VERSION ""

NS_ :

BS_:

BU_: ABS_BASE ATCM_DMSM GENERIC_GWMWakeup PBM IPMB TCU_TBS FDSM GSM TRCM GWM _delete ABS_ESC HUD IPMA CCM SASM PSCM SCCM HCM ATCM SUMA_RLM ATCM_FFSM PCU SECM VDM TBM OCS GENERIC TCCM TSTR RCM

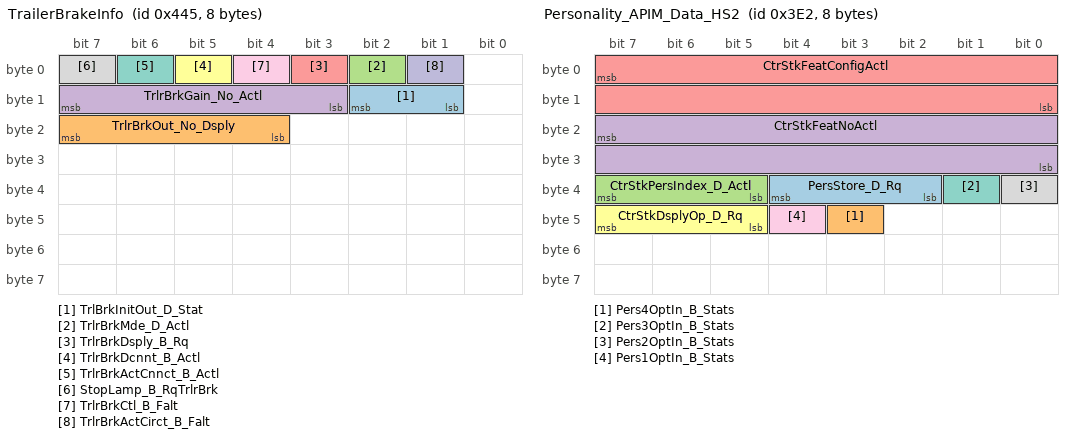
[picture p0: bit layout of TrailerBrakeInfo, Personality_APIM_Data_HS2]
BO_ 1093 TrailerBrakeInfo: 8 TBM
 SG_ TrlBrkInitOut_D_Stat : 10|2@0+ (1,0) [0|3] "SED"  GWM
 SG_ TrlrBrkOut_No_Dsply : 23|4@0+ (1,0) [0|15] "unitless"  GWM
 SG_ TrlrBrkMde_D_Actl : 2|1@0+ (1,0) [0|1] "SED"  GWM,TCCM
 SG_ TrlrBrkGain_No_Actl : 15|5@0+ (0.5,0) [0|15.5] "unitless"  GWM
 SG_ TrlrBrkDsply_B_Rq : 3|1@0+ (1,0) [0|1] "SED"  GWM
 SG_ TrlrBrkDcnnt_B_Actl : 5|1@0+ (1,0) [0|1] "SED"  GWM,VDM
 SG_ TrlrBrkActCnnct_B_Actl : 6|1@0+ (1,0) [0|1] "SED"  ABS_BASE,TCCM,PSCM,SCCM,ABS_ESC,GWM,VDM
 SG_ StopLamp_B_RqTrlrBrk : 7|1@0+ (1,0) [0|1] "SED"  GWM
 SG_ TrlrBrkCtl_B_Falt : 4|1@0+ (1,0) [0|1] "SED"  GWM
 SG_ TrlrBrkActCirct_B_Falt : 1|1@0+ (1,0) [0|1] "SED"  GWM

BO_ 994 Personality_APIM_Data_HS2: 8 GWM
 SG_ PersStore_D_Rq : 36|3@0+ (1,0) [0|7] "SED"  GENERIC
 SG_ Pers4OptIn_B_Stats : 43|1@0+ (1,0) [0|1] "SED"  GENERIC
 SG_ CtrStkPersIndex_D_Actl : 39|3@0+ (1,0) [0|7] "SED"  SASM,CCM,IPMA,IPMB,SCCM,VDM,HCM
 SG_ CtrStkFeatNoActl : 23|16@0+ (1,0) [0|65535] "Undefined"  SASM,CCM,IPMA,IPMB,SCCM,VDM,HCM
 SG_ CtrStkFeatConfigActl : 7|16@0+ (1,0) [0|65535] "Undefined"  SASM,CCM,IPMA,IPMB,SCCM,VDM,HCM
 SG_ CtrStkDsplyOp_D_Rq : 47|3@0+ (1,0) [0|7] "SED"  SASM,CCM,IPMA,IPMB,SCCM,VDM,HCM
 SG_ Pers3OptIn_B_Stats : 33|1@0+ (1,0) [0|1] "SED"  GENERIC
 SG_ Pers2OptIn_B_Stats : 32|1@0+ (1,0) [0|1] "SED"  GENERIC
 SG_ Pers1OptIn_B_Stats : 44|1@0+ (1,0) [0|1] "SED"  GENERIC

BO_ 1836 TesterPhysicalResSCCM: 8 SCCM
 SG_ TesterPhysicalResSCCM : 7|64@0+ (1,0) [0|1.84467E+019] "unitless"  TSTR

BO_ 1978 TesterPhysicalResHUD: 8 HUD
 SG_ TesterPhysicalResHUD : 7|64@0+ (1,0) [0|1.84467E+019] "unitless"  TSTR

BO_ 1825 TesterPhysicalReqVDM: 8 TSTR
 SG_ TesterPhysicalReqVDM : 7|64@0+ (1,0) [0|1.84467E+019] "unitless"  VDM

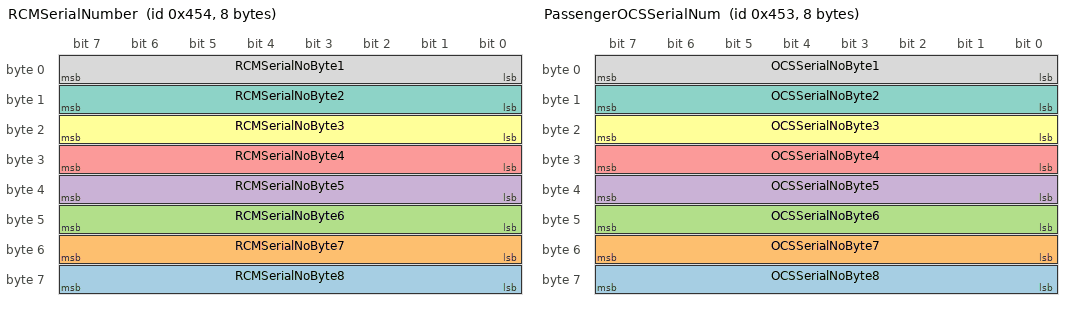
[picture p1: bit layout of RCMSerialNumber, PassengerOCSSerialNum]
BO_ 1108 RCMSerialNumber: 8 RCM
 SG_ RCMSerialNoByte8 : 63|8@0+ (1,0) [0|253] "Unitless"  ABS_BASE,ABS_ESC,OCS
 SG_ RCMSerialNoByte7 : 55|8@0+ (1,0) [0|253] "Unitless"  ABS_BASE,ABS_ESC,OCS
 SG_ RCMSerialNoByte6 : 47|8@0+ (1,0) [0|253] "Unitless"  ABS_BASE,ABS_ESC,OCS
 SG_ RCMSerialNoByte5 : 39|8@0+ (1,0) [0|253] "Unitless"  ABS_BASE,ABS_ESC,OCS
 SG_ RCMSerialNoByte4 : 31|8@0+ (1,0) [0|253] "Unitless"  ABS_BASE,ABS_ESC,OCS
 SG_ RCMSerialNoByte3 : 23|8@0+ (1,0) [0|253] "Unitless"  ABS_BASE,ABS_ESC,OCS
 SG_ RCMSerialNoByte2 : 15|8@0+ (1,0) [0|253] "Unitless"  ABS_BASE,ABS_ESC,OCS
 SG_ RCMSerialNoByte1 : 7|8@0+ (1,0) [0|253] "Unitless"  ABS_BASE,ABS_ESC,OCS

BO_ 1107 PassengerOCSSerialNum: 8 OCS
 SG_ OCSSerialNoByte8 : 63|8@0+ (1,0) [0|253] "Unitless"  RCM
 SG_ OCSSerialNoByte7 : 55|8@0+ (1,0) [0|253] "Unitless"  RCM
 SG_ OCSSerialNoByte6 : 47|8@0+ (1,0) [0|253] "Unitless"  RCM
 SG_ OCSSerialNoByte5 : 39|8@0+ (1,0) [0|253] "Unitless"  RCM
 SG_ OCSSerialNoByte4 : 31|8@0+ (1,0) [0|253] "Unitless"  RCM
 SG_ OCSSerialNoByte3 : 23|8@0+ (1,0) [0|253] "Unitless"  RCM
 SG_ OCSSerialNoByte2 : 15|8@0+ (1,0) [0|253] "Unitless"  RCM
 SG_ OCSSerialNoByte1 : 7|8@0+ (1,0) [0|253] "Unitless"  RCM

BO_ 1848 TesterPhysicalResPSCM: 8 PSCM
 SG_ TesterPhysicalResPSCM : 7|64@0+ (1,0) [0|1.84467E+019] "unitless"  TSTR

BO_ 1900 TesterPhysicalResCCM: 8 IPMA
 SG_ TesterPhysicalResCCM : 7|64@0+ (1,0) [0|1.84467E+019] "unitless"  TSTR

BO_ 1892 TesterPhysicalReqCCM: 8 TSTR
 SG_ TesterPhysicalReqCCM : 7|64@0+ (1,0) [0|1.84467E+019] "unitless"  IPMA,CCM

BO_ 1879 TesterPhysicalReqTBM: 8 TSTR
 SG_ TesterPhysicalReqTBM : 7|64@0+ (1,0) [0|1.84467E+019] "unitless"  TBM

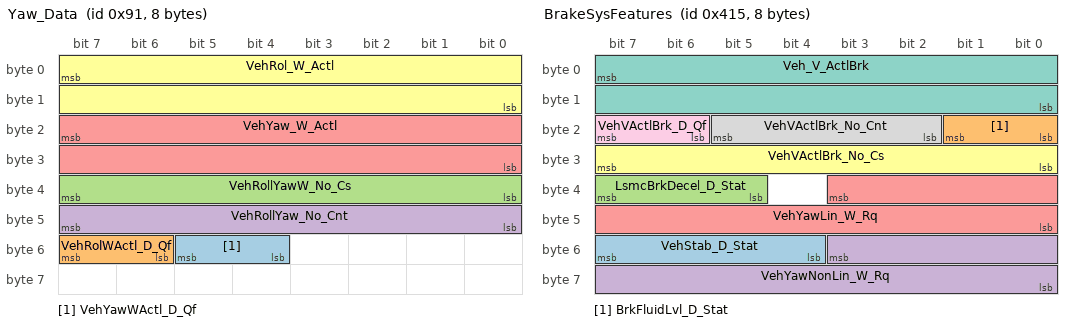
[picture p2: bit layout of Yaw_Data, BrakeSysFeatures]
BO_ 145 Yaw_Data: 8 RCM
 SG_ VehYawWActl_D_Qf : 53|2@0+ (1,0) [0|3] "SED"  HCM,ABS_BASE,GWM,IPMA,VDM,FDSM,ABS_ESC
 SG_ VehRolWActl_D_Qf : 55|2@0+ (1,0) [0|3] "SED"  ABS_BASE,GWM,VDM,ABS_ESC
 SG_ VehRollYawW_No_Cs : 39|8@0+ (1,0) [0|255] "Unitless"  ABS_BASE,GWM,ABS_ESC
 SG_ VehRollYaw_No_Cnt : 47|8@0+ (1,0) [0|255] "Unitless"  ABS_BASE,GWM,VDM,ABS_ESC
 SG_ VehYaw_W_Actl : 23|16@0+ (0.0002,-6.5) [-6.5|6.6066] "rad/s"  ABS_BASE,IPMB,HCM,VDM,PSCM,FDSM,CCM,ABS_ESC,IPMA,GWM
 SG_ VehRol_W_Actl : 7|16@0+ (0.0002,-6.5) [-6.5|6.6066] "rad/s"  ABS_BASE,PSCM,VDM,ABS_ESC,GWM

BO_ 1828 TesterPhysicalReqSCCM: 8 TSTR
 SG_ TesterPhysicalReqSCCM : 7|64@0+ (1,0) [0|1.84467E+019] "unitless"  SCCM

BO_ 1970 TesterPhysicalReqHUD: 8 TSTR
 SG_ TesterPhysicalReqHUD : 7|64@0+ (1,0) [0|1.84467E+019] "unitless"  HUD

BO_ 1045 BrakeSysFeatures: 8 ABS_ESC
 SG_ VehStab_D_Stat : 55|4@0+ (1,0) [0|15] "SED"  TCCM,GWM
 SG_ BrkFluidLvl_D_Stat : 17|2@0+ (1,0) [0|3] "SED"  GWM
 SG_ LsmcBrkDecel_D_Stat : 39|3@0+ (1,0) [0|7] "SED"  GWM,PSCM
 SG_ VehYawNonLin_W_Rq : 51|12@0+ (0.03663,-75) [-75|74.92659] "deg/s"  GWM
 SG_ VehYawLin_W_Rq : 35|12@0+ (0.03663,-75) [-75|74.92659] "deg/s"  GWM
 SG_ VehVActlBrk_No_Cs : 31|8@0+ (1,0) [0|255] "Unitless"  PSCM,SASM,GWM
 SG_ Veh_V_ActlBrk : 7|16@0+ (0.01,0) [0|655.35] "kph"  SCCM,PSCM,SASM,GSM,TRCM,GWM
 SG_ VehVActlBrk_No_Cnt : 21|4@0+ (1,0) [0|15] "Unitless"  PSCM,SASM,GWM
 SG_ VehVActlBrk_D_Qf : 23|2@0+ (1,0) [0|3] "SED"  PSCM,SASM,GSM,TRCM,GWM

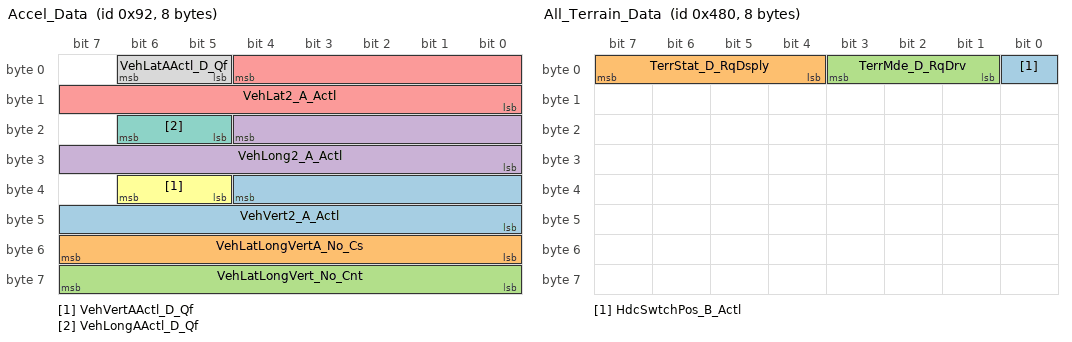
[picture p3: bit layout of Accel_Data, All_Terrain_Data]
BO_ 146 Accel_Data: 8 RCM
 SG_ VehVert2_A_Actl : 36|13@0+ (0.01,-40) [-40|41.89] "m/s^2"  ABS_BASE,ABS_ESC,VDM,GWM
 SG_ VehLatLongVertA_No_Cs : 55|8@0+ (1,0) [0|255] "Unitless"  ABS_BASE,GWM,ABS_ESC,PSCM
 SG_ VehLatLongVert_No_Cnt : 63|8@0+ (1,0) [0|255] "Unitless"  ABS_BASE,GWM,ABS_ESC,PSCM,VDM
 SG_ VehLong2_A_Actl : 20|13@0+ (0.01,-40) [-40|41.89] "m/s^2"  ABS_BASE,GWM,VDM,OCS,IPMA,CCM,ABS_ESC
 SG_ VehLat2_A_Actl : 4|13@0+ (0.01,-40) [-40|41.89] "m/s^2"  ABS_BASE,ABS_ESC,IPMB,CCM,IPMA,OCS,PSCM,VDM,GWM
 SG_ VehVertAActl_D_Qf : 38|2@0+ (1,0) [0|3] "SED"  ABS_ESC,ABS_BASE,GWM,VDM
 SG_ VehLongAActl_D_Qf : 22|2@0+ (1,0) [0|3] "SED"  ABS_BASE,CCM,OCS,VDM,GWM,IPMA,ABS_ESC
 SG_ VehLatAActl_D_Qf : 6|2@0+ (1,0) [0|3] "SED"  ABS_BASE,OCS,VDM,PSCM,IPMA,GWM,ABS_ESC,CCM

BO_ 1152 All_Terrain_Data: 8 ATCM
 SG_ HdcSwtchPos_B_Actl : 0|1@0+ (1,0) [0|1] "SED"  ABS_BASE,ABS_ESC
 SG_ TerrStat_D_RqDsply : 7|4@0+ (1,0) [0|15] "SED"  GWM
 SG_ TerrMde_D_RqDrv : 3|3@0+ (1,0) [0|7] "SED"  ABS_BASE,TCCM,ABS_ESC,GWM

BO_ 1938 TesterPhysicalReqATCM: 8 TSTR
 SG_ TesterPhysicalReqATCM : 7|64@0+ (1,0) [0|1.84467E+019] "unitless"  ATCM_FFSM,ATCM_DMSM,ATCM

BO_ 1888 TesterPhysicalReqABS: 8 TSTR
 SG_ TesterPhysicalReqABS : 7|64@0+ (1,0) [0|1.84467E+019] "unitless"  ABS_BASE,ABS_ESC

BO_ 984 IPMA_Data: 8 IPMA
 SG_ AhbHiBeam_D_Rq : 59|2@0+ (1,0) [0|3] "SED"  GWM,SCCM
 SG_ CadsCamraStat_D_Qf : 61|2@0+ (1,0) [0|3] "SED"  CCM,GWM
 SG_ AhbcStat_B_Dsply : 48|1@0+ (1,0) [0|1] "SED"  GWM
 SG_ LaSwtch_D_RqDrv : 45|1@0+ (1,0) [0|1] "SED"  GWM
 SG_ AhbcHiBeam_D_Rq : 63|2@0+ (1,0) [0|3] "SED"  SCCM,GWM
 SG_ LaSwtchStat_No_Actl : 33|1@0+ (1,0) [0|1] "unitless"  GWM
 SG_ DasWarn_D_Dsply : 44|2@0+ (1,0) [0|3] "SED"  CCM,GWM
 SG_ DasStats_D_Dsply : 47|2@0+ (1,0) [0|3] "SED"  GWM
 SG_ DasAlrtLvl_D_Dsply : 42|3@0+ (1,0) [0|7] "SED"  GWM
 SG_ CamraStats_D_Dsply : 35|2@0+ (1,0) [0|3] "SED"  CCM,GWM
 SG_ CamraDefog_B_Req : 36|1@0+ (1,0) [0|1] "SED"  GWM
 SG_ LaHandsOff_D_Dsply : 50|2@0+ (1,0) [0|3] "SED"  GWM
 SG_ LaDenyStats_B_Dsply : 32|1@0+ (1,0) [0|1] "SED"  GWM
 SG_ LaActvStats_D_Dsply : 55|5@0+ (1,0) [0|31] "SED"  GWM
 SG_ AhbcRampingV_D_Rq : 57|2@0+ (1,0) [0|3] "SED"  HCM,GWM
 SG_ PersIndexIpma_D_Actl : 39|3@0+ (1,0) [0|7] "SED"  GWM
 SG_ FeatNoIpmaActl : 23|16@0+ (1,0) [0|65535] "Number"  GWM
 SG_ FeatConfigIpmaActl : 7|16@0+ (1,0) [0|65535] "Undefined"  GWM

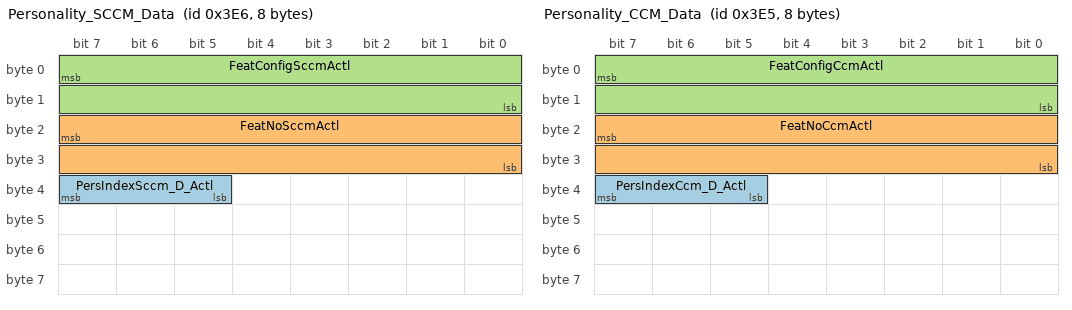
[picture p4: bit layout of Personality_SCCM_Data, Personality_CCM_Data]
BO_ 998 Personality_SCCM_Data: 8 SCCM
 SG_ PersIndexSccm_D_Actl : 39|3@0+ (1,0) [0|7] "SED"  GWM
 SG_ FeatNoSccmActl : 23|16@0+ (1,0) [0|65535] "Number"  GWM
 SG_ FeatConfigSccmActl : 7|16@0+ (1,0) [0|65535] "Undefined"  GWM

BO_ 997 Personality_CCM_Data: 8 IPMA
 SG_ PersIndexCcm_D_Actl : 39|3@0+ (1,0) [0|7] "SED"  HUD,GWM
 SG_ FeatNoCcmActl : 23|16@0+ (1,0) [0|65535] "Number"  HUD,GWM
 SG_ FeatConfigCcmActl : 7|16@0+ (1,0) [0|65535] "Undefined"  HUD,GWM

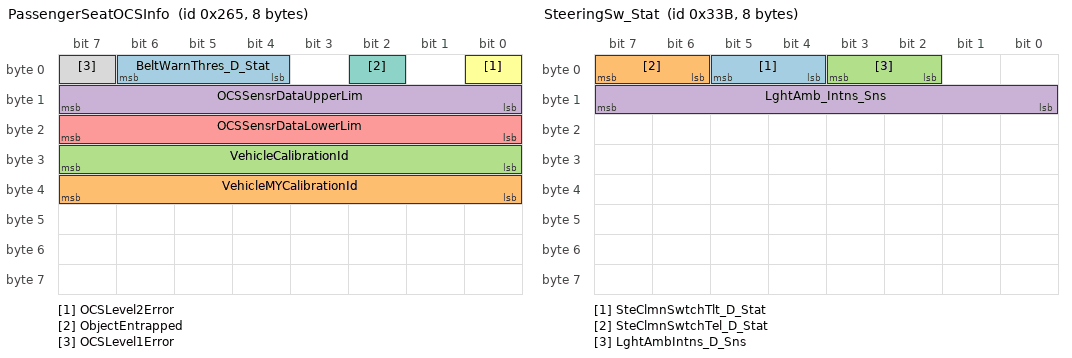
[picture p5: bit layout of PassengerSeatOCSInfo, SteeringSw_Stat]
BO_ 613 PassengerSeatOCSInfo: 8 OCS
 SG_ BeltWarnThres_D_Stat : 6|3@0+ (1,0) [0|7] "SED"  RCM
 SG_ VehicleMYCalibrationId : 39|8@0+ (1,0) [0|254] "SED"  RCM
 SG_ VehicleCalibrationId : 31|8@0+ (1,0) [0|254] "SED"  RCM
 SG_ OCSSensrDataUpperLim : 15|8@0+ (1,0) [0|254] "SED"  GWM,RCM
 SG_ OCSSensrDataLowerLim : 23|8@0+ (1,0) [0|254] "SED"  GWM,RCM
 SG_ OCSLevel2Error : 0|1@0+ (1,0) [0|1] "SED"  RCM
 SG_ ObjectEntrapped : 2|1@0+ (1,0) [0|1] "SED"  GWM
 SG_ OCSLevel1Error : 7|1@0+ (1,0) [0|1] "SED"  RCM

BO_ 1840 TesterPhysicalReqPSCM: 8 TSTR
 SG_ TesterPhysicalReqPSCM : 7|64@0+ (1,0) [0|1.84467E+019] "unitless"  PSCM

BO_ 1664 RCM_Rapid_Data_Response_1: 8 RCM
 SG_ UUDTRCMResponse1 : 7|64@0+ (1,0) [0|1.844674407371E+019] "unitless"  TSTR

BO_ 1814 TesterPhysicalReqGWM_H2: 8 TSTR
 SG_ TesterPhysicalReqGWM_H2 : 7|64@0+ (1,0) [0|1.84467E+019] "unitless"  GWM

BO_ 2033 TesterPhysicalReqPCU: 8 TSTR
 SG_ TesterPhysicalReqPCU : 7|64@0+ (1,0) [0|1.84467E+019] "unitless"  RCM

BO_ 130 EPAS_INFO: 8 PSCM
 SG_ TrlrHitchLamp_D_Rqst : 24|1@0+ (1,0) [0|1] "SED"  GWM,IPMB
 SG_ VehVTrlrAid_B_Rq : 25|1@0+ (1,0) [0|1] "SED"  GWM
 SG_ SteEffort_D_Stat : 52|3@0+ (1,0) [0|7] "SED"  GWM
 SG_ Veh_V_RqMxTrlrAid : 63|8@0+ (0.1,0) [0|25.5] "km/h"  GWM
 SG_ DrvSteActv_B_Stat : 10|1@0+ (1,0) [0|1] "SED"  ABS_BASE,GWM,ABS_ESC
 SG_ DrvSte_Tq_Actl : 47|8@0+ (0.0625,-8) [-8|7.8125] "Nm"  ABS_BASE,ABS_ESC,GWM
 SG_ SteMdule_D_Stat : 55|3@0+ (1,0) [0|7] "SED"  GWM,SASM,SCCM
 SG_ SteMdule_U_Meas : 39|8@0+ (0.05,6) [6|18.7] "Volts"  SASM,GWM
 SG_ SteMdule_I_Est : 21|12@0+ (0.05,-64) [-64|140.7] "Amps"  SASM,GWM
 SG_ EPAS_Failure : 9|2@0+ (1,0) [0|3] "SED"  SASM,GWM
 SG_ SteeringColumnTorque : 7|8@0+ (0.0625,-8) [-8|7.8125] "Nm"  ABS_BASE,ABS_ESC,SCCM,SASM,GWM
 SG_ SAPPAngleControlStat6 : 15|1@0+ (1,0) [0|1] "SED"  GWM
 SG_ SAPPAngleControlStat5 : 14|1@0+ (1,0) [0|1] "SED"  GWM
 SG_ SAPPAngleControlStat4 : 13|1@0+ (1,0) [0|1] "SED"  GWM
 SG_ SAPPAngleControlStat3 : 12|1@0+ (1,0) [0|1] "SED"  GWM
 SG_ SAPPAngleControlStat2 : 11|1@0+ (1,0) [0|1] "SED"  GWM
 SG_ SAPPAngleControlStat1 : 23|2@0+ (1,0) [0|3] "SED"  GWM

BO_ 1855 TesterPhysicalResRCM: 8 RCM
 SG_ TesterPhysicalResRCM : 7|64@0+ (1,0) [0|1.84467E+019] "unitless"  TSTR

BO_ 1847 TesterPhysicalReqRCM: 8 TSTR
 SG_ TesterPhysicalReqRCM : 7|64@0+ (1,0) [0|1.84467E+019] "unitless"  RCM

BO_ 827 SteeringSw_Stat: 8 SCCM
 SG_ SteClmnSwtchTlt_D_Stat : 5|2@0+ (1,0) [0|3] "SED"  GWM
 SG_ SteClmnSwtchTel_D_Stat : 7|2@0+ (1,0) [0|3] "SED"  GWM
 SG_ LghtAmbIntns_D_Sns : 3|2@0+ (1,0) [0|3] "SED"  GWM
 SG_ LghtAmb_Intns_Sns : 15|8@0+ (1,0) [0|255] "unitless"  GWM

BO_ 848 RestraintsData_HS2: 8 GWM
 SG_ RILStat : 7|2@0+ (1,0) [0|3] "SED"  RCM

BO_ 1822 TesterPhysicalResGWM_HS2: 8 GWM
 SG_ TesterPhysicalResGWM_H2 : 7|64@0+ (1,0) [0|1.84467E+019] "unitless"  TSTR

BO_ 1896 TesterPhysicalResABS: 8 ABS_ESC
 SG_ TesterPhysicalResABS : 7|64@0+ (1,0) [0|1.84467E+019] "unitless"  TSTR

BO_ 1901 TesterPhysicalResOCS: 8 OCS
 SG_ TesterPhysicalResOCS : 7|64@0+ (1,0) [0|1.84467E+019] "unitless"  TSTR

BO_ 1893 TesterPhysicalReqOCS: 8 TSTR
 SG_ TesterPhysicalReqOCS : 7|64@0+ (1,0) [0|1.84467E+019] "unitless"  OCS

BO_ 1946 TesterPhysicalResATCM: 8 ATCM
 SG_ TesterPhysicalResATCM : 7|64@0+ (1,0) [0|1.84467E+019] "unitless"  TSTR

BO_ 1887 TesterPhysicalResTBM: 8 TBM
 SG_ TesterPhysicalResTBM : 7|64@0+ (1,0) [0|1.84467E+019] "unitless"  TSTR

BO_ 392 HeadUpDisplayStat: 8 HUD
 SG_ HudShifPoint_N_Actl : 29|6@0+ (100,2000) [2000|8300] "rpm"  GWM
 SG_ HudMde_D_Stat : 18|3@0+ (1,0) [0|7] "SED"  GWM
 SG_ HudLedMde_D_Stat : 31|2@0+ (1,0) [0|3] "SED"  GWM
 SG_ HudLedIntns_Pc_Actl : 39|7@0+ (1,0) [0|127] "percent"  GWM
 SG_ HudLed9On_B_Stat : 12|1@0+ (1,0) [0|1] "SED"  GWM
 SG_ HudLed8On_B_Stat : 13|1@0+ (1,0) [0|1] "SED"  GWM
 SG_ HudLed7On_B_Stat : 14|1@0+ (1,0) [0|1] "SED"  GWM
 SG_ Hud_B_Falt : 5|1@0+ (1,0) [0|1] "SED"  IPMA,GWM,CCM
 SG_ HudActv_B_Actl : 7|1@0+ (1,0) [0|1] "SED"  IPMA,GWM,CCM
 SG_ Hud_B_Avail : 6|1@0+ (1,0) [0|1] "SED"  IPMA,GWM,CCM
 SG_ HudLed6On_B_Stat : 15|1@0+ (1,0) [0|1] "SED"  GWM
 SG_ HudLed5On_B_Stat : 0|1@0+ (1,0) [0|1] "SED"  GWM
 SG_ HudLed4On_B_Stat : 1|1@0+ (1,0) [0|1] "SED"  GWM
 SG_ HudLed3On_B_Stat : 2|1@0+ (1,0) [0|1] "SED"  GWM
 SG_ HudLed2On_B_Stat : 3|1@0+ (1,0) [0|1] "SED"  GWM
 SG_ HudLed1On_B_Stat : 4|1@0+ (1,0) [0|1] "SED"  GWM
 SG_ HudLed18On_B_Stat : 19|1@0+ (1,0) [0|1] "SED"  GWM
 SG_ HudLed17On_B_Stat : 20|1@0+ (1,0) [0|1] "SED"  GWM
 SG_ HudLed16On_B_Stat : 21|1@0+ (1,0) [0|1] "SED"  GWM
 SG_ HudLed15On_B_Stat : 22|1@0+ (1,0) [0|1] "SED"  GWM
 SG_ HudLed14On_B_Stat : 23|1@0+ (1,0) [0|1] "SED"  GWM
 SG_ HudLed13On_B_Stat : 8|1@0+ (1,0) [0|1] "SED"  GWM
 SG_ HudLed12On_B_Stat : 9|1@0+ (1,0) [0|1] "SED"  GWM
 SG_ HudLed11On_B_Stat : 10|1@0+ (1,0) [0|1] "SED"  GWM
 SG_ HudLed10On_B_Stat : 11|1@0+ (1,0) [0|1] "SED"  GWM

BO_TX_BU_ 1900 : CCM,IPMA;
BO_TX_BU_ 1045 : ABS_BASE,ABS_ESC;
BO_TX_BU_ 997 : CCM,IPMA;
BO_TX_BU_ 827 : GENERIC_GWMWakeup,SCCM;
BO_TX_BU_ 1896 : ABS_BASE,ABS_ESC;
BO_TX_BU_ 1946 : ATCM_DMSM,ATCM_FFSM,ATCM;
CM_ SG_ 1093 StopLamp_B_RqTrlrBrk "Signal not transmitted on all variants.";
CM_ SG_ 145 VehYaw_W_Actl "CCMGenSigTimeoutTime=1000";
CM_ BO_ 130 "drecker 10/23/09 Need SAPP in sync w/Strg Torque for proper PAM interpretation, else fault msg's displayed FP@20ms IPC needs EPAS_Failure for msg to driver.  Not map w/Lane Assist FP@30s FP), save bandwidth if feature not on vehicle ";
CM_ SG_ 130 VehVTrlrAid_B_Rq "VR session start- req. limit blower speed no more than X volts.  CC restriction on time msg. will be honored.Double Event msg1st event to request limit, 2nd event to release limit, No msg. CC Grammar v7.xls";
CM_ SG_ 130 SteMdule_U_Meas "DCR 1745  to update Tx from GWM to EP100ms. SteMdule_I_Est & SteMdule_U_Meas are used by BMS system & filtered. The filter uses standard periodic rate & changing to EP would adversely affect the filter.(jweinfur)";
CM_ SG_ 130 SteMdule_I_Est "DCR 1745  to update Tx from GWM to EP100ms. SteMdule_I_Est & SteMdule_U_Meas are used by BMS system & filtered. The filter uses standard periodic rate & changing to EP would adversely affect the filter.(jweinfur)";
CM_ BO_ 827 "MSGDCR 000176 HUD_ADV requested EP 60ms.   ";
BA_DEF_ SG_  "GenSigTimeoutTime_GWM" INT 0 100000;
BA_DEF_ BO_  "FrameGatewayNetwork" STRING ;
BA_DEF_ BO_  "FrameGatewayMS1" HEX 0 1407;
BA_DEF_ BO_  "FrameGatewayHS3" HEX 0 1407;
BA_DEF_ BO_  "FrameGatewayHS1" HEX 0 1407;
BA_DEF_ BO_  "NetworkInitialization" ENUM  "No","Yes";
BA_DEF_ BO_  "FrameGatewayId" HEX 0 1407;
BA_DEF_ BO_  "EventRateOfChange" INT 10 10000;
BA_DEF_ BO_  "GenMsgStartDelayTime" INT 0 10000;
BA_DEF_ BO_  "GenMsgNrOfRepetition" INT 0 100;
BA_DEF_ BO_  "GenMsgDelayTime" INT 0 1000;
BA_DEF_ BO_  "GenMsgCycleTime" INT 0 100000;
BA_DEF_ BO_  "GenMsgSendType" ENUM  "FixedPeriodic","Event","EnabledPeriodic","NotUsed","NotUsed","EventPeriodic","NotUsed","NotUsed","NoMsgSendType";
BA_DEF_ SG_  "U_U611_U625_MY20_Phev_Tx" ENUM  "No","Yes";
BA_DEF_ SG_  "U_CX482_CX483_MY20_Hev_Tx" ENUM  "No","Yes";
BA_DEF_ SG_  "U_CX482_CX483_MY20_Gas_Tx" ENUM  "No","Yes";
BA_DEF_ SG_  "U_CX482_CX483_MY20_Diesel_Tx" ENUM  "No","Yes";
BA_DEF_ SG_  "U_U611_U625_MY20_Hev_Tx" ENUM  "No","Yes";
BA_DEF_ SG_  "U_U611_U625_MY20_Gas_Tx" ENUM  "No","Yes";
BA_DEF_ SG_  "U_U611_U625_MY20_Diesel_Tx" ENUM  "No","Yes";
BA_DEF_ SG_  "U_LC1_B500_MY18_Gas_Tx" ENUM  "No","Yes";
BA_DEF_ SG_  "U_LC1_B500_MY18_Diesel_Tx" ENUM  "No","Yes";
BA_DEF_ SG_  "U_B500_MY18_Diesel_Tx" ENUM  "No","Yes";
BA_DEF_ SG_  "U_B500_MY18_Gas_Tx" ENUM  "No","Yes";
BA_DEF_ SG_  "U_C490_MY18_Tx" ENUM  "No","Yes";
BA_DEF_ SG_  "U_B562_MY18_Gas_Tx" ENUM  "No","Yes";
BA_DEF_ SG_  "U_C519_MY18_5_Gas_Tx" ENUM  "No","Yes";
BA_DEF_ SG_  "U_C519_MY18_5_Diesel_Tx" ENUM  "No","Yes";
BA_DEF_ SG_  "U_B515_MCA_MY17_Gas_Tx" ENUM  "No","Yes";
BA_DEF_ SG_  "U_B515_MCA_MY17_Diesel_Tx" ENUM  "No","Yes";
BA_DEF_ SG_  "U_B479_MY17_Diesel_Tx" ENUM  "No","Yes";
BA_DEF_ SG_  "U_B479_MY17_Gas_Tx" ENUM  "No","Yes";
BA_DEF_ SG_  "U_B562LC_MY15_Gas_Tx" ENUM  "No","Yes";
BA_DEF_ SG_  "U_B562LC_MY15_Diesel_Tx" ENUM  "No","Yes";
BA_DEF_ SG_  "U_U611_U625_MY20_Phev_Rx" ENUM  "No","Yes";
BA_DEF_ SG_  "U_CX482_CX483_MY20_Hev_Rx" ENUM  "No","Yes";
BA_DEF_ SG_  "U_CX482_CX483_MY20_Gas_Rx" ENUM  "No","Yes";
BA_DEF_ SG_  "U_CX482_CX483_MY20_Diesel_Rx" ENUM  "No","Yes";
BA_DEF_ SG_  "U_U611_U625_MY20_Hev_Rx" ENUM  "No","Yes";
BA_DEF_ SG_  "U_U611_U625_MY20_Gas_Rx" ENUM  "No","Yes";
BA_DEF_ SG_  "U_U611_U625_MY20_Diesel_Rx" ENUM  "No","Yes";
BA_DEF_ SG_  "U_B500_MY18_Diesel_Rx" ENUM  "No","Yes";
BA_DEF_ SG_  "U_B500_MY18_Gas_Rx" ENUM  "No","Yes";
BA_DEF_ SG_  "U_C490_MY18_Rx" ENUM  "No","Yes";
BA_DEF_ SG_  "U_B562_MY18_Gas_Rx" ENUM  "No","Yes";
BA_DEF_ SG_  "U_C519_MY18_5_Gas_Rx" ENUM  "No","Yes";
BA_DEF_ SG_  "U_C519_MY18_5_Diesel_Rx" ENUM  "No","Yes";
BA_DEF_ SG_  "U_B515_MCA_MY17_Gas_Rx" ENUM  "No","Yes";
BA_DEF_ SG_  "U_B515_MCA_MY17_Diesel_Rx" ENUM  "No","Yes";
BA_DEF_ SG_  "U_B479_MY17_Diesel_Rx" ENUM  "No","Yes";
BA_DEF_ SG_  "U_B479_MY17_Gas_Rx" ENUM  "No","Yes";
BA_DEF_ SG_  "U_B562LC_MY15_Gas_Rx" ENUM  "No","Yes";
BA_DEF_ SG_  "U_B562LC_MY15_Diesel_Rx" ENUM  "No","Yes";
BA_DEF_ SG_  "ContentDependant" ENUM  "No","Yes";
BA_DEF_ SG_  "GenSigStartValue" INT 0 1000000000;
BA_DEF_ SG_  "UsedOnPgmDBC" ENUM  "No","Yes";
BA_DEF_ SG_  "CrossOver_InfoCAN" ENUM  "No","Yes";
BA_DEF_ SG_  "WakeupSignal" ENUM  "No","Yes";
BA_DEF_ SG_  "GenSigMissingSourceValue" INT 0 1000000000;
BA_DEF_ SG_  "GenSigSendType" ENUM  "Cyclic","OnWrite","vector_leerstring","OnChange","vector_leerstring","IfActive","vector_leerstring","NoSigSendType";
BA_DEF_ BO_  "GenMsgRoutingTimeoutTime" INT 0 1000;
BA_DEF_ BO_  "MessageGateway" ENUM  "No","Yes";
BA_DEF_ BO_  "NmAsrMessage" ENUM  "No","Yes";
BA_DEF_ BO_  "TpApplType" STRING ;
BA_DEF_ BO_  "DiagState" ENUM  "No","Yes";
BA_DEF_ BO_  "DiagRequest" ENUM  "No","Yes";
BA_DEF_ BO_  "DiagResponse" ENUM  "No","Yes";
BA_DEF_ BO_  "GenMsgILSupport" ENUM  "No","Yes";
BA_DEF_DEF_  "GenSigTimeoutTime_GWM" 0;
BA_DEF_DEF_  "FrameGatewayNetwork" "NONE";
BA_DEF_DEF_  "FrameGatewayMS1" 0;
BA_DEF_DEF_  "FrameGatewayHS3" 0;
BA_DEF_DEF_  "FrameGatewayHS1" 0;
BA_DEF_DEF_  "NetworkInitialization" "Yes";
BA_DEF_DEF_  "FrameGatewayId" 0;
BA_DEF_DEF_  "EventRateOfChange" 10000;
BA_DEF_DEF_  "GenMsgStartDelayTime" 0;
BA_DEF_DEF_  "GenMsgNrOfRepetition" 1;
BA_DEF_DEF_  "GenMsgDelayTime" 20;
BA_DEF_DEF_  "GenMsgCycleTime" 0;
BA_DEF_DEF_  "GenMsgSendType" "NoMsgSendType";
BA_DEF_DEF_  "U_U611_U625_MY20_Phev_Tx" "No";
BA_DEF_DEF_  "U_CX482_CX483_MY20_Hev_Tx" "No";
BA_DEF_DEF_  "U_CX482_CX483_MY20_Gas_Tx" "No";
BA_DEF_DEF_  "U_CX482_CX483_MY20_Diesel_Tx" "No";
BA_DEF_DEF_  "U_U611_U625_MY20_Hev_Tx" "No";
BA_DEF_DEF_  "U_U611_U625_MY20_Gas_Tx" "No";
BA_DEF_DEF_  "U_U611_U625_MY20_Diesel_Tx" "No";
BA_DEF_DEF_  "U_LC1_B500_MY18_Gas_Tx" "No";
BA_DEF_DEF_  "U_LC1_B500_MY18_Diesel_Tx" "No";
BA_DEF_DEF_  "U_B500_MY18_Diesel_Tx" "No";
BA_DEF_DEF_  "U_B500_MY18_Gas_Tx" "No";
BA_DEF_DEF_  "U_C490_MY18_Tx" "No";
BA_DEF_DEF_  "U_B562_MY18_Gas_Tx" "No";
BA_DEF_DEF_  "U_C519_MY18_5_Gas_Tx" "No";
BA_DEF_DEF_  "U_C519_MY18_5_Diesel_Tx" "No";
BA_DEF_DEF_  "U_B515_MCA_MY17_Gas_Tx" "No";
BA_DEF_DEF_  "U_B515_MCA_MY17_Diesel_Tx" "No";
BA_DEF_DEF_  "U_B479_MY17_Diesel_Tx" "No";
BA_DEF_DEF_  "U_B479_MY17_Gas_Tx" "No";
BA_DEF_DEF_  "U_B562LC_MY15_Gas_Tx" "No";
BA_DEF_DEF_  "U_B562LC_MY15_Diesel_Tx" "No";
BA_DEF_DEF_  "U_U611_U625_MY20_Phev_Rx" "No";
BA_DEF_DEF_  "U_CX482_CX483_MY20_Hev_Rx" "No";
BA_DEF_DEF_  "U_CX482_CX483_MY20_Gas_Rx" "No";
BA_DEF_DEF_  "U_CX482_CX483_MY20_Diesel_Rx" "No";
BA_DEF_DEF_  "U_U611_U625_MY20_Hev_Rx" "No";
BA_DEF_DEF_  "U_U611_U625_MY20_Gas_Rx" "No";
BA_DEF_DEF_  "U_U611_U625_MY20_Diesel_Rx" "No";
BA_DEF_DEF_  "U_B500_MY18_Diesel_Rx" "No";
BA_DEF_DEF_  "U_B500_MY18_Gas_Rx" "No";
BA_DEF_DEF_  "U_C490_MY18_Rx" "No";
BA_DEF_DEF_  "U_B562_MY18_Gas_Rx" "No";
BA_DEF_DEF_  "U_C519_MY18_5_Gas_Rx" "No";
BA_DEF_DEF_  "U_C519_MY18_5_Diesel_Rx" "No";
BA_DEF_DEF_  "U_B515_MCA_MY17_Gas_Rx" "No";
BA_DEF_DEF_  "U_B515_MCA_MY17_Diesel_Rx" "No";
BA_DEF_DEF_  "U_B479_MY17_Diesel_Rx" "No";
BA_DEF_DEF_  "U_B479_MY17_Gas_Rx" "No";
BA_DEF_DEF_  "U_B562LC_MY15_Gas_Rx" "No";
BA_DEF_DEF_  "U_B562LC_MY15_Diesel_Rx" "No";
BA_DEF_DEF_  "ContentDependant" "No";
BA_DEF_DEF_  "GenSigStartValue" 0;
BA_DEF_DEF_  "UsedOnPgmDBC" "Yes";
BA_DEF_DEF_  "CrossOver_InfoCAN" "No";
BA_DEF_DEF_  "WakeupSignal" "No";
BA_DEF_DEF_  "GenSigMissingSourceValue" 0;
BA_DEF_DEF_  "GenSigSendType" "NoSigSendType";
BA_DEF_DEF_  "GenMsgRoutingTimeoutTime" 0;
BA_DEF_DEF_  "MessageGateway" "No";
BA_DEF_DEF_  "NmAsrMessage" "No";
BA_DEF_DEF_  "TpApplType" "";
BA_DEF_DEF_  "DiagState" "No";
BA_DEF_DEF_  "DiagRequest" "No";
BA_DEF_DEF_  "DiagResponse" "No";
BA_DEF_DEF_  "GenMsgILSupport" "Yes";
BA_ "GenMsgCycleTime" BO_ 1093 100;
BA_ "GenMsgSendType" BO_ 1093 0;
BA_ "FrameGatewayHS3" BO_ 994 987;
BA_ "FrameGatewayHS1" BO_ 994 994;
BA_ "NetworkInitialization" BO_ 1836 0;
BA_ "GenMsgDelayTime" BO_ 1836 0;
BA_ "GenMsgSendType" BO_ 1836 1;
BA_ "DiagResponse" BO_ 1836 1;
BA_ "GenMsgILSupport" BO_ 1836 0;
BA_ "NetworkInitialization" BO_ 1978 0;
BA_ "GenMsgDelayTime" BO_ 1978 0;
BA_ "GenMsgSendType" BO_ 1978 1;
BA_ "DiagResponse" BO_ 1978 1;
BA_ "GenMsgILSupport" BO_ 1978 0;
BA_ "NetworkInitialization" BO_ 1825 0;
BA_ "GenMsgDelayTime" BO_ 1825 0;
BA_ "GenMsgSendType" BO_ 1825 1;
BA_ "DiagRequest" BO_ 1825 1;
BA_ "GenMsgILSupport" BO_ 1825 0;
BA_ "GenMsgCycleTime" BO_ 1108 1000;
BA_ "GenMsgSendType" BO_ 1108 0;
BA_ "GenMsgCycleTime" BO_ 1107 1000;
BA_ "GenMsgSendType" BO_ 1107 0;
BA_ "NetworkInitialization" BO_ 1848 0;
BA_ "GenMsgDelayTime" BO_ 1848 0;
BA_ "GenMsgSendType" BO_ 1848 1;
BA_ "DiagResponse" BO_ 1848 1;
BA_ "GenMsgILSupport" BO_ 1848 0;
BA_ "NetworkInitialization" BO_ 1900 0;
BA_ "GenMsgDelayTime" BO_ 1900 0;
BA_ "GenMsgSendType" BO_ 1900 1;
BA_ "DiagResponse" BO_ 1900 1;
BA_ "GenMsgILSupport" BO_ 1900 0;
BA_ "NetworkInitialization" BO_ 1892 0;
BA_ "GenMsgDelayTime" BO_ 1892 0;
BA_ "GenMsgSendType" BO_ 1892 1;
BA_ "DiagRequest" BO_ 1892 1;
BA_ "GenMsgILSupport" BO_ 1892 0;
BA_ "NetworkInitialization" BO_ 1879 0;
BA_ "GenMsgDelayTime" BO_ 1879 0;
BA_ "GenMsgSendType" BO_ 1879 1;
BA_ "DiagRequest" BO_ 1879 1;
BA_ "GenMsgILSupport" BO_ 1879 0;
BA_ "GenMsgDelayTime" BO_ 145 0;
BA_ "GenMsgCycleTime" BO_ 145 10;
BA_ "GenMsgSendType" BO_ 145 0;
BA_ "NetworkInitialization" BO_ 1828 0;
BA_ "GenMsgDelayTime" BO_ 1828 0;
BA_ "GenMsgSendType" BO_ 1828 1;
BA_ "DiagRequest" BO_ 1828 1;
BA_ "GenMsgILSupport" BO_ 1828 0;
BA_ "NetworkInitialization" BO_ 1970 0;
BA_ "GenMsgDelayTime" BO_ 1970 0;
BA_ "GenMsgSendType" BO_ 1970 1;
BA_ "DiagRequest" BO_ 1970 1;
BA_ "GenMsgILSupport" BO_ 1970 0;
BA_ "GenMsgDelayTime" BO_ 1045 10;
BA_ "GenMsgCycleTime" BO_ 1045 20;
BA_ "GenMsgSendType" BO_ 1045 0;
BA_ "GenMsgDelayTime" BO_ 146 0;
BA_ "GenMsgCycleTime" BO_ 146 10;
BA_ "GenMsgSendType" BO_ 146 0;
BA_ "GenMsgCycleTime" BO_ 1152 100;
BA_ "GenMsgSendType" BO_ 1152 0;
BA_ "NetworkInitialization" BO_ 1938 0;
BA_ "GenMsgDelayTime" BO_ 1938 0;
BA_ "GenMsgSendType" BO_ 1938 1;
BA_ "DiagRequest" BO_ 1938 1;
BA_ "GenMsgILSupport" BO_ 1938 0;
BA_ "NetworkInitialization" BO_ 1888 0;
BA_ "GenMsgDelayTime" BO_ 1888 0;
BA_ "GenMsgSendType" BO_ 1888 1;
BA_ "DiagRequest" BO_ 1888 1;
BA_ "GenMsgILSupport" BO_ 1888 0;
BA_ "GenMsgCycleTime" BO_ 984 1000;
BA_ "GenMsgSendType" BO_ 984 5;
BA_ "GenMsgCycleTime" BO_ 998 1000;
BA_ "GenMsgSendType" BO_ 998 5;
BA_ "GenMsgCycleTime" BO_ 997 1000;
BA_ "GenMsgSendType" BO_ 997 5;
BA_ "GenMsgCycleTime" BO_ 613 1000;
BA_ "GenMsgSendType" BO_ 613 5;
BA_ "NetworkInitialization" BO_ 1840 0;
BA_ "GenMsgDelayTime" BO_ 1840 0;
BA_ "GenMsgSendType" BO_ 1840 1;
BA_ "DiagRequest" BO_ 1840 1;
BA_ "GenMsgILSupport" BO_ 1840 0;
BA_ "NetworkInitialization" BO_ 1664 0;
BA_ "GenMsgSendType" BO_ 1664 1;
BA_ "TpApplType" BO_ 1664 "DiagUUDTResponse";
BA_ "GenMsgILSupport" BO_ 1664 0;
BA_ "NetworkInitialization" BO_ 1814 0;
BA_ "GenMsgDelayTime" BO_ 1814 0;
BA_ "GenMsgSendType" BO_ 1814 1;
BA_ "DiagRequest" BO_ 1814 1;
BA_ "GenMsgILSupport" BO_ 1814 0;
BA_ "NetworkInitialization" BO_ 2033 0;
BA_ "GenMsgDelayTime" BO_ 2033 0;
BA_ "GenMsgSendType" BO_ 2033 1;
BA_ "GenMsgILSupport" BO_ 2033 0;
BA_ "GenMsgDelayTime" BO_ 130 10;
BA_ "GenMsgCycleTime" BO_ 130 20;
BA_ "GenMsgSendType" BO_ 130 0;
BA_ "NetworkInitialization" BO_ 1855 0;
BA_ "GenMsgDelayTime" BO_ 1855 0;
BA_ "GenMsgSendType" BO_ 1855 1;
BA_ "DiagResponse" BO_ 1855 1;
BA_ "GenMsgILSupport" BO_ 1855 0;
BA_ "NetworkInitialization" BO_ 1847 0;
BA_ "GenMsgDelayTime" BO_ 1847 0;
BA_ "GenMsgSendType" BO_ 1847 1;
BA_ "DiagRequest" BO_ 1847 1;
BA_ "GenMsgILSupport" BO_ 1847 0;
BA_ "GenMsgCycleTime" BO_ 827 60;
BA_ "GenMsgSendType" BO_ 827 5;
BA_ "MessageGateway" BO_ 827 1;
BA_ "FrameGatewayNetwork" BO_ 848 "HS3_CAN";
BA_ "FrameGatewayHS3" BO_ 848 848;
BA_ "FrameGatewayId" BO_ 848 848;
BA_ "NetworkInitialization" BO_ 1822 0;
BA_ "GenMsgDelayTime" BO_ 1822 0;
BA_ "GenMsgSendType" BO_ 1822 1;
BA_ "DiagResponse" BO_ 1822 1;
BA_ "GenMsgILSupport" BO_ 1822 0;
BA_ "NetworkInitialization" BO_ 1896 0;
BA_ "GenMsgDelayTime" BO_ 1896 0;
BA_ "GenMsgSendType" BO_ 1896 1;
BA_ "DiagResponse" BO_ 1896 1;
BA_ "GenMsgILSupport" BO_ 1896 0;
BA_ "NetworkInitialization" BO_ 1901 0;
BA_ "GenMsgDelayTime" BO_ 1901 0;
BA_ "GenMsgSendType" BO_ 1901 1;
BA_ "DiagResponse" BO_ 1901 1;
BA_ "GenMsgILSupport" BO_ 1901 0;
BA_ "NetworkInitialization" BO_ 1893 0;
BA_ "GenMsgDelayTime" BO_ 1893 0;
BA_ "GenMsgSendType" BO_ 1893 1;
BA_ "DiagRequest" BO_ 1893 1;
BA_ "GenMsgILSupport" BO_ 1893 0;
BA_ "NetworkInitialization" BO_ 1946 0;
BA_ "GenMsgDelayTime" BO_ 1946 0;
BA_ "GenMsgSendType" BO_ 1946 1;
BA_ "DiagResponse" BO_ 1946 1;
BA_ "GenMsgILSupport" BO_ 1946 0;
BA_ "NetworkInitialization" BO_ 1887 0;
BA_ "GenMsgDelayTime" BO_ 1887 0;
BA_ "GenMsgSendType" BO_ 1887 1;
BA_ "DiagResponse" BO_ 1887 1;
BA_ "GenMsgILSupport" BO_ 1887 0;
BA_ "GenMsgCycleTime" BO_ 392 1000;
BA_ "GenMsgSendType" BO_ 392 5;
BA_ "U_U611_U625_MY20_Phev_Rx" SG_ 1093 TrlrBrkDcnnt_B_Actl 1;
BA_ "U_U611_U625_MY20_Hev_Rx" SG_ 1093 TrlrBrkDcnnt_B_Actl 1;
BA_ "U_U611_U625_MY20_Gas_Rx" SG_ 1093 TrlrBrkDcnnt_B_Actl 1;
BA_ "U_U611_U625_MY20_Diesel_Rx" SG_ 1093 TrlrBrkDcnnt_B_Actl 1;
BA_ "U_U611_U625_MY20_Phev_Rx" SG_ 1093 TrlrBrkActCnnct_B_Actl 1;
BA_ "U_U611_U625_MY20_Hev_Rx" SG_ 1093 TrlrBrkActCnnct_B_Actl 1;
BA_ "U_U611_U625_MY20_Gas_Rx" SG_ 1093 TrlrBrkActCnnct_B_Actl 1;
BA_ "U_U611_U625_MY20_Diesel_Rx" SG_ 1093 TrlrBrkActCnnct_B_Actl 1;
BA_ "U_B515_MCA_MY17_Gas_Rx" SG_ 1093 TrlrBrkActCnnct_B_Actl 1;
BA_ "U_B515_MCA_MY17_Diesel_Rx" SG_ 1093 TrlrBrkActCnnct_B_Actl 1;
BA_ "U_B479_MY17_Diesel_Rx" SG_ 1093 TrlrBrkActCnnct_B_Actl 1;
BA_ "U_B479_MY17_Gas_Rx" SG_ 1093 TrlrBrkActCnnct_B_Actl 1;
BA_ "ContentDependant" SG_ 1093 StopLamp_B_RqTrlrBrk 1;
BA_ "CrossOver_InfoCAN" SG_ 994 PersStore_D_Rq 1;
BA_ "CrossOver_InfoCAN" SG_ 994 Pers4OptIn_B_Stats 1;
BA_ "U_U611_U625_MY20_Phev_Rx" SG_ 994 CtrStkPersIndex_D_Actl 1;
BA_ "U_CX482_CX483_MY20_Hev_Rx" SG_ 994 CtrStkPersIndex_D_Actl 1;
BA_ "U_CX482_CX483_MY20_Gas_Rx" SG_ 994 CtrStkPersIndex_D_Actl 1;
BA_ "U_CX482_CX483_MY20_Diesel_Rx" SG_ 994 CtrStkPersIndex_D_Actl 1;
BA_ "U_U611_U625_MY20_Hev_Rx" SG_ 994 CtrStkPersIndex_D_Actl 1;
BA_ "U_U611_U625_MY20_Gas_Rx" SG_ 994 CtrStkPersIndex_D_Actl 1;
BA_ "U_U611_U625_MY20_Diesel_Rx" SG_ 994 CtrStkPersIndex_D_Actl 1;
BA_ "U_B500_MY18_Diesel_Rx" SG_ 994 CtrStkPersIndex_D_Actl 1;
BA_ "U_B500_MY18_Gas_Rx" SG_ 994 CtrStkPersIndex_D_Actl 1;
BA_ "U_C519_MY18_5_Gas_Rx" SG_ 994 CtrStkPersIndex_D_Actl 1;
BA_ "U_C519_MY18_5_Diesel_Rx" SG_ 994 CtrStkPersIndex_D_Actl 1;
BA_ "GenSigStartValue" SG_ 994 CtrStkPersIndex_D_Actl 4;
BA_ "CrossOver_InfoCAN" SG_ 994 CtrStkPersIndex_D_Actl 1;
BA_ "U_U611_U625_MY20_Phev_Rx" SG_ 994 CtrStkFeatNoActl 1;
BA_ "U_CX482_CX483_MY20_Hev_Rx" SG_ 994 CtrStkFeatNoActl 1;
BA_ "U_CX482_CX483_MY20_Gas_Rx" SG_ 994 CtrStkFeatNoActl 1;
BA_ "U_CX482_CX483_MY20_Diesel_Rx" SG_ 994 CtrStkFeatNoActl 1;
BA_ "U_U611_U625_MY20_Hev_Rx" SG_ 994 CtrStkFeatNoActl 1;
BA_ "U_U611_U625_MY20_Gas_Rx" SG_ 994 CtrStkFeatNoActl 1;
BA_ "U_U611_U625_MY20_Diesel_Rx" SG_ 994 CtrStkFeatNoActl 1;
BA_ "U_B500_MY18_Diesel_Rx" SG_ 994 CtrStkFeatNoActl 1;
BA_ "U_B500_MY18_Gas_Rx" SG_ 994 CtrStkFeatNoActl 1;
BA_ "U_C519_MY18_5_Gas_Rx" SG_ 994 CtrStkFeatNoActl 1;
BA_ "U_C519_MY18_5_Diesel_Rx" SG_ 994 CtrStkFeatNoActl 1;
BA_ "CrossOver_InfoCAN" SG_ 994 CtrStkFeatNoActl 1;
BA_ "U_U611_U625_MY20_Phev_Rx" SG_ 994 CtrStkFeatConfigActl 1;
BA_ "U_CX482_CX483_MY20_Hev_Rx" SG_ 994 CtrStkFeatConfigActl 1;
BA_ "U_CX482_CX483_MY20_Gas_Rx" SG_ 994 CtrStkFeatConfigActl 1;
BA_ "U_CX482_CX483_MY20_Diesel_Rx" SG_ 994 CtrStkFeatConfigActl 1;
BA_ "U_U611_U625_MY20_Hev_Rx" SG_ 994 CtrStkFeatConfigActl 1;
BA_ "U_U611_U625_MY20_Gas_Rx" SG_ 994 CtrStkFeatConfigActl 1;
BA_ "U_U611_U625_MY20_Diesel_Rx" SG_ 994 CtrStkFeatConfigActl 1;
BA_ "U_B500_MY18_Diesel_Rx" SG_ 994 CtrStkFeatConfigActl 1;
BA_ "U_B500_MY18_Gas_Rx" SG_ 994 CtrStkFeatConfigActl 1;
BA_ "U_C519_MY18_5_Gas_Rx" SG_ 994 CtrStkFeatConfigActl 1;
BA_ "U_C519_MY18_5_Diesel_Rx" SG_ 994 CtrStkFeatConfigActl 1;
BA_ "CrossOver_InfoCAN" SG_ 994 CtrStkFeatConfigActl 1;
BA_ "U_U611_U625_MY20_Phev_Rx" SG_ 994 CtrStkDsplyOp_D_Rq 1;
BA_ "U_CX482_CX483_MY20_Hev_Rx" SG_ 994 CtrStkDsplyOp_D_Rq 1;
BA_ "U_CX482_CX483_MY20_Gas_Rx" SG_ 994 CtrStkDsplyOp_D_Rq 1;
BA_ "U_CX482_CX483_MY20_Diesel_Rx" SG_ 994 CtrStkDsplyOp_D_Rq 1;
BA_ "U_U611_U625_MY20_Hev_Rx" SG_ 994 CtrStkDsplyOp_D_Rq 1;
BA_ "U_U611_U625_MY20_Gas_Rx" SG_ 994 CtrStkDsplyOp_D_Rq 1;
BA_ "U_U611_U625_MY20_Diesel_Rx" SG_ 994 CtrStkDsplyOp_D_Rq 1;
BA_ "U_B500_MY18_Diesel_Rx" SG_ 994 CtrStkDsplyOp_D_Rq 1;
BA_ "U_B500_MY18_Gas_Rx" SG_ 994 CtrStkDsplyOp_D_Rq 1;
BA_ "U_C519_MY18_5_Gas_Rx" SG_ 994 CtrStkDsplyOp_D_Rq 1;
BA_ "U_C519_MY18_5_Diesel_Rx" SG_ 994 CtrStkDsplyOp_D_Rq 1;
BA_ "CrossOver_InfoCAN" SG_ 994 CtrStkDsplyOp_D_Rq 1;
BA_ "CrossOver_InfoCAN" SG_ 994 Pers3OptIn_B_Stats 1;
BA_ "CrossOver_InfoCAN" SG_ 994 Pers2OptIn_B_Stats 1;
BA_ "CrossOver_InfoCAN" SG_ 994 Pers1OptIn_B_Stats 1;
BA_ "U_U611_U625_MY20_Phev_Tx" SG_ 1836 TesterPhysicalResSCCM 1;
BA_ "U_CX482_CX483_MY20_Hev_Tx" SG_ 1836 TesterPhysicalResSCCM 1;
BA_ "U_CX482_CX483_MY20_Gas_Tx" SG_ 1836 TesterPhysicalResSCCM 1;
BA_ "U_CX482_CX483_MY20_Diesel_Tx" SG_ 1836 TesterPhysicalResSCCM 1;
BA_ "U_U611_U625_MY20_Hev_Tx" SG_ 1836 TesterPhysicalResSCCM 1;
BA_ "U_U611_U625_MY20_Gas_Tx" SG_ 1836 TesterPhysicalResSCCM 1;
BA_ "U_U611_U625_MY20_Diesel_Tx" SG_ 1836 TesterPhysicalResSCCM 1;
BA_ "U_B500_MY18_Diesel_Tx" SG_ 1836 TesterPhysicalResSCCM 1;
BA_ "U_B500_MY18_Gas_Tx" SG_ 1836 TesterPhysicalResSCCM 1;
BA_ "U_C519_MY18_5_Gas_Tx" SG_ 1836 TesterPhysicalResSCCM 1;
BA_ "U_C519_MY18_5_Diesel_Tx" SG_ 1836 TesterPhysicalResSCCM 1;
BA_ "U_B515_MCA_MY17_Gas_Tx" SG_ 1836 TesterPhysicalResSCCM 1;
BA_ "U_B515_MCA_MY17_Diesel_Tx" SG_ 1836 TesterPhysicalResSCCM 1;
BA_ "U_B479_MY17_Diesel_Tx" SG_ 1836 TesterPhysicalResSCCM 1;
BA_ "U_B479_MY17_Gas_Tx" SG_ 1836 TesterPhysicalResSCCM 1;
BA_ "GenSigSendType" SG_ 1836 TesterPhysicalResSCCM 3;
BA_ "U_U611_U625_MY20_Phev_Tx" SG_ 1978 TesterPhysicalResHUD 1;
BA_ "U_U611_U625_MY20_Hev_Tx" SG_ 1978 TesterPhysicalResHUD 1;
BA_ "U_U611_U625_MY20_Gas_Tx" SG_ 1978 TesterPhysicalResHUD 1;
BA_ "U_U611_U625_MY20_Diesel_Tx" SG_ 1978 TesterPhysicalResHUD 1;
BA_ "GenSigSendType" SG_ 1978 TesterPhysicalResHUD 3;
BA_ "U_U611_U625_MY20_Phev_Rx" SG_ 1825 TesterPhysicalReqVDM 1;
BA_ "U_U611_U625_MY20_Hev_Rx" SG_ 1825 TesterPhysicalReqVDM 1;
BA_ "U_U611_U625_MY20_Gas_Rx" SG_ 1825 TesterPhysicalReqVDM 1;
BA_ "U_U611_U625_MY20_Diesel_Rx" SG_ 1825 TesterPhysicalReqVDM 1;
BA_ "U_C519_MY18_5_Gas_Rx" SG_ 1825 TesterPhysicalReqVDM 1;
BA_ "U_C519_MY18_5_Diesel_Rx" SG_ 1825 TesterPhysicalReqVDM 1;
BA_ "GenSigSendType" SG_ 1825 TesterPhysicalReqVDM 3;
BA_ "U_CX482_CX483_MY20_Hev_Tx" SG_ 1108 RCMSerialNoByte8 1;
BA_ "U_CX482_CX483_MY20_Gas_Tx" SG_ 1108 RCMSerialNoByte8 1;
BA_ "U_CX482_CX483_MY20_Diesel_Tx" SG_ 1108 RCMSerialNoByte8 1;
BA_ "U_U611_U625_MY20_Hev_Tx" SG_ 1108 RCMSerialNoByte8 1;
BA_ "U_U611_U625_MY20_Gas_Tx" SG_ 1108 RCMSerialNoByte8 1;
BA_ "U_U611_U625_MY20_Diesel_Tx" SG_ 1108 RCMSerialNoByte8 1;
BA_ "U_B500_MY18_Diesel_Tx" SG_ 1108 RCMSerialNoByte8 1;
BA_ "U_B500_MY18_Gas_Tx" SG_ 1108 RCMSerialNoByte8 1;
BA_ "U_C490_MY18_Tx" SG_ 1108 RCMSerialNoByte8 1;
BA_ "U_B562_MY18_Gas_Tx" SG_ 1108 RCMSerialNoByte8 1;
BA_ "U_C519_MY18_5_Gas_Tx" SG_ 1108 RCMSerialNoByte8 1;
BA_ "U_C519_MY18_5_Diesel_Tx" SG_ 1108 RCMSerialNoByte8 1;
BA_ "U_B515_MCA_MY17_Gas_Tx" SG_ 1108 RCMSerialNoByte8 1;
BA_ "U_B515_MCA_MY17_Diesel_Tx" SG_ 1108 RCMSerialNoByte8 1;
BA_ "U_B479_MY17_Diesel_Tx" SG_ 1108 RCMSerialNoByte8 1;
BA_ "U_B479_MY17_Gas_Tx" SG_ 1108 RCMSerialNoByte8 1;
BA_ "U_B562LC_MY15_Gas_Tx" SG_ 1108 RCMSerialNoByte8 1;
BA_ "U_B500_MY18_Diesel_Rx" SG_ 1108 RCMSerialNoByte8 1;
BA_ "U_B500_MY18_Gas_Rx" SG_ 1108 RCMSerialNoByte8 1;
BA_ "U_C490_MY18_Rx" SG_ 1108 RCMSerialNoByte8 1;
BA_ "U_B562_MY18_Gas_Rx" SG_ 1108 RCMSerialNoByte8 1;
BA_ "U_U611_U625_MY20_Phev_Rx" SG_ 1108 RCMSerialNoByte8 1;
BA_ "U_CX482_CX483_MY20_Hev_Rx" SG_ 1108 RCMSerialNoByte8 1;
BA_ "U_CX482_CX483_MY20_Gas_Rx" SG_ 1108 RCMSerialNoByte8 1;
BA_ "U_CX482_CX483_MY20_Diesel_Rx" SG_ 1108 RCMSerialNoByte8 1;
BA_ "U_U611_U625_MY20_Hev_Rx" SG_ 1108 RCMSerialNoByte8 1;
BA_ "U_U611_U625_MY20_Gas_Rx" SG_ 1108 RCMSerialNoByte8 1;
BA_ "U_U611_U625_MY20_Diesel_Rx" SG_ 1108 RCMSerialNoByte8 1;
BA_ "U_C519_MY18_5_Gas_Rx" SG_ 1108 RCMSerialNoByte8 1;
BA_ "U_C519_MY18_5_Diesel_Rx" SG_ 1108 RCMSerialNoByte8 1;
BA_ "U_B515_MCA_MY17_Gas_Rx" SG_ 1108 RCMSerialNoByte8 1;
BA_ "U_B515_MCA_MY17_Diesel_Rx" SG_ 1108 RCMSerialNoByte8 1;
BA_ "U_B479_MY17_Diesel_Rx" SG_ 1108 RCMSerialNoByte8 1;
BA_ "U_B479_MY17_Gas_Rx" SG_ 1108 RCMSerialNoByte8 1;
BA_ "U_CX482_CX483_MY20_Hev_Tx" SG_ 1108 RCMSerialNoByte7 1;
BA_ "U_CX482_CX483_MY20_Gas_Tx" SG_ 1108 RCMSerialNoByte7 1;
BA_ "U_CX482_CX483_MY20_Diesel_Tx" SG_ 1108 RCMSerialNoByte7 1;
BA_ "U_U611_U625_MY20_Hev_Tx" SG_ 1108 RCMSerialNoByte7 1;
BA_ "U_U611_U625_MY20_Gas_Tx" SG_ 1108 RCMSerialNoByte7 1;
BA_ "U_U611_U625_MY20_Diesel_Tx" SG_ 1108 RCMSerialNoByte7 1;
BA_ "U_B500_MY18_Diesel_Tx" SG_ 1108 RCMSerialNoByte7 1;
BA_ "U_B500_MY18_Gas_Tx" SG_ 1108 RCMSerialNoByte7 1;
BA_ "U_C490_MY18_Tx" SG_ 1108 RCMSerialNoByte7 1;
BA_ "U_B562_MY18_Gas_Tx" SG_ 1108 RCMSerialNoByte7 1;
BA_ "U_C519_MY18_5_Gas_Tx" SG_ 1108 RCMSerialNoByte7 1;
BA_ "U_C519_MY18_5_Diesel_Tx" SG_ 1108 RCMSerialNoByte7 1;
BA_ "U_B515_MCA_MY17_Gas_Tx" SG_ 1108 RCMSerialNoByte7 1;
BA_ "U_B515_MCA_MY17_Diesel_Tx" SG_ 1108 RCMSerialNoByte7 1;
BA_ "U_B479_MY17_Diesel_Tx" SG_ 1108 RCMSerialNoByte7 1;
BA_ "U_B479_MY17_Gas_Tx" SG_ 1108 RCMSerialNoByte7 1;
BA_ "U_B562LC_MY15_Gas_Tx" SG_ 1108 RCMSerialNoByte7 1;
BA_ "U_B500_MY18_Diesel_Rx" SG_ 1108 RCMSerialNoByte7 1;
BA_ "U_B500_MY18_Gas_Rx" SG_ 1108 RCMSerialNoByte7 1;
BA_ "U_C490_MY18_Rx" SG_ 1108 RCMSerialNoByte7 1;
BA_ "U_B562_MY18_Gas_Rx" SG_ 1108 RCMSerialNoByte7 1;
BA_ "U_U611_U625_MY20_Phev_Rx" SG_ 1108 RCMSerialNoByte7 1;
BA_ "U_CX482_CX483_MY20_Hev_Rx" SG_ 1108 RCMSerialNoByte7 1;
BA_ "U_CX482_CX483_MY20_Gas_Rx" SG_ 1108 RCMSerialNoByte7 1;
BA_ "U_CX482_CX483_MY20_Diesel_Rx" SG_ 1108 RCMSerialNoByte7 1;
BA_ "U_U611_U625_MY20_Hev_Rx" SG_ 1108 RCMSerialNoByte7 1;
BA_ "U_U611_U625_MY20_Gas_Rx" SG_ 1108 RCMSerialNoByte7 1;
BA_ "U_U611_U625_MY20_Diesel_Rx" SG_ 1108 RCMSerialNoByte7 1;
BA_ "U_C519_MY18_5_Gas_Rx" SG_ 1108 RCMSerialNoByte7 1;
BA_ "U_C519_MY18_5_Diesel_Rx" SG_ 1108 RCMSerialNoByte7 1;
BA_ "U_B515_MCA_MY17_Gas_Rx" SG_ 1108 RCMSerialNoByte7 1;
BA_ "U_B515_MCA_MY17_Diesel_Rx" SG_ 1108 RCMSerialNoByte7 1;
BA_ "U_B479_MY17_Diesel_Rx" SG_ 1108 RCMSerialNoByte7 1;
BA_ "U_B479_MY17_Gas_Rx" SG_ 1108 RCMSerialNoByte7 1;
BA_ "U_CX482_CX483_MY20_Hev_Tx" SG_ 1108 RCMSerialNoByte6 1;
BA_ "U_CX482_CX483_MY20_Gas_Tx" SG_ 1108 RCMSerialNoByte6 1;
BA_ "U_CX482_CX483_MY20_Diesel_Tx" SG_ 1108 RCMSerialNoByte6 1;
BA_ "U_U611_U625_MY20_Hev_Tx" SG_ 1108 RCMSerialNoByte6 1;
BA_ "U_U611_U625_MY20_Gas_Tx" SG_ 1108 RCMSerialNoByte6 1;
BA_ "U_U611_U625_MY20_Diesel_Tx" SG_ 1108 RCMSerialNoByte6 1;
BA_ "U_B500_MY18_Diesel_Tx" SG_ 1108 RCMSerialNoByte6 1;
BA_ "U_B500_MY18_Gas_Tx" SG_ 1108 RCMSerialNoByte6 1;
BA_ "U_C490_MY18_Tx" SG_ 1108 RCMSerialNoByte6 1;
BA_ "U_B562_MY18_Gas_Tx" SG_ 1108 RCMSerialNoByte6 1;
BA_ "U_C519_MY18_5_Gas_Tx" SG_ 1108 RCMSerialNoByte6 1;
BA_ "U_C519_MY18_5_Diesel_Tx" SG_ 1108 RCMSerialNoByte6 1;
BA_ "U_B515_MCA_MY17_Gas_Tx" SG_ 1108 RCMSerialNoByte6 1;
BA_ "U_B515_MCA_MY17_Diesel_Tx" SG_ 1108 RCMSerialNoByte6 1;
BA_ "U_B479_MY17_Diesel_Tx" SG_ 1108 RCMSerialNoByte6 1;
BA_ "U_B479_MY17_Gas_Tx" SG_ 1108 RCMSerialNoByte6 1;
BA_ "U_B562LC_MY15_Gas_Tx" SG_ 1108 RCMSerialNoByte6 1;
BA_ "U_B500_MY18_Diesel_Rx" SG_ 1108 RCMSerialNoByte6 1;
BA_ "U_B500_MY18_Gas_Rx" SG_ 1108 RCMSerialNoByte6 1;
BA_ "U_C490_MY18_Rx" SG_ 1108 RCMSerialNoByte6 1;
BA_ "U_B562_MY18_Gas_Rx" SG_ 1108 RCMSerialNoByte6 1;
BA_ "U_U611_U625_MY20_Phev_Rx" SG_ 1108 RCMSerialNoByte6 1;
BA_ "U_CX482_CX483_MY20_Hev_Rx" SG_ 1108 RCMSerialNoByte6 1;
BA_ "U_CX482_CX483_MY20_Gas_Rx" SG_ 1108 RCMSerialNoByte6 1;
BA_ "U_CX482_CX483_MY20_Diesel_Rx" SG_ 1108 RCMSerialNoByte6 1;
BA_ "U_U611_U625_MY20_Hev_Rx" SG_ 1108 RCMSerialNoByte6 1;
BA_ "U_U611_U625_MY20_Gas_Rx" SG_ 1108 RCMSerialNoByte6 1;
BA_ "U_U611_U625_MY20_Diesel_Rx" SG_ 1108 RCMSerialNoByte6 1;
BA_ "U_C519_MY18_5_Gas_Rx" SG_ 1108 RCMSerialNoByte6 1;
BA_ "U_C519_MY18_5_Diesel_Rx" SG_ 1108 RCMSerialNoByte6 1;
BA_ "U_B515_MCA_MY17_Gas_Rx" SG_ 1108 RCMSerialNoByte6 1;
BA_ "U_B515_MCA_MY17_Diesel_Rx" SG_ 1108 RCMSerialNoByte6 1;
BA_ "U_B479_MY17_Diesel_Rx" SG_ 1108 RCMSerialNoByte6 1;
BA_ "U_B479_MY17_Gas_Rx" SG_ 1108 RCMSerialNoByte6 1;
BA_ "U_CX482_CX483_MY20_Hev_Tx" SG_ 1108 RCMSerialNoByte5 1;
BA_ "U_CX482_CX483_MY20_Gas_Tx" SG_ 1108 RCMSerialNoByte5 1;
BA_ "U_CX482_CX483_MY20_Diesel_Tx" SG_ 1108 RCMSerialNoByte5 1;
BA_ "U_U611_U625_MY20_Hev_Tx" SG_ 1108 RCMSerialNoByte5 1;
BA_ "U_U611_U625_MY20_Gas_Tx" SG_ 1108 RCMSerialNoByte5 1;
BA_ "U_U611_U625_MY20_Diesel_Tx" SG_ 1108 RCMSerialNoByte5 1;
BA_ "U_B500_MY18_Diesel_Tx" SG_ 1108 RCMSerialNoByte5 1;
BA_ "U_B500_MY18_Gas_Tx" SG_ 1108 RCMSerialNoByte5 1;
BA_ "U_C490_MY18_Tx" SG_ 1108 RCMSerialNoByte5 1;
BA_ "U_B562_MY18_Gas_Tx" SG_ 1108 RCMSerialNoByte5 1;
BA_ "U_C519_MY18_5_Gas_Tx" SG_ 1108 RCMSerialNoByte5 1;
BA_ "U_C519_MY18_5_Diesel_Tx" SG_ 1108 RCMSerialNoByte5 1;
BA_ "U_B515_MCA_MY17_Gas_Tx" SG_ 1108 RCMSerialNoByte5 1;
BA_ "U_B515_MCA_MY17_Diesel_Tx" SG_ 1108 RCMSerialNoByte5 1;
BA_ "U_B479_MY17_Diesel_Tx" SG_ 1108 RCMSerialNoByte5 1;
BA_ "U_B479_MY17_Gas_Tx" SG_ 1108 RCMSerialNoByte5 1;
BA_ "U_B562LC_MY15_Gas_Tx" SG_ 1108 RCMSerialNoByte5 1;
BA_ "U_B500_MY18_Diesel_Rx" SG_ 1108 RCMSerialNoByte5 1;
BA_ "U_B500_MY18_Gas_Rx" SG_ 1108 RCMSerialNoByte5 1;
BA_ "U_C490_MY18_Rx" SG_ 1108 RCMSerialNoByte5 1;
BA_ "U_B562_MY18_Gas_Rx" SG_ 1108 RCMSerialNoByte5 1;
BA_ "U_U611_U625_MY20_Phev_Rx" SG_ 1108 RCMSerialNoByte5 1;
BA_ "U_CX482_CX483_MY20_Hev_Rx" SG_ 1108 RCMSerialNoByte5 1;
BA_ "U_CX482_CX483_MY20_Gas_Rx" SG_ 1108 RCMSerialNoByte5 1;
BA_ "U_CX482_CX483_MY20_Diesel_Rx" SG_ 1108 RCMSerialNoByte5 1;
BA_ "U_U611_U625_MY20_Hev_Rx" SG_ 1108 RCMSerialNoByte5 1;
BA_ "U_U611_U625_MY20_Gas_Rx" SG_ 1108 RCMSerialNoByte5 1;
BA_ "U_U611_U625_MY20_Diesel_Rx" SG_ 1108 RCMSerialNoByte5 1;
BA_ "U_C519_MY18_5_Gas_Rx" SG_ 1108 RCMSerialNoByte5 1;
BA_ "U_C519_MY18_5_Diesel_Rx" SG_ 1108 RCMSerialNoByte5 1;
BA_ "U_B515_MCA_MY17_Gas_Rx" SG_ 1108 RCMSerialNoByte5 1;
BA_ "U_B515_MCA_MY17_Diesel_Rx" SG_ 1108 RCMSerialNoByte5 1;
BA_ "U_B479_MY17_Diesel_Rx" SG_ 1108 RCMSerialNoByte5 1;
BA_ "U_B479_MY17_Gas_Rx" SG_ 1108 RCMSerialNoByte5 1;
BA_ "U_CX482_CX483_MY20_Hev_Tx" SG_ 1108 RCMSerialNoByte4 1;
BA_ "U_CX482_CX483_MY20_Gas_Tx" SG_ 1108 RCMSerialNoByte4 1;
BA_ "U_CX482_CX483_MY20_Diesel_Tx" SG_ 1108 RCMSerialNoByte4 1;
BA_ "U_U611_U625_MY20_Hev_Tx" SG_ 1108 RCMSerialNoByte4 1;
BA_ "U_U611_U625_MY20_Gas_Tx" SG_ 1108 RCMSerialNoByte4 1;
BA_ "U_U611_U625_MY20_Diesel_Tx" SG_ 1108 RCMSerialNoByte4 1;
BA_ "U_B500_MY18_Diesel_Tx" SG_ 1108 RCMSerialNoByte4 1;
BA_ "U_B500_MY18_Gas_Tx" SG_ 1108 RCMSerialNoByte4 1;
BA_ "U_C490_MY18_Tx" SG_ 1108 RCMSerialNoByte4 1;
BA_ "U_B562_MY18_Gas_Tx" SG_ 1108 RCMSerialNoByte4 1;
BA_ "U_C519_MY18_5_Gas_Tx" SG_ 1108 RCMSerialNoByte4 1;
BA_ "U_C519_MY18_5_Diesel_Tx" SG_ 1108 RCMSerialNoByte4 1;
BA_ "U_B515_MCA_MY17_Gas_Tx" SG_ 1108 RCMSerialNoByte4 1;
BA_ "U_B515_MCA_MY17_Diesel_Tx" SG_ 1108 RCMSerialNoByte4 1;
BA_ "U_B479_MY17_Diesel_Tx" SG_ 1108 RCMSerialNoByte4 1;
BA_ "U_B479_MY17_Gas_Tx" SG_ 1108 RCMSerialNoByte4 1;
BA_ "U_B562LC_MY15_Gas_Tx" SG_ 1108 RCMSerialNoByte4 1;
BA_ "U_B500_MY18_Diesel_Rx" SG_ 1108 RCMSerialNoByte4 1;
BA_ "U_B500_MY18_Gas_Rx" SG_ 1108 RCMSerialNoByte4 1;
BA_ "U_C490_MY18_Rx" SG_ 1108 RCMSerialNoByte4 1;
BA_ "U_B562_MY18_Gas_Rx" SG_ 1108 RCMSerialNoByte4 1;
BA_ "U_U611_U625_MY20_Phev_Rx" SG_ 1108 RCMSerialNoByte4 1;
BA_ "U_CX482_CX483_MY20_Hev_Rx" SG_ 1108 RCMSerialNoByte4 1;
BA_ "U_CX482_CX483_MY20_Gas_Rx" SG_ 1108 RCMSerialNoByte4 1;
BA_ "U_CX482_CX483_MY20_Diesel_Rx" SG_ 1108 RCMSerialNoByte4 1;
BA_ "U_U611_U625_MY20_Hev_Rx" SG_ 1108 RCMSerialNoByte4 1;
BA_ "U_U611_U625_MY20_Gas_Rx" SG_ 1108 RCMSerialNoByte4 1;
BA_ "U_U611_U625_MY20_Diesel_Rx" SG_ 1108 RCMSerialNoByte4 1;
BA_ "U_C519_MY18_5_Gas_Rx" SG_ 1108 RCMSerialNoByte4 1;
BA_ "U_C519_MY18_5_Diesel_Rx" SG_ 1108 RCMSerialNoByte4 1;
BA_ "U_B515_MCA_MY17_Gas_Rx" SG_ 1108 RCMSerialNoByte4 1;
BA_ "U_B515_MCA_MY17_Diesel_Rx" SG_ 1108 RCMSerialNoByte4 1;
BA_ "U_B479_MY17_Diesel_Rx" SG_ 1108 RCMSerialNoByte4 1;
BA_ "U_B479_MY17_Gas_Rx" SG_ 1108 RCMSerialNoByte4 1;
BA_ "U_CX482_CX483_MY20_Hev_Tx" SG_ 1108 RCMSerialNoByte3 1;
BA_ "U_CX482_CX483_MY20_Gas_Tx" SG_ 1108 RCMSerialNoByte3 1;
BA_ "U_CX482_CX483_MY20_Diesel_Tx" SG_ 1108 RCMSerialNoByte3 1;
BA_ "U_U611_U625_MY20_Hev_Tx" SG_ 1108 RCMSerialNoByte3 1;
BA_ "U_U611_U625_MY20_Gas_Tx" SG_ 1108 RCMSerialNoByte3 1;
BA_ "U_U611_U625_MY20_Diesel_Tx" SG_ 1108 RCMSerialNoByte3 1;
BA_ "U_B500_MY18_Diesel_Tx" SG_ 1108 RCMSerialNoByte3 1;
BA_ "U_B500_MY18_Gas_Tx" SG_ 1108 RCMSerialNoByte3 1;
BA_ "U_C490_MY18_Tx" SG_ 1108 RCMSerialNoByte3 1;
BA_ "U_B562_MY18_Gas_Tx" SG_ 1108 RCMSerialNoByte3 1;
BA_ "U_C519_MY18_5_Gas_Tx" SG_ 1108 RCMSerialNoByte3 1;
BA_ "U_C519_MY18_5_Diesel_Tx" SG_ 1108 RCMSerialNoByte3 1;
BA_ "U_B515_MCA_MY17_Gas_Tx" SG_ 1108 RCMSerialNoByte3 1;
BA_ "U_B515_MCA_MY17_Diesel_Tx" SG_ 1108 RCMSerialNoByte3 1;
BA_ "U_B479_MY17_Diesel_Tx" SG_ 1108 RCMSerialNoByte3 1;
BA_ "U_B479_MY17_Gas_Tx" SG_ 1108 RCMSerialNoByte3 1;
BA_ "U_B562LC_MY15_Gas_Tx" SG_ 1108 RCMSerialNoByte3 1;
BA_ "U_B500_MY18_Diesel_Rx" SG_ 1108 RCMSerialNoByte3 1;
BA_ "U_B500_MY18_Gas_Rx" SG_ 1108 RCMSerialNoByte3 1;
BA_ "U_C490_MY18_Rx" SG_ 1108 RCMSerialNoByte3 1;
BA_ "U_B562_MY18_Gas_Rx" SG_ 1108 RCMSerialNoByte3 1;
BA_ "U_U611_U625_MY20_Phev_Rx" SG_ 1108 RCMSerialNoByte3 1;
BA_ "U_CX482_CX483_MY20_Hev_Rx" SG_ 1108 RCMSerialNoByte3 1;
BA_ "U_CX482_CX483_MY20_Gas_Rx" SG_ 1108 RCMSerialNoByte3 1;
BA_ "U_CX482_CX483_MY20_Diesel_Rx" SG_ 1108 RCMSerialNoByte3 1;
BA_ "U_U611_U625_MY20_Hev_Rx" SG_ 1108 RCMSerialNoByte3 1;
BA_ "U_U611_U625_MY20_Gas_Rx" SG_ 1108 RCMSerialNoByte3 1;
BA_ "U_U611_U625_MY20_Diesel_Rx" SG_ 1108 RCMSerialNoByte3 1;
BA_ "U_C519_MY18_5_Gas_Rx" SG_ 1108 RCMSerialNoByte3 1;
BA_ "U_C519_MY18_5_Diesel_Rx" SG_ 1108 RCMSerialNoByte3 1;
BA_ "U_B515_MCA_MY17_Gas_Rx" SG_ 1108 RCMSerialNoByte3 1;
BA_ "U_B515_MCA_MY17_Diesel_Rx" SG_ 1108 RCMSerialNoByte3 1;
BA_ "U_B479_MY17_Diesel_Rx" SG_ 1108 RCMSerialNoByte3 1;
BA_ "U_B479_MY17_Gas_Rx" SG_ 1108 RCMSerialNoByte3 1;
BA_ "U_CX482_CX483_MY20_Hev_Tx" SG_ 1108 RCMSerialNoByte2 1;
BA_ "U_CX482_CX483_MY20_Gas_Tx" SG_ 1108 RCMSerialNoByte2 1;
BA_ "U_CX482_CX483_MY20_Diesel_Tx" SG_ 1108 RCMSerialNoByte2 1;
BA_ "U_U611_U625_MY20_Hev_Tx" SG_ 1108 RCMSerialNoByte2 1;
BA_ "U_U611_U625_MY20_Gas_Tx" SG_ 1108 RCMSerialNoByte2 1;
BA_ "U_U611_U625_MY20_Diesel_Tx" SG_ 1108 RCMSerialNoByte2 1;
BA_ "U_B500_MY18_Diesel_Tx" SG_ 1108 RCMSerialNoByte2 1;
BA_ "U_B500_MY18_Gas_Tx" SG_ 1108 RCMSerialNoByte2 1;
BA_ "U_C490_MY18_Tx" SG_ 1108 RCMSerialNoByte2 1;
BA_ "U_B562_MY18_Gas_Tx" SG_ 1108 RCMSerialNoByte2 1;
BA_ "U_C519_MY18_5_Gas_Tx" SG_ 1108 RCMSerialNoByte2 1;
BA_ "U_C519_MY18_5_Diesel_Tx" SG_ 1108 RCMSerialNoByte2 1;
BA_ "U_B515_MCA_MY17_Gas_Tx" SG_ 1108 RCMSerialNoByte2 1;
BA_ "U_B515_MCA_MY17_Diesel_Tx" SG_ 1108 RCMSerialNoByte2 1;
BA_ "U_B479_MY17_Diesel_Tx" SG_ 1108 RCMSerialNoByte2 1;
BA_ "U_B479_MY17_Gas_Tx" SG_ 1108 RCMSerialNoByte2 1;
BA_ "U_B562LC_MY15_Gas_Tx" SG_ 1108 RCMSerialNoByte2 1;
BA_ "U_B500_MY18_Diesel_Rx" SG_ 1108 RCMSerialNoByte2 1;
BA_ "U_B500_MY18_Gas_Rx" SG_ 1108 RCMSerialNoByte2 1;
BA_ "U_C490_MY18_Rx" SG_ 1108 RCMSerialNoByte2 1;
BA_ "U_B562_MY18_Gas_Rx" SG_ 1108 RCMSerialNoByte2 1;
BA_ "U_U611_U625_MY20_Phev_Rx" SG_ 1108 RCMSerialNoByte2 1;
BA_ "U_CX482_CX483_MY20_Hev_Rx" SG_ 1108 RCMSerialNoByte2 1;
BA_ "U_CX482_CX483_MY20_Gas_Rx" SG_ 1108 RCMSerialNoByte2 1;
BA_ "U_CX482_CX483_MY20_Diesel_Rx" SG_ 1108 RCMSerialNoByte2 1;
BA_ "U_U611_U625_MY20_Hev_Rx" SG_ 1108 RCMSerialNoByte2 1;
BA_ "U_U611_U625_MY20_Gas_Rx" SG_ 1108 RCMSerialNoByte2 1;
BA_ "U_U611_U625_MY20_Diesel_Rx" SG_ 1108 RCMSerialNoByte2 1;
BA_ "U_C519_MY18_5_Gas_Rx" SG_ 1108 RCMSerialNoByte2 1;
BA_ "U_C519_MY18_5_Diesel_Rx" SG_ 1108 RCMSerialNoByte2 1;
BA_ "U_B515_MCA_MY17_Gas_Rx" SG_ 1108 RCMSerialNoByte2 1;
BA_ "U_B515_MCA_MY17_Diesel_Rx" SG_ 1108 RCMSerialNoByte2 1;
BA_ "U_B479_MY17_Diesel_Rx" SG_ 1108 RCMSerialNoByte2 1;
BA_ "U_B479_MY17_Gas_Rx" SG_ 1108 RCMSerialNoByte2 1;
BA_ "U_CX482_CX483_MY20_Hev_Tx" SG_ 1108 RCMSerialNoByte1 1;
BA_ "U_CX482_CX483_MY20_Gas_Tx" SG_ 1108 RCMSerialNoByte1 1;
BA_ "U_CX482_CX483_MY20_Diesel_Tx" SG_ 1108 RCMSerialNoByte1 1;
BA_ "U_U611_U625_MY20_Hev_Tx" SG_ 1108 RCMSerialNoByte1 1;
BA_ "U_U611_U625_MY20_Gas_Tx" SG_ 1108 RCMSerialNoByte1 1;
BA_ "U_U611_U625_MY20_Diesel_Tx" SG_ 1108 RCMSerialNoByte1 1;
BA_ "U_B500_MY18_Diesel_Tx" SG_ 1108 RCMSerialNoByte1 1;
BA_ "U_B500_MY18_Gas_Tx" SG_ 1108 RCMSerialNoByte1 1;
BA_ "U_C490_MY18_Tx" SG_ 1108 RCMSerialNoByte1 1;
BA_ "U_B562_MY18_Gas_Tx" SG_ 1108 RCMSerialNoByte1 1;
BA_ "U_C519_MY18_5_Gas_Tx" SG_ 1108 RCMSerialNoByte1 1;
BA_ "U_C519_MY18_5_Diesel_Tx" SG_ 1108 RCMSerialNoByte1 1;
BA_ "U_B515_MCA_MY17_Gas_Tx" SG_ 1108 RCMSerialNoByte1 1;
BA_ "U_B515_MCA_MY17_Diesel_Tx" SG_ 1108 RCMSerialNoByte1 1;
BA_ "U_B479_MY17_Diesel_Tx" SG_ 1108 RCMSerialNoByte1 1;
BA_ "U_B479_MY17_Gas_Tx" SG_ 1108 RCMSerialNoByte1 1;
BA_ "U_B562LC_MY15_Gas_Tx" SG_ 1108 RCMSerialNoByte1 1;
BA_ "U_B500_MY18_Diesel_Rx" SG_ 1108 RCMSerialNoByte1 1;
BA_ "U_B500_MY18_Gas_Rx" SG_ 1108 RCMSerialNoByte1 1;
BA_ "U_C490_MY18_Rx" SG_ 1108 RCMSerialNoByte1 1;
BA_ "U_B562_MY18_Gas_Rx" SG_ 1108 RCMSerialNoByte1 1;
BA_ "U_U611_U625_MY20_Phev_Rx" SG_ 1108 RCMSerialNoByte1 1;
BA_ "U_CX482_CX483_MY20_Hev_Rx" SG_ 1108 RCMSerialNoByte1 1;
BA_ "U_CX482_CX483_MY20_Gas_Rx" SG_ 1108 RCMSerialNoByte1 1;
BA_ "U_CX482_CX483_MY20_Diesel_Rx" SG_ 1108 RCMSerialNoByte1 1;
BA_ "U_U611_U625_MY20_Hev_Rx" SG_ 1108 RCMSerialNoByte1 1;
BA_ "U_U611_U625_MY20_Gas_Rx" SG_ 1108 RCMSerialNoByte1 1;
BA_ "U_U611_U625_MY20_Diesel_Rx" SG_ 1108 RCMSerialNoByte1 1;
BA_ "U_C519_MY18_5_Gas_Rx" SG_ 1108 RCMSerialNoByte1 1;
BA_ "U_C519_MY18_5_Diesel_Rx" SG_ 1108 RCMSerialNoByte1 1;
BA_ "U_B515_MCA_MY17_Gas_Rx" SG_ 1108 RCMSerialNoByte1 1;
BA_ "U_B515_MCA_MY17_Diesel_Rx" SG_ 1108 RCMSerialNoByte1 1;
BA_ "U_B479_MY17_Diesel_Rx" SG_ 1108 RCMSerialNoByte1 1;
BA_ "U_B479_MY17_Gas_Rx" SG_ 1108 RCMSerialNoByte1 1;
BA_ "U_U611_U625_MY20_Phev_Tx" SG_ 1107 OCSSerialNoByte8 1;
BA_ "U_CX482_CX483_MY20_Hev_Tx" SG_ 1107 OCSSerialNoByte8 1;
BA_ "U_CX482_CX483_MY20_Gas_Tx" SG_ 1107 OCSSerialNoByte8 1;
BA_ "U_CX482_CX483_MY20_Diesel_Tx" SG_ 1107 OCSSerialNoByte8 1;
BA_ "U_U611_U625_MY20_Hev_Tx" SG_ 1107 OCSSerialNoByte8 1;
BA_ "U_U611_U625_MY20_Gas_Tx" SG_ 1107 OCSSerialNoByte8 1;
BA_ "U_U611_U625_MY20_Diesel_Tx" SG_ 1107 OCSSerialNoByte8 1;
BA_ "U_C519_MY18_5_Gas_Tx" SG_ 1107 OCSSerialNoByte8 1;
BA_ "U_C519_MY18_5_Diesel_Tx" SG_ 1107 OCSSerialNoByte8 1;
BA_ "U_B515_MCA_MY17_Gas_Tx" SG_ 1107 OCSSerialNoByte8 1;
BA_ "U_B515_MCA_MY17_Diesel_Tx" SG_ 1107 OCSSerialNoByte8 1;
BA_ "U_B479_MY17_Diesel_Tx" SG_ 1107 OCSSerialNoByte8 1;
BA_ "U_B479_MY17_Gas_Tx" SG_ 1107 OCSSerialNoByte8 1;
BA_ "U_CX482_CX483_MY20_Hev_Rx" SG_ 1107 OCSSerialNoByte8 1;
BA_ "U_CX482_CX483_MY20_Gas_Rx" SG_ 1107 OCSSerialNoByte8 1;
BA_ "U_CX482_CX483_MY20_Diesel_Rx" SG_ 1107 OCSSerialNoByte8 1;
BA_ "U_U611_U625_MY20_Hev_Rx" SG_ 1107 OCSSerialNoByte8 1;
BA_ "U_U611_U625_MY20_Gas_Rx" SG_ 1107 OCSSerialNoByte8 1;
BA_ "U_U611_U625_MY20_Diesel_Rx" SG_ 1107 OCSSerialNoByte8 1;
BA_ "U_C519_MY18_5_Gas_Rx" SG_ 1107 OCSSerialNoByte8 1;
BA_ "U_C519_MY18_5_Diesel_Rx" SG_ 1107 OCSSerialNoByte8 1;
BA_ "U_B515_MCA_MY17_Gas_Rx" SG_ 1107 OCSSerialNoByte8 1;
BA_ "U_B515_MCA_MY17_Diesel_Rx" SG_ 1107 OCSSerialNoByte8 1;
BA_ "U_U611_U625_MY20_Phev_Tx" SG_ 1107 OCSSerialNoByte7 1;
BA_ "U_CX482_CX483_MY20_Hev_Tx" SG_ 1107 OCSSerialNoByte7 1;
BA_ "U_CX482_CX483_MY20_Gas_Tx" SG_ 1107 OCSSerialNoByte7 1;
BA_ "U_CX482_CX483_MY20_Diesel_Tx" SG_ 1107 OCSSerialNoByte7 1;
BA_ "U_U611_U625_MY20_Hev_Tx" SG_ 1107 OCSSerialNoByte7 1;
BA_ "U_U611_U625_MY20_Gas_Tx" SG_ 1107 OCSSerialNoByte7 1;
BA_ "U_U611_U625_MY20_Diesel_Tx" SG_ 1107 OCSSerialNoByte7 1;
BA_ "U_C519_MY18_5_Gas_Tx" SG_ 1107 OCSSerialNoByte7 1;
BA_ "U_C519_MY18_5_Diesel_Tx" SG_ 1107 OCSSerialNoByte7 1;
BA_ "U_B515_MCA_MY17_Gas_Tx" SG_ 1107 OCSSerialNoByte7 1;
BA_ "U_B515_MCA_MY17_Diesel_Tx" SG_ 1107 OCSSerialNoByte7 1;
BA_ "U_B479_MY17_Diesel_Tx" SG_ 1107 OCSSerialNoByte7 1;
BA_ "U_B479_MY17_Gas_Tx" SG_ 1107 OCSSerialNoByte7 1;
BA_ "U_CX482_CX483_MY20_Hev_Rx" SG_ 1107 OCSSerialNoByte7 1;
BA_ "U_CX482_CX483_MY20_Gas_Rx" SG_ 1107 OCSSerialNoByte7 1;
BA_ "U_CX482_CX483_MY20_Diesel_Rx" SG_ 1107 OCSSerialNoByte7 1;
BA_ "U_U611_U625_MY20_Hev_Rx" SG_ 1107 OCSSerialNoByte7 1;
BA_ "U_U611_U625_MY20_Gas_Rx" SG_ 1107 OCSSerialNoByte7 1;
BA_ "U_U611_U625_MY20_Diesel_Rx" SG_ 1107 OCSSerialNoByte7 1;
BA_ "U_C519_MY18_5_Gas_Rx" SG_ 1107 OCSSerialNoByte7 1;
BA_ "U_C519_MY18_5_Diesel_Rx" SG_ 1107 OCSSerialNoByte7 1;
BA_ "U_B515_MCA_MY17_Gas_Rx" SG_ 1107 OCSSerialNoByte7 1;
BA_ "U_B515_MCA_MY17_Diesel_Rx" SG_ 1107 OCSSerialNoByte7 1;
BA_ "U_U611_U625_MY20_Phev_Tx" SG_ 1107 OCSSerialNoByte6 1;
BA_ "U_CX482_CX483_MY20_Hev_Tx" SG_ 1107 OCSSerialNoByte6 1;
BA_ "U_CX482_CX483_MY20_Gas_Tx" SG_ 1107 OCSSerialNoByte6 1;
BA_ "U_CX482_CX483_MY20_Diesel_Tx" SG_ 1107 OCSSerialNoByte6 1;
BA_ "U_U611_U625_MY20_Hev_Tx" SG_ 1107 OCSSerialNoByte6 1;
BA_ "U_U611_U625_MY20_Gas_Tx" SG_ 1107 OCSSerialNoByte6 1;
BA_ "U_U611_U625_MY20_Diesel_Tx" SG_ 1107 OCSSerialNoByte6 1;
BA_ "U_C519_MY18_5_Gas_Tx" SG_ 1107 OCSSerialNoByte6 1;
BA_ "U_C519_MY18_5_Diesel_Tx" SG_ 1107 OCSSerialNoByte6 1;
BA_ "U_B515_MCA_MY17_Gas_Tx" SG_ 1107 OCSSerialNoByte6 1;
BA_ "U_B515_MCA_MY17_Diesel_Tx" SG_ 1107 OCSSerialNoByte6 1;
BA_ "U_B479_MY17_Diesel_Tx" SG_ 1107 OCSSerialNoByte6 1;
BA_ "U_B479_MY17_Gas_Tx" SG_ 1107 OCSSerialNoByte6 1;
BA_ "U_CX482_CX483_MY20_Hev_Rx" SG_ 1107 OCSSerialNoByte6 1;
BA_ "U_CX482_CX483_MY20_Gas_Rx" SG_ 1107 OCSSerialNoByte6 1;
BA_ "U_CX482_CX483_MY20_Diesel_Rx" SG_ 1107 OCSSerialNoByte6 1;
BA_ "U_U611_U625_MY20_Hev_Rx" SG_ 1107 OCSSerialNoByte6 1;
BA_ "U_U611_U625_MY20_Gas_Rx" SG_ 1107 OCSSerialNoByte6 1;
BA_ "U_U611_U625_MY20_Diesel_Rx" SG_ 1107 OCSSerialNoByte6 1;
BA_ "U_C519_MY18_5_Gas_Rx" SG_ 1107 OCSSerialNoByte6 1;
BA_ "U_C519_MY18_5_Diesel_Rx" SG_ 1107 OCSSerialNoByte6 1;
BA_ "U_B515_MCA_MY17_Gas_Rx" SG_ 1107 OCSSerialNoByte6 1;
BA_ "U_B515_MCA_MY17_Diesel_Rx" SG_ 1107 OCSSerialNoByte6 1;
BA_ "U_U611_U625_MY20_Phev_Tx" SG_ 1107 OCSSerialNoByte5 1;
BA_ "U_CX482_CX483_MY20_Hev_Tx" SG_ 1107 OCSSerialNoByte5 1;
BA_ "U_CX482_CX483_MY20_Gas_Tx" SG_ 1107 OCSSerialNoByte5 1;
BA_ "U_CX482_CX483_MY20_Diesel_Tx" SG_ 1107 OCSSerialNoByte5 1;
BA_ "U_U611_U625_MY20_Hev_Tx" SG_ 1107 OCSSerialNoByte5 1;
BA_ "U_U611_U625_MY20_Gas_Tx" SG_ 1107 OCSSerialNoByte5 1;
BA_ "U_U611_U625_MY20_Diesel_Tx" SG_ 1107 OCSSerialNoByte5 1;
BA_ "U_C519_MY18_5_Gas_Tx" SG_ 1107 OCSSerialNoByte5 1;
BA_ "U_C519_MY18_5_Diesel_Tx" SG_ 1107 OCSSerialNoByte5 1;
BA_ "U_B515_MCA_MY17_Gas_Tx" SG_ 1107 OCSSerialNoByte5 1;
BA_ "U_B515_MCA_MY17_Diesel_Tx" SG_ 1107 OCSSerialNoByte5 1;
BA_ "U_B479_MY17_Diesel_Tx" SG_ 1107 OCSSerialNoByte5 1;
BA_ "U_B479_MY17_Gas_Tx" SG_ 1107 OCSSerialNoByte5 1;
BA_ "U_CX482_CX483_MY20_Hev_Rx" SG_ 1107 OCSSerialNoByte5 1;
BA_ "U_CX482_CX483_MY20_Gas_Rx" SG_ 1107 OCSSerialNoByte5 1;
BA_ "U_CX482_CX483_MY20_Diesel_Rx" SG_ 1107 OCSSerialNoByte5 1;
BA_ "U_U611_U625_MY20_Hev_Rx" SG_ 1107 OCSSerialNoByte5 1;
BA_ "U_U611_U625_MY20_Gas_Rx" SG_ 1107 OCSSerialNoByte5 1;
BA_ "U_U611_U625_MY20_Diesel_Rx" SG_ 1107 OCSSerialNoByte5 1;
BA_ "U_C519_MY18_5_Gas_Rx" SG_ 1107 OCSSerialNoByte5 1;
BA_ "U_C519_MY18_5_Diesel_Rx" SG_ 1107 OCSSerialNoByte5 1;
BA_ "U_B515_MCA_MY17_Gas_Rx" SG_ 1107 OCSSerialNoByte5 1;
BA_ "U_B515_MCA_MY17_Diesel_Rx" SG_ 1107 OCSSerialNoByte5 1;
BA_ "U_U611_U625_MY20_Phev_Tx" SG_ 1107 OCSSerialNoByte4 1;
BA_ "U_CX482_CX483_MY20_Hev_Tx" SG_ 1107 OCSSerialNoByte4 1;
BA_ "U_CX482_CX483_MY20_Gas_Tx" SG_ 1107 OCSSerialNoByte4 1;
BA_ "U_CX482_CX483_MY20_Diesel_Tx" SG_ 1107 OCSSerialNoByte4 1;
BA_ "U_U611_U625_MY20_Hev_Tx" SG_ 1107 OCSSerialNoByte4 1;
BA_ "U_U611_U625_MY20_Gas_Tx" SG_ 1107 OCSSerialNoByte4 1;
BA_ "U_U611_U625_MY20_Diesel_Tx" SG_ 1107 OCSSerialNoByte4 1;
BA_ "U_C519_MY18_5_Gas_Tx" SG_ 1107 OCSSerialNoByte4 1;
BA_ "U_C519_MY18_5_Diesel_Tx" SG_ 1107 OCSSerialNoByte4 1;
BA_ "U_B515_MCA_MY17_Gas_Tx" SG_ 1107 OCSSerialNoByte4 1;
BA_ "U_B515_MCA_MY17_Diesel_Tx" SG_ 1107 OCSSerialNoByte4 1;
BA_ "U_B479_MY17_Diesel_Tx" SG_ 1107 OCSSerialNoByte4 1;
BA_ "U_B479_MY17_Gas_Tx" SG_ 1107 OCSSerialNoByte4 1;
BA_ "U_CX482_CX483_MY20_Hev_Rx" SG_ 1107 OCSSerialNoByte4 1;
BA_ "U_CX482_CX483_MY20_Gas_Rx" SG_ 1107 OCSSerialNoByte4 1;
BA_ "U_CX482_CX483_MY20_Diesel_Rx" SG_ 1107 OCSSerialNoByte4 1;
BA_ "U_U611_U625_MY20_Hev_Rx" SG_ 1107 OCSSerialNoByte4 1;
BA_ "U_U611_U625_MY20_Gas_Rx" SG_ 1107 OCSSerialNoByte4 1;
BA_ "U_U611_U625_MY20_Diesel_Rx" SG_ 1107 OCSSerialNoByte4 1;
BA_ "U_C519_MY18_5_Gas_Rx" SG_ 1107 OCSSerialNoByte4 1;
BA_ "U_C519_MY18_5_Diesel_Rx" SG_ 1107 OCSSerialNoByte4 1;
BA_ "U_B515_MCA_MY17_Gas_Rx" SG_ 1107 OCSSerialNoByte4 1;
BA_ "U_B515_MCA_MY17_Diesel_Rx" SG_ 1107 OCSSerialNoByte4 1;
BA_ "U_U611_U625_MY20_Phev_Tx" SG_ 1107 OCSSerialNoByte3 1;
BA_ "U_CX482_CX483_MY20_Hev_Tx" SG_ 1107 OCSSerialNoByte3 1;
BA_ "U_CX482_CX483_MY20_Gas_Tx" SG_ 1107 OCSSerialNoByte3 1;
BA_ "U_CX482_CX483_MY20_Diesel_Tx" SG_ 1107 OCSSerialNoByte3 1;
BA_ "U_U611_U625_MY20_Hev_Tx" SG_ 1107 OCSSerialNoByte3 1;
BA_ "U_U611_U625_MY20_Gas_Tx" SG_ 1107 OCSSerialNoByte3 1;
BA_ "U_U611_U625_MY20_Diesel_Tx" SG_ 1107 OCSSerialNoByte3 1;
BA_ "U_C519_MY18_5_Gas_Tx" SG_ 1107 OCSSerialNoByte3 1;
BA_ "U_C519_MY18_5_Diesel_Tx" SG_ 1107 OCSSerialNoByte3 1;
BA_ "U_B515_MCA_MY17_Gas_Tx" SG_ 1107 OCSSerialNoByte3 1;
BA_ "U_B515_MCA_MY17_Diesel_Tx" SG_ 1107 OCSSerialNoByte3 1;
BA_ "U_B479_MY17_Diesel_Tx" SG_ 1107 OCSSerialNoByte3 1;
BA_ "U_B479_MY17_Gas_Tx" SG_ 1107 OCSSerialNoByte3 1;
BA_ "U_CX482_CX483_MY20_Hev_Rx" SG_ 1107 OCSSerialNoByte3 1;
BA_ "U_CX482_CX483_MY20_Gas_Rx" SG_ 1107 OCSSerialNoByte3 1;
BA_ "U_CX482_CX483_MY20_Diesel_Rx" SG_ 1107 OCSSerialNoByte3 1;
BA_ "U_U611_U625_MY20_Hev_Rx" SG_ 1107 OCSSerialNoByte3 1;
BA_ "U_U611_U625_MY20_Gas_Rx" SG_ 1107 OCSSerialNoByte3 1;
BA_ "U_U611_U625_MY20_Diesel_Rx" SG_ 1107 OCSSerialNoByte3 1;
BA_ "U_C519_MY18_5_Gas_Rx" SG_ 1107 OCSSerialNoByte3 1;
BA_ "U_C519_MY18_5_Diesel_Rx" SG_ 1107 OCSSerialNoByte3 1;
BA_ "U_B515_MCA_MY17_Gas_Rx" SG_ 1107 OCSSerialNoByte3 1;
BA_ "U_B515_MCA_MY17_Diesel_Rx" SG_ 1107 OCSSerialNoByte3 1;
BA_ "U_U611_U625_MY20_Phev_Tx" SG_ 1107 OCSSerialNoByte2 1;
BA_ "U_CX482_CX483_MY20_Hev_Tx" SG_ 1107 OCSSerialNoByte2 1;
BA_ "U_CX482_CX483_MY20_Gas_Tx" SG_ 1107 OCSSerialNoByte2 1;
BA_ "U_CX482_CX483_MY20_Diesel_Tx" SG_ 1107 OCSSerialNoByte2 1;
BA_ "U_U611_U625_MY20_Hev_Tx" SG_ 1107 OCSSerialNoByte2 1;
BA_ "U_U611_U625_MY20_Gas_Tx" SG_ 1107 OCSSerialNoByte2 1;
BA_ "U_U611_U625_MY20_Diesel_Tx" SG_ 1107 OCSSerialNoByte2 1;
BA_ "U_C519_MY18_5_Gas_Tx" SG_ 1107 OCSSerialNoByte2 1;
BA_ "U_C519_MY18_5_Diesel_Tx" SG_ 1107 OCSSerialNoByte2 1;
BA_ "U_B515_MCA_MY17_Gas_Tx" SG_ 1107 OCSSerialNoByte2 1;
BA_ "U_B515_MCA_MY17_Diesel_Tx" SG_ 1107 OCSSerialNoByte2 1;
BA_ "U_B479_MY17_Diesel_Tx" SG_ 1107 OCSSerialNoByte2 1;
BA_ "U_B479_MY17_Gas_Tx" SG_ 1107 OCSSerialNoByte2 1;
BA_ "U_CX482_CX483_MY20_Hev_Rx" SG_ 1107 OCSSerialNoByte2 1;
BA_ "U_CX482_CX483_MY20_Gas_Rx" SG_ 1107 OCSSerialNoByte2 1;
BA_ "U_CX482_CX483_MY20_Diesel_Rx" SG_ 1107 OCSSerialNoByte2 1;
BA_ "U_U611_U625_MY20_Hev_Rx" SG_ 1107 OCSSerialNoByte2 1;
BA_ "U_U611_U625_MY20_Gas_Rx" SG_ 1107 OCSSerialNoByte2 1;
BA_ "U_U611_U625_MY20_Diesel_Rx" SG_ 1107 OCSSerialNoByte2 1;
BA_ "U_C519_MY18_5_Gas_Rx" SG_ 1107 OCSSerialNoByte2 1;
BA_ "U_C519_MY18_5_Diesel_Rx" SG_ 1107 OCSSerialNoByte2 1;
BA_ "U_B515_MCA_MY17_Gas_Rx" SG_ 1107 OCSSerialNoByte2 1;
BA_ "U_B515_MCA_MY17_Diesel_Rx" SG_ 1107 OCSSerialNoByte2 1;
BA_ "U_U611_U625_MY20_Phev_Tx" SG_ 1107 OCSSerialNoByte1 1;
BA_ "U_CX482_CX483_MY20_Hev_Tx" SG_ 1107 OCSSerialNoByte1 1;
BA_ "U_CX482_CX483_MY20_Gas_Tx" SG_ 1107 OCSSerialNoByte1 1;
BA_ "U_CX482_CX483_MY20_Diesel_Tx" SG_ 1107 OCSSerialNoByte1 1;
BA_ "U_U611_U625_MY20_Hev_Tx" SG_ 1107 OCSSerialNoByte1 1;
BA_ "U_U611_U625_MY20_Gas_Tx" SG_ 1107 OCSSerialNoByte1 1;
BA_ "U_U611_U625_MY20_Diesel_Tx" SG_ 1107 OCSSerialNoByte1 1;
BA_ "U_C519_MY18_5_Gas_Tx" SG_ 1107 OCSSerialNoByte1 1;
BA_ "U_C519_MY18_5_Diesel_Tx" SG_ 1107 OCSSerialNoByte1 1;
BA_ "U_B515_MCA_MY17_Gas_Tx" SG_ 1107 OCSSerialNoByte1 1;
BA_ "U_B515_MCA_MY17_Diesel_Tx" SG_ 1107 OCSSerialNoByte1 1;
BA_ "U_B479_MY17_Diesel_Tx" SG_ 1107 OCSSerialNoByte1 1;
BA_ "U_B479_MY17_Gas_Tx" SG_ 1107 OCSSerialNoByte1 1;
BA_ "U_CX482_CX483_MY20_Hev_Rx" SG_ 1107 OCSSerialNoByte1 1;
BA_ "U_CX482_CX483_MY20_Gas_Rx" SG_ 1107 OCSSerialNoByte1 1;
BA_ "U_CX482_CX483_MY20_Diesel_Rx" SG_ 1107 OCSSerialNoByte1 1;
BA_ "U_U611_U625_MY20_Hev_Rx" SG_ 1107 OCSSerialNoByte1 1;
BA_ "U_U611_U625_MY20_Gas_Rx" SG_ 1107 OCSSerialNoByte1 1;
BA_ "U_U611_U625_MY20_Diesel_Rx" SG_ 1107 OCSSerialNoByte1 1;
BA_ "U_C519_MY18_5_Gas_Rx" SG_ 1107 OCSSerialNoByte1 1;
BA_ "U_C519_MY18_5_Diesel_Rx" SG_ 1107 OCSSerialNoByte1 1;
BA_ "U_B515_MCA_MY17_Gas_Rx" SG_ 1107 OCSSerialNoByte1 1;
BA_ "U_B515_MCA_MY17_Diesel_Rx" SG_ 1107 OCSSerialNoByte1 1;
BA_ "U_U611_U625_MY20_Phev_Tx" SG_ 1848 TesterPhysicalResPSCM 1;
BA_ "U_CX482_CX483_MY20_Hev_Tx" SG_ 1848 TesterPhysicalResPSCM 1;
BA_ "U_CX482_CX483_MY20_Gas_Tx" SG_ 1848 TesterPhysicalResPSCM 1;
BA_ "U_CX482_CX483_MY20_Diesel_Tx" SG_ 1848 TesterPhysicalResPSCM 1;
BA_ "U_U611_U625_MY20_Hev_Tx" SG_ 1848 TesterPhysicalResPSCM 1;
BA_ "U_U611_U625_MY20_Gas_Tx" SG_ 1848 TesterPhysicalResPSCM 1;
BA_ "U_U611_U625_MY20_Diesel_Tx" SG_ 1848 TesterPhysicalResPSCM 1;
BA_ "U_B500_MY18_Diesel_Tx" SG_ 1848 TesterPhysicalResPSCM 1;
BA_ "U_B500_MY18_Gas_Tx" SG_ 1848 TesterPhysicalResPSCM 1;
BA_ "U_C490_MY18_Tx" SG_ 1848 TesterPhysicalResPSCM 1;
BA_ "U_B562_MY18_Gas_Tx" SG_ 1848 TesterPhysicalResPSCM 1;
BA_ "U_C519_MY18_5_Gas_Tx" SG_ 1848 TesterPhysicalResPSCM 1;
BA_ "U_C519_MY18_5_Diesel_Tx" SG_ 1848 TesterPhysicalResPSCM 1;
BA_ "U_B515_MCA_MY17_Gas_Tx" SG_ 1848 TesterPhysicalResPSCM 1;
BA_ "U_B515_MCA_MY17_Diesel_Tx" SG_ 1848 TesterPhysicalResPSCM 1;
BA_ "U_B479_MY17_Diesel_Tx" SG_ 1848 TesterPhysicalResPSCM 1;
BA_ "U_B479_MY17_Gas_Tx" SG_ 1848 TesterPhysicalResPSCM 1;
BA_ "GenSigSendType" SG_ 1848 TesterPhysicalResPSCM 3;
BA_ "U_CX482_CX483_MY20_Hev_Tx" SG_ 1900 TesterPhysicalResCCM 1;
BA_ "U_CX482_CX483_MY20_Gas_Tx" SG_ 1900 TesterPhysicalResCCM 1;
BA_ "U_CX482_CX483_MY20_Diesel_Tx" SG_ 1900 TesterPhysicalResCCM 1;
BA_ "U_U611_U625_MY20_Hev_Tx" SG_ 1900 TesterPhysicalResCCM 1;
BA_ "U_U611_U625_MY20_Gas_Tx" SG_ 1900 TesterPhysicalResCCM 1;
BA_ "U_U611_U625_MY20_Diesel_Tx" SG_ 1900 TesterPhysicalResCCM 1;
BA_ "U_C519_MY18_5_Gas_Tx" SG_ 1900 TesterPhysicalResCCM 1;
BA_ "U_C519_MY18_5_Diesel_Tx" SG_ 1900 TesterPhysicalResCCM 1;
BA_ "U_B479_MY17_Diesel_Tx" SG_ 1900 TesterPhysicalResCCM 1;
BA_ "U_B479_MY17_Gas_Tx" SG_ 1900 TesterPhysicalResCCM 1;
BA_ "GenSigSendType" SG_ 1900 TesterPhysicalResCCM 3;
BA_ "U_CX482_CX483_MY20_Hev_Rx" SG_ 1892 TesterPhysicalReqCCM 1;
BA_ "U_CX482_CX483_MY20_Gas_Rx" SG_ 1892 TesterPhysicalReqCCM 1;
BA_ "U_CX482_CX483_MY20_Diesel_Rx" SG_ 1892 TesterPhysicalReqCCM 1;
BA_ "U_U611_U625_MY20_Hev_Rx" SG_ 1892 TesterPhysicalReqCCM 1;
BA_ "U_U611_U625_MY20_Gas_Rx" SG_ 1892 TesterPhysicalReqCCM 1;
BA_ "U_U611_U625_MY20_Diesel_Rx" SG_ 1892 TesterPhysicalReqCCM 1;
BA_ "U_B479_MY17_Diesel_Rx" SG_ 1892 TesterPhysicalReqCCM 1;
BA_ "U_B479_MY17_Gas_Rx" SG_ 1892 TesterPhysicalReqCCM 1;
BA_ "U_C519_MY18_5_Gas_Rx" SG_ 1892 TesterPhysicalReqCCM 1;
BA_ "U_C519_MY18_5_Diesel_Rx" SG_ 1892 TesterPhysicalReqCCM 1;
BA_ "GenSigSendType" SG_ 1892 TesterPhysicalReqCCM 3;
BA_ "GenSigSendType" SG_ 1879 TesterPhysicalReqTBM 3;
BA_ "GenSigTimeoutTime_GWM" SG_ 145 VehYawWActl_D_Qf 30;
BA_ "U_CX482_CX483_MY20_Hev_Tx" SG_ 145 VehYawWActl_D_Qf 1;
BA_ "U_CX482_CX483_MY20_Gas_Tx" SG_ 145 VehYawWActl_D_Qf 1;
BA_ "U_CX482_CX483_MY20_Diesel_Tx" SG_ 145 VehYawWActl_D_Qf 1;
BA_ "U_U611_U625_MY20_Hev_Tx" SG_ 145 VehYawWActl_D_Qf 1;
BA_ "U_U611_U625_MY20_Gas_Tx" SG_ 145 VehYawWActl_D_Qf 1;
BA_ "U_U611_U625_MY20_Diesel_Tx" SG_ 145 VehYawWActl_D_Qf 1;
BA_ "U_B500_MY18_Diesel_Tx" SG_ 145 VehYawWActl_D_Qf 1;
BA_ "U_B500_MY18_Gas_Tx" SG_ 145 VehYawWActl_D_Qf 1;
BA_ "U_C490_MY18_Tx" SG_ 145 VehYawWActl_D_Qf 1;
BA_ "U_B562_MY18_Gas_Tx" SG_ 145 VehYawWActl_D_Qf 1;
BA_ "U_C519_MY18_5_Gas_Tx" SG_ 145 VehYawWActl_D_Qf 1;
BA_ "U_C519_MY18_5_Diesel_Tx" SG_ 145 VehYawWActl_D_Qf 1;
BA_ "U_B515_MCA_MY17_Gas_Tx" SG_ 145 VehYawWActl_D_Qf 1;
BA_ "U_B515_MCA_MY17_Diesel_Tx" SG_ 145 VehYawWActl_D_Qf 1;
BA_ "U_B479_MY17_Diesel_Tx" SG_ 145 VehYawWActl_D_Qf 1;
BA_ "U_B479_MY17_Gas_Tx" SG_ 145 VehYawWActl_D_Qf 1;
BA_ "U_CX482_CX483_MY20_Hev_Rx" SG_ 145 VehYawWActl_D_Qf 1;
BA_ "U_CX482_CX483_MY20_Gas_Rx" SG_ 145 VehYawWActl_D_Qf 1;
BA_ "U_CX482_CX483_MY20_Diesel_Rx" SG_ 145 VehYawWActl_D_Qf 1;
BA_ "U_U611_U625_MY20_Hev_Rx" SG_ 145 VehYawWActl_D_Qf 1;
BA_ "U_U611_U625_MY20_Gas_Rx" SG_ 145 VehYawWActl_D_Qf 1;
BA_ "U_U611_U625_MY20_Diesel_Rx" SG_ 145 VehYawWActl_D_Qf 1;
BA_ "U_B500_MY18_Diesel_Rx" SG_ 145 VehYawWActl_D_Qf 1;
BA_ "U_B500_MY18_Gas_Rx" SG_ 145 VehYawWActl_D_Qf 1;
BA_ "U_C490_MY18_Rx" SG_ 145 VehYawWActl_D_Qf 1;
BA_ "U_B562_MY18_Gas_Rx" SG_ 145 VehYawWActl_D_Qf 1;
BA_ "U_C519_MY18_5_Gas_Rx" SG_ 145 VehYawWActl_D_Qf 1;
BA_ "U_C519_MY18_5_Diesel_Rx" SG_ 145 VehYawWActl_D_Qf 1;
BA_ "U_B515_MCA_MY17_Gas_Rx" SG_ 145 VehYawWActl_D_Qf 1;
BA_ "U_B515_MCA_MY17_Diesel_Rx" SG_ 145 VehYawWActl_D_Qf 1;
BA_ "U_B479_MY17_Diesel_Rx" SG_ 145 VehYawWActl_D_Qf 1;
BA_ "U_B479_MY17_Gas_Rx" SG_ 145 VehYawWActl_D_Qf 1;
BA_ "GenSigStartValue" SG_ 145 VehYawWActl_D_Qf 1;
BA_ "GenSigTimeoutTime_GWM" SG_ 145 VehRolWActl_D_Qf 30;
BA_ "U_CX482_CX483_MY20_Hev_Tx" SG_ 145 VehRolWActl_D_Qf 1;
BA_ "U_CX482_CX483_MY20_Gas_Tx" SG_ 145 VehRolWActl_D_Qf 1;
BA_ "U_CX482_CX483_MY20_Diesel_Tx" SG_ 145 VehRolWActl_D_Qf 1;
BA_ "U_U611_U625_MY20_Hev_Tx" SG_ 145 VehRolWActl_D_Qf 1;
BA_ "U_U611_U625_MY20_Gas_Tx" SG_ 145 VehRolWActl_D_Qf 1;
BA_ "U_U611_U625_MY20_Diesel_Tx" SG_ 145 VehRolWActl_D_Qf 1;
BA_ "U_B500_MY18_Diesel_Tx" SG_ 145 VehRolWActl_D_Qf 1;
BA_ "U_B500_MY18_Gas_Tx" SG_ 145 VehRolWActl_D_Qf 1;
BA_ "U_C490_MY18_Tx" SG_ 145 VehRolWActl_D_Qf 1;
BA_ "U_B562_MY18_Gas_Tx" SG_ 145 VehRolWActl_D_Qf 1;
BA_ "U_C519_MY18_5_Gas_Tx" SG_ 145 VehRolWActl_D_Qf 1;
BA_ "U_C519_MY18_5_Diesel_Tx" SG_ 145 VehRolWActl_D_Qf 1;
BA_ "U_B515_MCA_MY17_Gas_Tx" SG_ 145 VehRolWActl_D_Qf 1;
BA_ "U_B515_MCA_MY17_Diesel_Tx" SG_ 145 VehRolWActl_D_Qf 1;
BA_ "U_B479_MY17_Diesel_Tx" SG_ 145 VehRolWActl_D_Qf 1;
BA_ "U_B479_MY17_Gas_Tx" SG_ 145 VehRolWActl_D_Qf 1;
BA_ "U_U611_U625_MY20_Phev_Rx" SG_ 145 VehRolWActl_D_Qf 1;
BA_ "U_CX482_CX483_MY20_Hev_Rx" SG_ 145 VehRolWActl_D_Qf 1;
BA_ "U_CX482_CX483_MY20_Gas_Rx" SG_ 145 VehRolWActl_D_Qf 1;
BA_ "U_CX482_CX483_MY20_Diesel_Rx" SG_ 145 VehRolWActl_D_Qf 1;
BA_ "U_U611_U625_MY20_Hev_Rx" SG_ 145 VehRolWActl_D_Qf 1;
BA_ "U_U611_U625_MY20_Gas_Rx" SG_ 145 VehRolWActl_D_Qf 1;
BA_ "U_U611_U625_MY20_Diesel_Rx" SG_ 145 VehRolWActl_D_Qf 1;
BA_ "U_B500_MY18_Diesel_Rx" SG_ 145 VehRolWActl_D_Qf 1;
BA_ "U_B500_MY18_Gas_Rx" SG_ 145 VehRolWActl_D_Qf 1;
BA_ "U_C490_MY18_Rx" SG_ 145 VehRolWActl_D_Qf 1;
BA_ "U_B562_MY18_Gas_Rx" SG_ 145 VehRolWActl_D_Qf 1;
BA_ "U_C519_MY18_5_Gas_Rx" SG_ 145 VehRolWActl_D_Qf 1;
BA_ "U_C519_MY18_5_Diesel_Rx" SG_ 145 VehRolWActl_D_Qf 1;
BA_ "U_B515_MCA_MY17_Gas_Rx" SG_ 145 VehRolWActl_D_Qf 1;
BA_ "U_B515_MCA_MY17_Diesel_Rx" SG_ 145 VehRolWActl_D_Qf 1;
BA_ "U_B479_MY17_Diesel_Rx" SG_ 145 VehRolWActl_D_Qf 1;
BA_ "U_B479_MY17_Gas_Rx" SG_ 145 VehRolWActl_D_Qf 1;
BA_ "GenSigStartValue" SG_ 145 VehRolWActl_D_Qf 1;
BA_ "GenSigTimeoutTime_GWM" SG_ 145 VehRollYawW_No_Cs 30;
BA_ "U_CX482_CX483_MY20_Hev_Tx" SG_ 145 VehRollYawW_No_Cs 1;
BA_ "U_CX482_CX483_MY20_Gas_Tx" SG_ 145 VehRollYawW_No_Cs 1;
BA_ "U_CX482_CX483_MY20_Diesel_Tx" SG_ 145 VehRollYawW_No_Cs 1;
BA_ "U_U611_U625_MY20_Hev_Tx" SG_ 145 VehRollYawW_No_Cs 1;
BA_ "U_U611_U625_MY20_Gas_Tx" SG_ 145 VehRollYawW_No_Cs 1;
BA_ "U_U611_U625_MY20_Diesel_Tx" SG_ 145 VehRollYawW_No_Cs 1;
BA_ "U_B500_MY18_Diesel_Tx" SG_ 145 VehRollYawW_No_Cs 1;
BA_ "U_B500_MY18_Gas_Tx" SG_ 145 VehRollYawW_No_Cs 1;
BA_ "U_C490_MY18_Tx" SG_ 145 VehRollYawW_No_Cs 1;
BA_ "U_B562_MY18_Gas_Tx" SG_ 145 VehRollYawW_No_Cs 1;
BA_ "U_C519_MY18_5_Gas_Tx" SG_ 145 VehRollYawW_No_Cs 1;
BA_ "U_C519_MY18_5_Diesel_Tx" SG_ 145 VehRollYawW_No_Cs 1;
BA_ "U_B515_MCA_MY17_Gas_Tx" SG_ 145 VehRollYawW_No_Cs 1;
BA_ "U_B515_MCA_MY17_Diesel_Tx" SG_ 145 VehRollYawW_No_Cs 1;
BA_ "U_B479_MY17_Diesel_Tx" SG_ 145 VehRollYawW_No_Cs 1;
BA_ "U_B479_MY17_Gas_Tx" SG_ 145 VehRollYawW_No_Cs 1;
BA_ "U_CX482_CX483_MY20_Hev_Rx" SG_ 145 VehRollYawW_No_Cs 1;
BA_ "U_CX482_CX483_MY20_Gas_Rx" SG_ 145 VehRollYawW_No_Cs 1;
BA_ "U_CX482_CX483_MY20_Diesel_Rx" SG_ 145 VehRollYawW_No_Cs 1;
BA_ "U_U611_U625_MY20_Hev_Rx" SG_ 145 VehRollYawW_No_Cs 1;
BA_ "U_U611_U625_MY20_Gas_Rx" SG_ 145 VehRollYawW_No_Cs 1;
BA_ "U_U611_U625_MY20_Diesel_Rx" SG_ 145 VehRollYawW_No_Cs 1;
BA_ "U_B500_MY18_Diesel_Rx" SG_ 145 VehRollYawW_No_Cs 1;
BA_ "U_B500_MY18_Gas_Rx" SG_ 145 VehRollYawW_No_Cs 1;
BA_ "U_C490_MY18_Rx" SG_ 145 VehRollYawW_No_Cs 1;
BA_ "U_B562_MY18_Gas_Rx" SG_ 145 VehRollYawW_No_Cs 1;
BA_ "U_C519_MY18_5_Gas_Rx" SG_ 145 VehRollYawW_No_Cs 1;
BA_ "U_C519_MY18_5_Diesel_Rx" SG_ 145 VehRollYawW_No_Cs 1;
BA_ "U_B515_MCA_MY17_Gas_Rx" SG_ 145 VehRollYawW_No_Cs 1;
BA_ "U_B515_MCA_MY17_Diesel_Rx" SG_ 145 VehRollYawW_No_Cs 1;
BA_ "U_B479_MY17_Diesel_Rx" SG_ 145 VehRollYawW_No_Cs 1;
BA_ "U_B479_MY17_Gas_Rx" SG_ 145 VehRollYawW_No_Cs 1;
BA_ "GenSigTimeoutTime_GWM" SG_ 145 VehRollYaw_No_Cnt 30;
BA_ "U_CX482_CX483_MY20_Hev_Tx" SG_ 145 VehRollYaw_No_Cnt 1;
BA_ "U_CX482_CX483_MY20_Gas_Tx" SG_ 145 VehRollYaw_No_Cnt 1;
BA_ "U_CX482_CX483_MY20_Diesel_Tx" SG_ 145 VehRollYaw_No_Cnt 1;
BA_ "U_U611_U625_MY20_Hev_Tx" SG_ 145 VehRollYaw_No_Cnt 1;
BA_ "U_U611_U625_MY20_Gas_Tx" SG_ 145 VehRollYaw_No_Cnt 1;
BA_ "U_U611_U625_MY20_Diesel_Tx" SG_ 145 VehRollYaw_No_Cnt 1;
BA_ "U_B500_MY18_Diesel_Tx" SG_ 145 VehRollYaw_No_Cnt 1;
BA_ "U_B500_MY18_Gas_Tx" SG_ 145 VehRollYaw_No_Cnt 1;
BA_ "U_C490_MY18_Tx" SG_ 145 VehRollYaw_No_Cnt 1;
BA_ "U_B562_MY18_Gas_Tx" SG_ 145 VehRollYaw_No_Cnt 1;
BA_ "U_C519_MY18_5_Gas_Tx" SG_ 145 VehRollYaw_No_Cnt 1;
BA_ "U_C519_MY18_5_Diesel_Tx" SG_ 145 VehRollYaw_No_Cnt 1;
BA_ "U_B515_MCA_MY17_Gas_Tx" SG_ 145 VehRollYaw_No_Cnt 1;
BA_ "U_B515_MCA_MY17_Diesel_Tx" SG_ 145 VehRollYaw_No_Cnt 1;
BA_ "U_B479_MY17_Diesel_Tx" SG_ 145 VehRollYaw_No_Cnt 1;
BA_ "U_B479_MY17_Gas_Tx" SG_ 145 VehRollYaw_No_Cnt 1;
BA_ "U_U611_U625_MY20_Phev_Rx" SG_ 145 VehRollYaw_No_Cnt 1;
BA_ "U_CX482_CX483_MY20_Hev_Rx" SG_ 145 VehRollYaw_No_Cnt 1;
BA_ "U_CX482_CX483_MY20_Gas_Rx" SG_ 145 VehRollYaw_No_Cnt 1;
BA_ "U_CX482_CX483_MY20_Diesel_Rx" SG_ 145 VehRollYaw_No_Cnt 1;
BA_ "U_U611_U625_MY20_Hev_Rx" SG_ 145 VehRollYaw_No_Cnt 1;
BA_ "U_U611_U625_MY20_Gas_Rx" SG_ 145 VehRollYaw_No_Cnt 1;
BA_ "U_U611_U625_MY20_Diesel_Rx" SG_ 145 VehRollYaw_No_Cnt 1;
BA_ "U_B500_MY18_Diesel_Rx" SG_ 145 VehRollYaw_No_Cnt 1;
BA_ "U_B500_MY18_Gas_Rx" SG_ 145 VehRollYaw_No_Cnt 1;
BA_ "U_C490_MY18_Rx" SG_ 145 VehRollYaw_No_Cnt 1;
BA_ "U_B562_MY18_Gas_Rx" SG_ 145 VehRollYaw_No_Cnt 1;
BA_ "U_C519_MY18_5_Gas_Rx" SG_ 145 VehRollYaw_No_Cnt 1;
BA_ "U_C519_MY18_5_Diesel_Rx" SG_ 145 VehRollYaw_No_Cnt 1;
BA_ "U_B515_MCA_MY17_Gas_Rx" SG_ 145 VehRollYaw_No_Cnt 1;
BA_ "U_B515_MCA_MY17_Diesel_Rx" SG_ 145 VehRollYaw_No_Cnt 1;
BA_ "U_B479_MY17_Diesel_Rx" SG_ 145 VehRollYaw_No_Cnt 1;
BA_ "U_B479_MY17_Gas_Rx" SG_ 145 VehRollYaw_No_Cnt 1;
BA_ "GenSigTimeoutTime_GWM" SG_ 145 VehYaw_W_Actl 30;
BA_ "U_CX482_CX483_MY20_Hev_Tx" SG_ 145 VehYaw_W_Actl 1;
BA_ "U_CX482_CX483_MY20_Gas_Tx" SG_ 145 VehYaw_W_Actl 1;
BA_ "U_CX482_CX483_MY20_Diesel_Tx" SG_ 145 VehYaw_W_Actl 1;
BA_ "U_U611_U625_MY20_Hev_Tx" SG_ 145 VehYaw_W_Actl 1;
BA_ "U_U611_U625_MY20_Gas_Tx" SG_ 145 VehYaw_W_Actl 1;
BA_ "U_U611_U625_MY20_Diesel_Tx" SG_ 145 VehYaw_W_Actl 1;
BA_ "U_B500_MY18_Diesel_Tx" SG_ 145 VehYaw_W_Actl 1;
BA_ "U_B500_MY18_Gas_Tx" SG_ 145 VehYaw_W_Actl 1;
BA_ "U_C490_MY18_Tx" SG_ 145 VehYaw_W_Actl 1;
BA_ "U_B562_MY18_Gas_Tx" SG_ 145 VehYaw_W_Actl 1;
BA_ "U_C519_MY18_5_Gas_Tx" SG_ 145 VehYaw_W_Actl 1;
BA_ "U_C519_MY18_5_Diesel_Tx" SG_ 145 VehYaw_W_Actl 1;
BA_ "U_B515_MCA_MY17_Gas_Tx" SG_ 145 VehYaw_W_Actl 1;
BA_ "U_B515_MCA_MY17_Diesel_Tx" SG_ 145 VehYaw_W_Actl 1;
BA_ "U_B479_MY17_Diesel_Tx" SG_ 145 VehYaw_W_Actl 1;
BA_ "U_B479_MY17_Gas_Tx" SG_ 145 VehYaw_W_Actl 1;
BA_ "U_U611_U625_MY20_Phev_Rx" SG_ 145 VehYaw_W_Actl 1;
BA_ "U_CX482_CX483_MY20_Hev_Rx" SG_ 145 VehYaw_W_Actl 1;
BA_ "U_CX482_CX483_MY20_Gas_Rx" SG_ 145 VehYaw_W_Actl 1;
BA_ "U_CX482_CX483_MY20_Diesel_Rx" SG_ 145 VehYaw_W_Actl 1;
BA_ "U_U611_U625_MY20_Hev_Rx" SG_ 145 VehYaw_W_Actl 1;
BA_ "U_U611_U625_MY20_Gas_Rx" SG_ 145 VehYaw_W_Actl 1;
BA_ "U_U611_U625_MY20_Diesel_Rx" SG_ 145 VehYaw_W_Actl 1;
BA_ "U_B500_MY18_Diesel_Rx" SG_ 145 VehYaw_W_Actl 1;
BA_ "U_B500_MY18_Gas_Rx" SG_ 145 VehYaw_W_Actl 1;
BA_ "U_C490_MY18_Rx" SG_ 145 VehYaw_W_Actl 1;
BA_ "U_B562_MY18_Gas_Rx" SG_ 145 VehYaw_W_Actl 1;
BA_ "U_B515_MCA_MY17_Gas_Rx" SG_ 145 VehYaw_W_Actl 1;
BA_ "U_B515_MCA_MY17_Diesel_Rx" SG_ 145 VehYaw_W_Actl 1;
BA_ "U_B479_MY17_Diesel_Rx" SG_ 145 VehYaw_W_Actl 1;
BA_ "U_B479_MY17_Gas_Rx" SG_ 145 VehYaw_W_Actl 1;
BA_ "U_C519_MY18_5_Gas_Rx" SG_ 145 VehYaw_W_Actl 1;
BA_ "U_C519_MY18_5_Diesel_Rx" SG_ 145 VehYaw_W_Actl 1;
BA_ "GenSigStartValue" SG_ 145 VehYaw_W_Actl 65534;
BA_ "GenSigTimeoutTime_GWM" SG_ 145 VehRol_W_Actl 30;
BA_ "U_CX482_CX483_MY20_Hev_Tx" SG_ 145 VehRol_W_Actl 1;
BA_ "U_CX482_CX483_MY20_Gas_Tx" SG_ 145 VehRol_W_Actl 1;
BA_ "U_CX482_CX483_MY20_Diesel_Tx" SG_ 145 VehRol_W_Actl 1;
BA_ "U_U611_U625_MY20_Hev_Tx" SG_ 145 VehRol_W_Actl 1;
BA_ "U_U611_U625_MY20_Gas_Tx" SG_ 145 VehRol_W_Actl 1;
BA_ "U_U611_U625_MY20_Diesel_Tx" SG_ 145 VehRol_W_Actl 1;
BA_ "U_C519_MY18_5_Gas_Tx" SG_ 145 VehRol_W_Actl 1;
BA_ "U_C519_MY18_5_Diesel_Tx" SG_ 145 VehRol_W_Actl 1;
BA_ "U_B515_MCA_MY17_Gas_Tx" SG_ 145 VehRol_W_Actl 1;
BA_ "U_B515_MCA_MY17_Diesel_Tx" SG_ 145 VehRol_W_Actl 1;
BA_ "U_B479_MY17_Diesel_Tx" SG_ 145 VehRol_W_Actl 1;
BA_ "U_B479_MY17_Gas_Tx" SG_ 145 VehRol_W_Actl 1;
BA_ "U_U611_U625_MY20_Phev_Rx" SG_ 145 VehRol_W_Actl 1;
BA_ "U_CX482_CX483_MY20_Hev_Rx" SG_ 145 VehRol_W_Actl 1;
BA_ "U_CX482_CX483_MY20_Gas_Rx" SG_ 145 VehRol_W_Actl 1;
BA_ "U_CX482_CX483_MY20_Diesel_Rx" SG_ 145 VehRol_W_Actl 1;
BA_ "U_U611_U625_MY20_Hev_Rx" SG_ 145 VehRol_W_Actl 1;
BA_ "U_U611_U625_MY20_Gas_Rx" SG_ 145 VehRol_W_Actl 1;
BA_ "U_U611_U625_MY20_Diesel_Rx" SG_ 145 VehRol_W_Actl 1;
BA_ "U_B500_MY18_Diesel_Rx" SG_ 145 VehRol_W_Actl 1;
BA_ "U_B500_MY18_Gas_Rx" SG_ 145 VehRol_W_Actl 1;
BA_ "U_B562_MY18_Gas_Rx" SG_ 145 VehRol_W_Actl 1;
BA_ "U_C519_MY18_5_Gas_Rx" SG_ 145 VehRol_W_Actl 1;
BA_ "U_C519_MY18_5_Diesel_Rx" SG_ 145 VehRol_W_Actl 1;
BA_ "U_B515_MCA_MY17_Gas_Rx" SG_ 145 VehRol_W_Actl 1;
BA_ "U_B515_MCA_MY17_Diesel_Rx" SG_ 145 VehRol_W_Actl 1;
BA_ "U_B479_MY17_Diesel_Rx" SG_ 145 VehRol_W_Actl 1;
BA_ "U_B479_MY17_Gas_Rx" SG_ 145 VehRol_W_Actl 1;
BA_ "GenSigStartValue" SG_ 145 VehRol_W_Actl 65534;
BA_ "U_U611_U625_MY20_Phev_Rx" SG_ 1828 TesterPhysicalReqSCCM 1;
BA_ "U_CX482_CX483_MY20_Hev_Rx" SG_ 1828 TesterPhysicalReqSCCM 1;
BA_ "U_CX482_CX483_MY20_Gas_Rx" SG_ 1828 TesterPhysicalReqSCCM 1;
BA_ "U_CX482_CX483_MY20_Diesel_Rx" SG_ 1828 TesterPhysicalReqSCCM 1;
BA_ "U_U611_U625_MY20_Hev_Rx" SG_ 1828 TesterPhysicalReqSCCM 1;
BA_ "U_U611_U625_MY20_Gas_Rx" SG_ 1828 TesterPhysicalReqSCCM 1;
BA_ "U_U611_U625_MY20_Diesel_Rx" SG_ 1828 TesterPhysicalReqSCCM 1;
BA_ "U_B500_MY18_Diesel_Rx" SG_ 1828 TesterPhysicalReqSCCM 1;
BA_ "U_B500_MY18_Gas_Rx" SG_ 1828 TesterPhysicalReqSCCM 1;
BA_ "U_C519_MY18_5_Gas_Rx" SG_ 1828 TesterPhysicalReqSCCM 1;
BA_ "U_C519_MY18_5_Diesel_Rx" SG_ 1828 TesterPhysicalReqSCCM 1;
BA_ "U_B515_MCA_MY17_Gas_Rx" SG_ 1828 TesterPhysicalReqSCCM 1;
BA_ "U_B515_MCA_MY17_Diesel_Rx" SG_ 1828 TesterPhysicalReqSCCM 1;
BA_ "U_B479_MY17_Diesel_Rx" SG_ 1828 TesterPhysicalReqSCCM 1;
BA_ "U_B479_MY17_Gas_Rx" SG_ 1828 TesterPhysicalReqSCCM 1;
BA_ "GenSigSendType" SG_ 1828 TesterPhysicalReqSCCM 3;
BA_ "U_U611_U625_MY20_Phev_Rx" SG_ 1970 TesterPhysicalReqHUD 1;
BA_ "U_U611_U625_MY20_Hev_Rx" SG_ 1970 TesterPhysicalReqHUD 1;
BA_ "U_U611_U625_MY20_Gas_Rx" SG_ 1970 TesterPhysicalReqHUD 1;
BA_ "U_U611_U625_MY20_Diesel_Rx" SG_ 1970 TesterPhysicalReqHUD 1;
BA_ "GenSigSendType" SG_ 1970 TesterPhysicalReqHUD 3;
BA_ "U_B515_MCA_MY17_Gas_Tx" SG_ 1045 VehStab_D_Stat 1;
BA_ "U_B515_MCA_MY17_Diesel_Tx" SG_ 1045 VehStab_D_Stat 1;
BA_ "U_B479_MY17_Diesel_Tx" SG_ 1045 VehStab_D_Stat 1;
BA_ "U_B479_MY17_Gas_Tx" SG_ 1045 VehStab_D_Stat 1;
BA_ "GenSigStartValue" SG_ 1045 VehStab_D_Stat 14;
BA_ "U_U611_U625_MY20_Hev_Tx" SG_ 1045 BrkFluidLvl_D_Stat 1;
BA_ "U_U611_U625_MY20_Gas_Tx" SG_ 1045 BrkFluidLvl_D_Stat 1;
BA_ "U_U611_U625_MY20_Diesel_Tx" SG_ 1045 BrkFluidLvl_D_Stat 1;
BA_ "U_C519_MY18_5_Gas_Tx" SG_ 1045 BrkFluidLvl_D_Stat 1;
BA_ "U_C519_MY18_5_Diesel_Tx" SG_ 1045 BrkFluidLvl_D_Stat 1;
BA_ "GenSigTimeoutTime_GWM" SG_ 1045 LsmcBrkDecel_D_Stat 300;
BA_ "U_U611_U625_MY20_Hev_Tx" SG_ 1045 LsmcBrkDecel_D_Stat 1;
BA_ "U_U611_U625_MY20_Gas_Tx" SG_ 1045 LsmcBrkDecel_D_Stat 1;
BA_ "U_U611_U625_MY20_Diesel_Tx" SG_ 1045 LsmcBrkDecel_D_Stat 1;
BA_ "U_C490_MY18_Tx" SG_ 1045 LsmcBrkDecel_D_Stat 1;
BA_ "GenSigTimeoutTime_GWM" SG_ 1045 VehYawNonLin_W_Rq 300;
BA_ "U_CX482_CX483_MY20_Hev_Tx" SG_ 1045 VehYawNonLin_W_Rq 1;
BA_ "U_CX482_CX483_MY20_Gas_Tx" SG_ 1045 VehYawNonLin_W_Rq 1;
BA_ "U_CX482_CX483_MY20_Diesel_Tx" SG_ 1045 VehYawNonLin_W_Rq 1;
BA_ "U_U611_U625_MY20_Hev_Tx" SG_ 1045 VehYawNonLin_W_Rq 1;
BA_ "U_U611_U625_MY20_Gas_Tx" SG_ 1045 VehYawNonLin_W_Rq 1;
BA_ "U_U611_U625_MY20_Diesel_Tx" SG_ 1045 VehYawNonLin_W_Rq 1;
BA_ "U_B500_MY18_Diesel_Tx" SG_ 1045 VehYawNonLin_W_Rq 1;
BA_ "U_B500_MY18_Gas_Tx" SG_ 1045 VehYawNonLin_W_Rq 1;
BA_ "U_C490_MY18_Tx" SG_ 1045 VehYawNonLin_W_Rq 1;
BA_ "U_B562_MY18_Gas_Tx" SG_ 1045 VehYawNonLin_W_Rq 1;
BA_ "U_C519_MY18_5_Gas_Tx" SG_ 1045 VehYawNonLin_W_Rq 1;
BA_ "U_C519_MY18_5_Diesel_Tx" SG_ 1045 VehYawNonLin_W_Rq 1;
BA_ "U_B515_MCA_MY17_Gas_Tx" SG_ 1045 VehYawNonLin_W_Rq 1;
BA_ "U_B515_MCA_MY17_Diesel_Tx" SG_ 1045 VehYawNonLin_W_Rq 1;
BA_ "U_B479_MY17_Diesel_Tx" SG_ 1045 VehYawNonLin_W_Rq 1;
BA_ "U_B479_MY17_Gas_Tx" SG_ 1045 VehYawNonLin_W_Rq 1;
BA_ "U_B562LC_MY15_Gas_Tx" SG_ 1045 VehYawNonLin_W_Rq 1;
BA_ "U_B562LC_MY15_Diesel_Tx" SG_ 1045 VehYawNonLin_W_Rq 1;
BA_ "GenSigStartValue" SG_ 1045 VehYawNonLin_W_Rq 4094;
BA_ "CrossOver_InfoCAN" SG_ 1045 VehYawNonLin_W_Rq 1;
BA_ "GenSigTimeoutTime_GWM" SG_ 1045 VehYawLin_W_Rq 300;
BA_ "U_CX482_CX483_MY20_Hev_Tx" SG_ 1045 VehYawLin_W_Rq 1;
BA_ "U_CX482_CX483_MY20_Gas_Tx" SG_ 1045 VehYawLin_W_Rq 1;
BA_ "U_CX482_CX483_MY20_Diesel_Tx" SG_ 1045 VehYawLin_W_Rq 1;
BA_ "U_U611_U625_MY20_Hev_Tx" SG_ 1045 VehYawLin_W_Rq 1;
BA_ "U_U611_U625_MY20_Gas_Tx" SG_ 1045 VehYawLin_W_Rq 1;
BA_ "U_U611_U625_MY20_Diesel_Tx" SG_ 1045 VehYawLin_W_Rq 1;
BA_ "U_B500_MY18_Diesel_Tx" SG_ 1045 VehYawLin_W_Rq 1;
BA_ "U_B500_MY18_Gas_Tx" SG_ 1045 VehYawLin_W_Rq 1;
BA_ "U_C490_MY18_Tx" SG_ 1045 VehYawLin_W_Rq 1;
BA_ "U_B562_MY18_Gas_Tx" SG_ 1045 VehYawLin_W_Rq 1;
BA_ "U_C519_MY18_5_Gas_Tx" SG_ 1045 VehYawLin_W_Rq 1;
BA_ "U_C519_MY18_5_Diesel_Tx" SG_ 1045 VehYawLin_W_Rq 1;
BA_ "U_B515_MCA_MY17_Gas_Tx" SG_ 1045 VehYawLin_W_Rq 1;
BA_ "U_B515_MCA_MY17_Diesel_Tx" SG_ 1045 VehYawLin_W_Rq 1;
BA_ "U_B479_MY17_Diesel_Tx" SG_ 1045 VehYawLin_W_Rq 1;
BA_ "U_B479_MY17_Gas_Tx" SG_ 1045 VehYawLin_W_Rq 1;
BA_ "U_B562LC_MY15_Gas_Tx" SG_ 1045 VehYawLin_W_Rq 1;
BA_ "U_B562LC_MY15_Diesel_Tx" SG_ 1045 VehYawLin_W_Rq 1;
BA_ "GenSigStartValue" SG_ 1045 VehYawLin_W_Rq 4094;
BA_ "CrossOver_InfoCAN" SG_ 1045 VehYawLin_W_Rq 1;
BA_ "GenSigTimeoutTime_GWM" SG_ 1045 VehVActlBrk_No_Cs 300;
BA_ "U_CX482_CX483_MY20_Hev_Tx" SG_ 1045 VehVActlBrk_No_Cs 1;
BA_ "U_CX482_CX483_MY20_Gas_Tx" SG_ 1045 VehVActlBrk_No_Cs 1;
BA_ "U_CX482_CX483_MY20_Diesel_Tx" SG_ 1045 VehVActlBrk_No_Cs 1;
BA_ "U_U611_U625_MY20_Hev_Tx" SG_ 1045 VehVActlBrk_No_Cs 1;
BA_ "U_U611_U625_MY20_Gas_Tx" SG_ 1045 VehVActlBrk_No_Cs 1;
BA_ "U_U611_U625_MY20_Diesel_Tx" SG_ 1045 VehVActlBrk_No_Cs 1;
BA_ "U_B500_MY18_Diesel_Tx" SG_ 1045 VehVActlBrk_No_Cs 1;
BA_ "U_B500_MY18_Gas_Tx" SG_ 1045 VehVActlBrk_No_Cs 1;
BA_ "U_C490_MY18_Tx" SG_ 1045 VehVActlBrk_No_Cs 1;
BA_ "U_B562_MY18_Gas_Tx" SG_ 1045 VehVActlBrk_No_Cs 1;
BA_ "U_C519_MY18_5_Gas_Tx" SG_ 1045 VehVActlBrk_No_Cs 1;
BA_ "U_C519_MY18_5_Diesel_Tx" SG_ 1045 VehVActlBrk_No_Cs 1;
BA_ "U_B515_MCA_MY17_Gas_Tx" SG_ 1045 VehVActlBrk_No_Cs 1;
BA_ "U_B515_MCA_MY17_Diesel_Tx" SG_ 1045 VehVActlBrk_No_Cs 1;
BA_ "U_B479_MY17_Diesel_Tx" SG_ 1045 VehVActlBrk_No_Cs 1;
BA_ "U_B479_MY17_Gas_Tx" SG_ 1045 VehVActlBrk_No_Cs 1;
BA_ "U_B562LC_MY15_Gas_Tx" SG_ 1045 VehVActlBrk_No_Cs 1;
BA_ "U_B562LC_MY15_Diesel_Tx" SG_ 1045 VehVActlBrk_No_Cs 1;
BA_ "U_U611_U625_MY20_Phev_Rx" SG_ 1045 VehVActlBrk_No_Cs 1;
BA_ "U_CX482_CX483_MY20_Hev_Rx" SG_ 1045 VehVActlBrk_No_Cs 1;
BA_ "U_CX482_CX483_MY20_Gas_Rx" SG_ 1045 VehVActlBrk_No_Cs 1;
BA_ "U_CX482_CX483_MY20_Diesel_Rx" SG_ 1045 VehVActlBrk_No_Cs 1;
BA_ "U_B500_MY18_Diesel_Rx" SG_ 1045 VehVActlBrk_No_Cs 1;
BA_ "U_B500_MY18_Gas_Rx" SG_ 1045 VehVActlBrk_No_Cs 1;
BA_ "U_C519_MY18_5_Gas_Rx" SG_ 1045 VehVActlBrk_No_Cs 1;
BA_ "U_C519_MY18_5_Diesel_Rx" SG_ 1045 VehVActlBrk_No_Cs 1;
BA_ "U_B479_MY17_Diesel_Rx" SG_ 1045 VehVActlBrk_No_Cs 1;
BA_ "U_B479_MY17_Gas_Rx" SG_ 1045 VehVActlBrk_No_Cs 1;
BA_ "U_U611_U625_MY20_Hev_Rx" SG_ 1045 VehVActlBrk_No_Cs 1;
BA_ "U_U611_U625_MY20_Gas_Rx" SG_ 1045 VehVActlBrk_No_Cs 1;
BA_ "U_U611_U625_MY20_Diesel_Rx" SG_ 1045 VehVActlBrk_No_Cs 1;
BA_ "CrossOver_InfoCAN" SG_ 1045 VehVActlBrk_No_Cs 1;
BA_ "GenSigTimeoutTime_GWM" SG_ 1045 Veh_V_ActlBrk 300;
BA_ "U_CX482_CX483_MY20_Hev_Tx" SG_ 1045 Veh_V_ActlBrk 1;
BA_ "U_CX482_CX483_MY20_Gas_Tx" SG_ 1045 Veh_V_ActlBrk 1;
BA_ "U_CX482_CX483_MY20_Diesel_Tx" SG_ 1045 Veh_V_ActlBrk 1;
BA_ "U_U611_U625_MY20_Hev_Tx" SG_ 1045 Veh_V_ActlBrk 1;
BA_ "U_U611_U625_MY20_Gas_Tx" SG_ 1045 Veh_V_ActlBrk 1;
BA_ "U_U611_U625_MY20_Diesel_Tx" SG_ 1045 Veh_V_ActlBrk 1;
BA_ "U_B500_MY18_Diesel_Tx" SG_ 1045 Veh_V_ActlBrk 1;
BA_ "U_B500_MY18_Gas_Tx" SG_ 1045 Veh_V_ActlBrk 1;
BA_ "U_C490_MY18_Tx" SG_ 1045 Veh_V_ActlBrk 1;
BA_ "U_B562_MY18_Gas_Tx" SG_ 1045 Veh_V_ActlBrk 1;
BA_ "U_C519_MY18_5_Gas_Tx" SG_ 1045 Veh_V_ActlBrk 1;
BA_ "U_C519_MY18_5_Diesel_Tx" SG_ 1045 Veh_V_ActlBrk 1;
BA_ "U_B515_MCA_MY17_Gas_Tx" SG_ 1045 Veh_V_ActlBrk 1;
BA_ "U_B515_MCA_MY17_Diesel_Tx" SG_ 1045 Veh_V_ActlBrk 1;
BA_ "U_B479_MY17_Diesel_Tx" SG_ 1045 Veh_V_ActlBrk 1;
BA_ "U_B479_MY17_Gas_Tx" SG_ 1045 Veh_V_ActlBrk 1;
BA_ "U_B562LC_MY15_Gas_Tx" SG_ 1045 Veh_V_ActlBrk 1;
BA_ "U_B562LC_MY15_Diesel_Tx" SG_ 1045 Veh_V_ActlBrk 1;
BA_ "U_B500_MY18_Diesel_Rx" SG_ 1045 Veh_V_ActlBrk 1;
BA_ "U_B500_MY18_Gas_Rx" SG_ 1045 Veh_V_ActlBrk 1;
BA_ "U_B479_MY17_Diesel_Rx" SG_ 1045 Veh_V_ActlBrk 1;
BA_ "U_B479_MY17_Gas_Rx" SG_ 1045 Veh_V_ActlBrk 1;
BA_ "U_U611_U625_MY20_Phev_Rx" SG_ 1045 Veh_V_ActlBrk 1;
BA_ "U_CX482_CX483_MY20_Hev_Rx" SG_ 1045 Veh_V_ActlBrk 1;
BA_ "U_CX482_CX483_MY20_Gas_Rx" SG_ 1045 Veh_V_ActlBrk 1;
BA_ "U_CX482_CX483_MY20_Diesel_Rx" SG_ 1045 Veh_V_ActlBrk 1;
BA_ "U_U611_U625_MY20_Hev_Rx" SG_ 1045 Veh_V_ActlBrk 1;
BA_ "U_U611_U625_MY20_Gas_Rx" SG_ 1045 Veh_V_ActlBrk 1;
BA_ "U_U611_U625_MY20_Diesel_Rx" SG_ 1045 Veh_V_ActlBrk 1;
BA_ "U_C519_MY18_5_Gas_Rx" SG_ 1045 Veh_V_ActlBrk 1;
BA_ "U_C519_MY18_5_Diesel_Rx" SG_ 1045 Veh_V_ActlBrk 1;
BA_ "CrossOver_InfoCAN" SG_ 1045 Veh_V_ActlBrk 1;
BA_ "GenSigTimeoutTime_GWM" SG_ 1045 VehVActlBrk_No_Cnt 300;
BA_ "U_CX482_CX483_MY20_Hev_Tx" SG_ 1045 VehVActlBrk_No_Cnt 1;
BA_ "U_CX482_CX483_MY20_Gas_Tx" SG_ 1045 VehVActlBrk_No_Cnt 1;
BA_ "U_CX482_CX483_MY20_Diesel_Tx" SG_ 1045 VehVActlBrk_No_Cnt 1;
BA_ "U_U611_U625_MY20_Hev_Tx" SG_ 1045 VehVActlBrk_No_Cnt 1;
BA_ "U_U611_U625_MY20_Gas_Tx" SG_ 1045 VehVActlBrk_No_Cnt 1;
BA_ "U_U611_U625_MY20_Diesel_Tx" SG_ 1045 VehVActlBrk_No_Cnt 1;
BA_ "U_B500_MY18_Diesel_Tx" SG_ 1045 VehVActlBrk_No_Cnt 1;
BA_ "U_B500_MY18_Gas_Tx" SG_ 1045 VehVActlBrk_No_Cnt 1;
BA_ "U_C490_MY18_Tx" SG_ 1045 VehVActlBrk_No_Cnt 1;
BA_ "U_B562_MY18_Gas_Tx" SG_ 1045 VehVActlBrk_No_Cnt 1;
BA_ "U_C519_MY18_5_Gas_Tx" SG_ 1045 VehVActlBrk_No_Cnt 1;
BA_ "U_C519_MY18_5_Diesel_Tx" SG_ 1045 VehVActlBrk_No_Cnt 1;
BA_ "U_B515_MCA_MY17_Gas_Tx" SG_ 1045 VehVActlBrk_No_Cnt 1;
BA_ "U_B515_MCA_MY17_Diesel_Tx" SG_ 1045 VehVActlBrk_No_Cnt 1;
BA_ "U_B479_MY17_Diesel_Tx" SG_ 1045 VehVActlBrk_No_Cnt 1;
BA_ "U_B479_MY17_Gas_Tx" SG_ 1045 VehVActlBrk_No_Cnt 1;
BA_ "U_B562LC_MY15_Gas_Tx" SG_ 1045 VehVActlBrk_No_Cnt 1;
BA_ "U_B562LC_MY15_Diesel_Tx" SG_ 1045 VehVActlBrk_No_Cnt 1;
BA_ "U_U611_U625_MY20_Phev_Rx" SG_ 1045 VehVActlBrk_No_Cnt 1;
BA_ "U_CX482_CX483_MY20_Hev_Rx" SG_ 1045 VehVActlBrk_No_Cnt 1;
BA_ "U_CX482_CX483_MY20_Gas_Rx" SG_ 1045 VehVActlBrk_No_Cnt 1;
BA_ "U_CX482_CX483_MY20_Diesel_Rx" SG_ 1045 VehVActlBrk_No_Cnt 1;
BA_ "U_B500_MY18_Diesel_Rx" SG_ 1045 VehVActlBrk_No_Cnt 1;
BA_ "U_B500_MY18_Gas_Rx" SG_ 1045 VehVActlBrk_No_Cnt 1;
BA_ "U_C519_MY18_5_Gas_Rx" SG_ 1045 VehVActlBrk_No_Cnt 1;
BA_ "U_C519_MY18_5_Diesel_Rx" SG_ 1045 VehVActlBrk_No_Cnt 1;
BA_ "U_B479_MY17_Diesel_Rx" SG_ 1045 VehVActlBrk_No_Cnt 1;
BA_ "U_B479_MY17_Gas_Rx" SG_ 1045 VehVActlBrk_No_Cnt 1;
BA_ "U_U611_U625_MY20_Hev_Rx" SG_ 1045 VehVActlBrk_No_Cnt 1;
BA_ "U_U611_U625_MY20_Gas_Rx" SG_ 1045 VehVActlBrk_No_Cnt 1;
BA_ "U_U611_U625_MY20_Diesel_Rx" SG_ 1045 VehVActlBrk_No_Cnt 1;
BA_ "CrossOver_InfoCAN" SG_ 1045 VehVActlBrk_No_Cnt 1;
BA_ "GenSigTimeoutTime_GWM" SG_ 1045 VehVActlBrk_D_Qf 300;
BA_ "U_CX482_CX483_MY20_Hev_Tx" SG_ 1045 VehVActlBrk_D_Qf 1;
BA_ "U_CX482_CX483_MY20_Gas_Tx" SG_ 1045 VehVActlBrk_D_Qf 1;
BA_ "U_CX482_CX483_MY20_Diesel_Tx" SG_ 1045 VehVActlBrk_D_Qf 1;
BA_ "U_U611_U625_MY20_Hev_Tx" SG_ 1045 VehVActlBrk_D_Qf 1;
BA_ "U_U611_U625_MY20_Gas_Tx" SG_ 1045 VehVActlBrk_D_Qf 1;
BA_ "U_U611_U625_MY20_Diesel_Tx" SG_ 1045 VehVActlBrk_D_Qf 1;
BA_ "U_B500_MY18_Diesel_Tx" SG_ 1045 VehVActlBrk_D_Qf 1;
BA_ "U_B500_MY18_Gas_Tx" SG_ 1045 VehVActlBrk_D_Qf 1;
BA_ "U_C490_MY18_Tx" SG_ 1045 VehVActlBrk_D_Qf 1;
BA_ "U_B562_MY18_Gas_Tx" SG_ 1045 VehVActlBrk_D_Qf 1;
BA_ "U_C519_MY18_5_Gas_Tx" SG_ 1045 VehVActlBrk_D_Qf 1;
BA_ "U_C519_MY18_5_Diesel_Tx" SG_ 1045 VehVActlBrk_D_Qf 1;
BA_ "U_B515_MCA_MY17_Gas_Tx" SG_ 1045 VehVActlBrk_D_Qf 1;
BA_ "U_B515_MCA_MY17_Diesel_Tx" SG_ 1045 VehVActlBrk_D_Qf 1;
BA_ "U_B479_MY17_Diesel_Tx" SG_ 1045 VehVActlBrk_D_Qf 1;
BA_ "U_B479_MY17_Gas_Tx" SG_ 1045 VehVActlBrk_D_Qf 1;
BA_ "U_B562LC_MY15_Gas_Tx" SG_ 1045 VehVActlBrk_D_Qf 1;
BA_ "U_B562LC_MY15_Diesel_Tx" SG_ 1045 VehVActlBrk_D_Qf 1;
BA_ "U_B500_MY18_Diesel_Rx" SG_ 1045 VehVActlBrk_D_Qf 1;
BA_ "U_B500_MY18_Gas_Rx" SG_ 1045 VehVActlBrk_D_Qf 1;
BA_ "U_B479_MY17_Diesel_Rx" SG_ 1045 VehVActlBrk_D_Qf 1;
BA_ "U_B479_MY17_Gas_Rx" SG_ 1045 VehVActlBrk_D_Qf 1;
BA_ "U_U611_U625_MY20_Phev_Rx" SG_ 1045 VehVActlBrk_D_Qf 1;
BA_ "U_CX482_CX483_MY20_Hev_Rx" SG_ 1045 VehVActlBrk_D_Qf 1;
BA_ "U_CX482_CX483_MY20_Gas_Rx" SG_ 1045 VehVActlBrk_D_Qf 1;
BA_ "U_CX482_CX483_MY20_Diesel_Rx" SG_ 1045 VehVActlBrk_D_Qf 1;
BA_ "U_U611_U625_MY20_Hev_Rx" SG_ 1045 VehVActlBrk_D_Qf 1;
BA_ "U_U611_U625_MY20_Gas_Rx" SG_ 1045 VehVActlBrk_D_Qf 1;
BA_ "U_U611_U625_MY20_Diesel_Rx" SG_ 1045 VehVActlBrk_D_Qf 1;
BA_ "U_C519_MY18_5_Gas_Rx" SG_ 1045 VehVActlBrk_D_Qf 1;
BA_ "U_C519_MY18_5_Diesel_Rx" SG_ 1045 VehVActlBrk_D_Qf 1;
BA_ "CrossOver_InfoCAN" SG_ 1045 VehVActlBrk_D_Qf 1;
BA_ "GenSigTimeoutTime_GWM" SG_ 146 VehVert2_A_Actl 30;
BA_ "U_CX482_CX483_MY20_Hev_Tx" SG_ 146 VehVert2_A_Actl 1;
BA_ "U_CX482_CX483_MY20_Gas_Tx" SG_ 146 VehVert2_A_Actl 1;
BA_ "U_CX482_CX483_MY20_Diesel_Tx" SG_ 146 VehVert2_A_Actl 1;
BA_ "U_C519_MY18_5_Gas_Tx" SG_ 146 VehVert2_A_Actl 1;
BA_ "U_C519_MY18_5_Diesel_Tx" SG_ 146 VehVert2_A_Actl 1;
BA_ "U_B515_MCA_MY17_Gas_Tx" SG_ 146 VehVert2_A_Actl 1;
BA_ "U_B515_MCA_MY17_Diesel_Tx" SG_ 146 VehVert2_A_Actl 1;
BA_ "U_B479_MY17_Diesel_Tx" SG_ 146 VehVert2_A_Actl 1;
BA_ "U_B479_MY17_Gas_Tx" SG_ 146 VehVert2_A_Actl 1;
BA_ "U_CX482_CX483_MY20_Hev_Rx" SG_ 146 VehVert2_A_Actl 1;
BA_ "U_CX482_CX483_MY20_Gas_Rx" SG_ 146 VehVert2_A_Actl 1;
BA_ "U_CX482_CX483_MY20_Diesel_Rx" SG_ 146 VehVert2_A_Actl 1;
BA_ "U_B500_MY18_Diesel_Rx" SG_ 146 VehVert2_A_Actl 1;
BA_ "U_B500_MY18_Gas_Rx" SG_ 146 VehVert2_A_Actl 1;
BA_ "U_B562_MY18_Gas_Rx" SG_ 146 VehVert2_A_Actl 1;
BA_ "U_B515_MCA_MY17_Gas_Rx" SG_ 146 VehVert2_A_Actl 1;
BA_ "U_B515_MCA_MY17_Diesel_Rx" SG_ 146 VehVert2_A_Actl 1;
BA_ "U_B479_MY17_Diesel_Rx" SG_ 146 VehVert2_A_Actl 1;
BA_ "U_B479_MY17_Gas_Rx" SG_ 146 VehVert2_A_Actl 1;
BA_ "U_U611_U625_MY20_Phev_Rx" SG_ 146 VehVert2_A_Actl 1;
BA_ "U_U611_U625_MY20_Hev_Rx" SG_ 146 VehVert2_A_Actl 1;
BA_ "U_U611_U625_MY20_Gas_Rx" SG_ 146 VehVert2_A_Actl 1;
BA_ "U_U611_U625_MY20_Diesel_Rx" SG_ 146 VehVert2_A_Actl 1;
BA_ "U_C519_MY18_5_Gas_Rx" SG_ 146 VehVert2_A_Actl 1;
BA_ "U_C519_MY18_5_Diesel_Rx" SG_ 146 VehVert2_A_Actl 1;
BA_ "GenSigStartValue" SG_ 146 VehVert2_A_Actl 8190;
BA_ "GenSigTimeoutTime_GWM" SG_ 146 VehLatLongVertA_No_Cs 30;
BA_ "U_CX482_CX483_MY20_Hev_Tx" SG_ 146 VehLatLongVertA_No_Cs 1;
BA_ "U_CX482_CX483_MY20_Gas_Tx" SG_ 146 VehLatLongVertA_No_Cs 1;
BA_ "U_CX482_CX483_MY20_Diesel_Tx" SG_ 146 VehLatLongVertA_No_Cs 1;
BA_ "U_B500_MY18_Diesel_Tx" SG_ 146 VehLatLongVertA_No_Cs 1;
BA_ "U_B500_MY18_Gas_Tx" SG_ 146 VehLatLongVertA_No_Cs 1;
BA_ "U_C490_MY18_Tx" SG_ 146 VehLatLongVertA_No_Cs 1;
BA_ "U_B562_MY18_Gas_Tx" SG_ 146 VehLatLongVertA_No_Cs 1;
BA_ "U_C519_MY18_5_Gas_Tx" SG_ 146 VehLatLongVertA_No_Cs 1;
BA_ "U_C519_MY18_5_Diesel_Tx" SG_ 146 VehLatLongVertA_No_Cs 1;
BA_ "U_B515_MCA_MY17_Gas_Tx" SG_ 146 VehLatLongVertA_No_Cs 1;
BA_ "U_B515_MCA_MY17_Diesel_Tx" SG_ 146 VehLatLongVertA_No_Cs 1;
BA_ "U_B479_MY17_Diesel_Tx" SG_ 146 VehLatLongVertA_No_Cs 1;
BA_ "U_B479_MY17_Gas_Tx" SG_ 146 VehLatLongVertA_No_Cs 1;
BA_ "U_U611_U625_MY20_Hev_Rx" SG_ 146 VehLatLongVertA_No_Cs 1;
BA_ "U_U611_U625_MY20_Gas_Rx" SG_ 146 VehLatLongVertA_No_Cs 1;
BA_ "U_U611_U625_MY20_Diesel_Rx" SG_ 146 VehLatLongVertA_No_Cs 1;
BA_ "U_CX482_CX483_MY20_Hev_Rx" SG_ 146 VehLatLongVertA_No_Cs 1;
BA_ "U_CX482_CX483_MY20_Gas_Rx" SG_ 146 VehLatLongVertA_No_Cs 1;
BA_ "U_CX482_CX483_MY20_Diesel_Rx" SG_ 146 VehLatLongVertA_No_Cs 1;
BA_ "U_B500_MY18_Diesel_Rx" SG_ 146 VehLatLongVertA_No_Cs 1;
BA_ "U_B500_MY18_Gas_Rx" SG_ 146 VehLatLongVertA_No_Cs 1;
BA_ "U_C490_MY18_Rx" SG_ 146 VehLatLongVertA_No_Cs 1;
BA_ "U_B562_MY18_Gas_Rx" SG_ 146 VehLatLongVertA_No_Cs 1;
BA_ "U_C519_MY18_5_Gas_Rx" SG_ 146 VehLatLongVertA_No_Cs 1;
BA_ "U_C519_MY18_5_Diesel_Rx" SG_ 146 VehLatLongVertA_No_Cs 1;
BA_ "U_B515_MCA_MY17_Gas_Rx" SG_ 146 VehLatLongVertA_No_Cs 1;
BA_ "U_B515_MCA_MY17_Diesel_Rx" SG_ 146 VehLatLongVertA_No_Cs 1;
BA_ "U_B479_MY17_Diesel_Rx" SG_ 146 VehLatLongVertA_No_Cs 1;
BA_ "U_B479_MY17_Gas_Rx" SG_ 146 VehLatLongVertA_No_Cs 1;
BA_ "GenSigTimeoutTime_GWM" SG_ 146 VehLatLongVert_No_Cnt 30;
BA_ "U_CX482_CX483_MY20_Hev_Tx" SG_ 146 VehLatLongVert_No_Cnt 1;
BA_ "U_CX482_CX483_MY20_Gas_Tx" SG_ 146 VehLatLongVert_No_Cnt 1;
BA_ "U_CX482_CX483_MY20_Diesel_Tx" SG_ 146 VehLatLongVert_No_Cnt 1;
BA_ "U_B500_MY18_Diesel_Tx" SG_ 146 VehLatLongVert_No_Cnt 1;
BA_ "U_B500_MY18_Gas_Tx" SG_ 146 VehLatLongVert_No_Cnt 1;
BA_ "U_C490_MY18_Tx" SG_ 146 VehLatLongVert_No_Cnt 1;
BA_ "U_B562_MY18_Gas_Tx" SG_ 146 VehLatLongVert_No_Cnt 1;
BA_ "U_C519_MY18_5_Gas_Tx" SG_ 146 VehLatLongVert_No_Cnt 1;
BA_ "U_C519_MY18_5_Diesel_Tx" SG_ 146 VehLatLongVert_No_Cnt 1;
BA_ "U_B515_MCA_MY17_Gas_Tx" SG_ 146 VehLatLongVert_No_Cnt 1;
BA_ "U_B515_MCA_MY17_Diesel_Tx" SG_ 146 VehLatLongVert_No_Cnt 1;
BA_ "U_B479_MY17_Diesel_Tx" SG_ 146 VehLatLongVert_No_Cnt 1;
BA_ "U_B479_MY17_Gas_Tx" SG_ 146 VehLatLongVert_No_Cnt 1;
BA_ "U_CX482_CX483_MY20_Hev_Rx" SG_ 146 VehLatLongVert_No_Cnt 1;
BA_ "U_CX482_CX483_MY20_Gas_Rx" SG_ 146 VehLatLongVert_No_Cnt 1;
BA_ "U_CX482_CX483_MY20_Diesel_Rx" SG_ 146 VehLatLongVert_No_Cnt 1;
BA_ "U_B500_MY18_Diesel_Rx" SG_ 146 VehLatLongVert_No_Cnt 1;
BA_ "U_B500_MY18_Gas_Rx" SG_ 146 VehLatLongVert_No_Cnt 1;
BA_ "U_C490_MY18_Rx" SG_ 146 VehLatLongVert_No_Cnt 1;
BA_ "U_B562_MY18_Gas_Rx" SG_ 146 VehLatLongVert_No_Cnt 1;
BA_ "U_B515_MCA_MY17_Gas_Rx" SG_ 146 VehLatLongVert_No_Cnt 1;
BA_ "U_B515_MCA_MY17_Diesel_Rx" SG_ 146 VehLatLongVert_No_Cnt 1;
BA_ "U_B479_MY17_Diesel_Rx" SG_ 146 VehLatLongVert_No_Cnt 1;
BA_ "U_B479_MY17_Gas_Rx" SG_ 146 VehLatLongVert_No_Cnt 1;
BA_ "U_U611_U625_MY20_Phev_Rx" SG_ 146 VehLatLongVert_No_Cnt 1;
BA_ "U_U611_U625_MY20_Hev_Rx" SG_ 146 VehLatLongVert_No_Cnt 1;
BA_ "U_U611_U625_MY20_Gas_Rx" SG_ 146 VehLatLongVert_No_Cnt 1;
BA_ "U_U611_U625_MY20_Diesel_Rx" SG_ 146 VehLatLongVert_No_Cnt 1;
BA_ "U_C519_MY18_5_Gas_Rx" SG_ 146 VehLatLongVert_No_Cnt 1;
BA_ "U_C519_MY18_5_Diesel_Rx" SG_ 146 VehLatLongVert_No_Cnt 1;
BA_ "GenSigTimeoutTime_GWM" SG_ 146 VehLong2_A_Actl 30;
BA_ "U_CX482_CX483_MY20_Hev_Tx" SG_ 146 VehLong2_A_Actl 1;
BA_ "U_CX482_CX483_MY20_Gas_Tx" SG_ 146 VehLong2_A_Actl 1;
BA_ "U_CX482_CX483_MY20_Diesel_Tx" SG_ 146 VehLong2_A_Actl 1;
BA_ "U_B500_MY18_Diesel_Tx" SG_ 146 VehLong2_A_Actl 1;
BA_ "U_B500_MY18_Gas_Tx" SG_ 146 VehLong2_A_Actl 1;
BA_ "U_C490_MY18_Tx" SG_ 146 VehLong2_A_Actl 1;
BA_ "U_B562_MY18_Gas_Tx" SG_ 146 VehLong2_A_Actl 1;
BA_ "U_C519_MY18_5_Gas_Tx" SG_ 146 VehLong2_A_Actl 1;
BA_ "U_C519_MY18_5_Diesel_Tx" SG_ 146 VehLong2_A_Actl 1;
BA_ "U_B515_MCA_MY17_Gas_Tx" SG_ 146 VehLong2_A_Actl 1;
BA_ "U_B515_MCA_MY17_Diesel_Tx" SG_ 146 VehLong2_A_Actl 1;
BA_ "U_B479_MY17_Diesel_Tx" SG_ 146 VehLong2_A_Actl 1;
BA_ "U_B479_MY17_Gas_Tx" SG_ 146 VehLong2_A_Actl 1;
BA_ "U_U611_U625_MY20_Phev_Rx" SG_ 146 VehLong2_A_Actl 1;
BA_ "U_CX482_CX483_MY20_Hev_Rx" SG_ 146 VehLong2_A_Actl 1;
BA_ "U_CX482_CX483_MY20_Gas_Rx" SG_ 146 VehLong2_A_Actl 1;
BA_ "U_CX482_CX483_MY20_Diesel_Rx" SG_ 146 VehLong2_A_Actl 1;
BA_ "U_U611_U625_MY20_Hev_Rx" SG_ 146 VehLong2_A_Actl 1;
BA_ "U_U611_U625_MY20_Gas_Rx" SG_ 146 VehLong2_A_Actl 1;
BA_ "U_U611_U625_MY20_Diesel_Rx" SG_ 146 VehLong2_A_Actl 1;
BA_ "U_B500_MY18_Diesel_Rx" SG_ 146 VehLong2_A_Actl 1;
BA_ "U_B500_MY18_Gas_Rx" SG_ 146 VehLong2_A_Actl 1;
BA_ "U_C490_MY18_Rx" SG_ 146 VehLong2_A_Actl 1;
BA_ "U_B562_MY18_Gas_Rx" SG_ 146 VehLong2_A_Actl 1;
BA_ "U_C519_MY18_5_Gas_Rx" SG_ 146 VehLong2_A_Actl 1;
BA_ "U_C519_MY18_5_Diesel_Rx" SG_ 146 VehLong2_A_Actl 1;
BA_ "U_B515_MCA_MY17_Gas_Rx" SG_ 146 VehLong2_A_Actl 1;
BA_ "U_B515_MCA_MY17_Diesel_Rx" SG_ 146 VehLong2_A_Actl 1;
BA_ "U_B479_MY17_Diesel_Rx" SG_ 146 VehLong2_A_Actl 1;
BA_ "U_B479_MY17_Gas_Rx" SG_ 146 VehLong2_A_Actl 1;
BA_ "GenSigStartValue" SG_ 146 VehLong2_A_Actl 8190;
BA_ "GenSigTimeoutTime_GWM" SG_ 146 VehLat2_A_Actl 30;
BA_ "U_CX482_CX483_MY20_Hev_Tx" SG_ 146 VehLat2_A_Actl 1;
BA_ "U_CX482_CX483_MY20_Gas_Tx" SG_ 146 VehLat2_A_Actl 1;
BA_ "U_CX482_CX483_MY20_Diesel_Tx" SG_ 146 VehLat2_A_Actl 1;
BA_ "U_B500_MY18_Diesel_Tx" SG_ 146 VehLat2_A_Actl 1;
BA_ "U_B500_MY18_Gas_Tx" SG_ 146 VehLat2_A_Actl 1;
BA_ "U_C490_MY18_Tx" SG_ 146 VehLat2_A_Actl 1;
BA_ "U_B562_MY18_Gas_Tx" SG_ 146 VehLat2_A_Actl 1;
BA_ "U_C519_MY18_5_Gas_Tx" SG_ 146 VehLat2_A_Actl 1;
BA_ "U_C519_MY18_5_Diesel_Tx" SG_ 146 VehLat2_A_Actl 1;
BA_ "U_B515_MCA_MY17_Gas_Tx" SG_ 146 VehLat2_A_Actl 1;
BA_ "U_B515_MCA_MY17_Diesel_Tx" SG_ 146 VehLat2_A_Actl 1;
BA_ "U_B479_MY17_Diesel_Tx" SG_ 146 VehLat2_A_Actl 1;
BA_ "U_B479_MY17_Gas_Tx" SG_ 146 VehLat2_A_Actl 1;
BA_ "U_CX482_CX483_MY20_Hev_Rx" SG_ 146 VehLat2_A_Actl 1;
BA_ "U_CX482_CX483_MY20_Gas_Rx" SG_ 146 VehLat2_A_Actl 1;
BA_ "U_CX482_CX483_MY20_Diesel_Rx" SG_ 146 VehLat2_A_Actl 1;
BA_ "U_B500_MY18_Diesel_Rx" SG_ 146 VehLat2_A_Actl 1;
BA_ "U_B500_MY18_Gas_Rx" SG_ 146 VehLat2_A_Actl 1;
BA_ "U_C490_MY18_Rx" SG_ 146 VehLat2_A_Actl 1;
BA_ "U_B562_MY18_Gas_Rx" SG_ 146 VehLat2_A_Actl 1;
BA_ "U_B515_MCA_MY17_Gas_Rx" SG_ 146 VehLat2_A_Actl 1;
BA_ "U_B515_MCA_MY17_Diesel_Rx" SG_ 146 VehLat2_A_Actl 1;
BA_ "U_B479_MY17_Diesel_Rx" SG_ 146 VehLat2_A_Actl 1;
BA_ "U_B479_MY17_Gas_Rx" SG_ 146 VehLat2_A_Actl 1;
BA_ "U_U611_U625_MY20_Phev_Rx" SG_ 146 VehLat2_A_Actl 1;
BA_ "U_U611_U625_MY20_Hev_Rx" SG_ 146 VehLat2_A_Actl 1;
BA_ "U_U611_U625_MY20_Gas_Rx" SG_ 146 VehLat2_A_Actl 1;
BA_ "U_U611_U625_MY20_Diesel_Rx" SG_ 146 VehLat2_A_Actl 1;
BA_ "U_C519_MY18_5_Gas_Rx" SG_ 146 VehLat2_A_Actl 1;
BA_ "U_C519_MY18_5_Diesel_Rx" SG_ 146 VehLat2_A_Actl 1;
BA_ "GenSigStartValue" SG_ 146 VehLat2_A_Actl 8190;
BA_ "GenSigTimeoutTime_GWM" SG_ 146 VehVertAActl_D_Qf 30;
BA_ "U_CX482_CX483_MY20_Hev_Tx" SG_ 146 VehVertAActl_D_Qf 1;
BA_ "U_CX482_CX483_MY20_Gas_Tx" SG_ 146 VehVertAActl_D_Qf 1;
BA_ "U_CX482_CX483_MY20_Diesel_Tx" SG_ 146 VehVertAActl_D_Qf 1;
BA_ "U_B500_MY18_Diesel_Tx" SG_ 146 VehVertAActl_D_Qf 1;
BA_ "U_B500_MY18_Gas_Tx" SG_ 146 VehVertAActl_D_Qf 1;
BA_ "U_C490_MY18_Tx" SG_ 146 VehVertAActl_D_Qf 1;
BA_ "U_B562_MY18_Gas_Tx" SG_ 146 VehVertAActl_D_Qf 1;
BA_ "U_C519_MY18_5_Gas_Tx" SG_ 146 VehVertAActl_D_Qf 1;
BA_ "U_C519_MY18_5_Diesel_Tx" SG_ 146 VehVertAActl_D_Qf 1;
BA_ "U_B515_MCA_MY17_Gas_Tx" SG_ 146 VehVertAActl_D_Qf 1;
BA_ "U_B515_MCA_MY17_Diesel_Tx" SG_ 146 VehVertAActl_D_Qf 1;
BA_ "U_B479_MY17_Diesel_Tx" SG_ 146 VehVertAActl_D_Qf 1;
BA_ "U_B479_MY17_Gas_Tx" SG_ 146 VehVertAActl_D_Qf 1;
BA_ "U_U611_U625_MY20_Phev_Rx" SG_ 146 VehVertAActl_D_Qf 1;
BA_ "U_U611_U625_MY20_Hev_Rx" SG_ 146 VehVertAActl_D_Qf 1;
BA_ "U_U611_U625_MY20_Gas_Rx" SG_ 146 VehVertAActl_D_Qf 1;
BA_ "U_U611_U625_MY20_Diesel_Rx" SG_ 146 VehVertAActl_D_Qf 1;
BA_ "U_C519_MY18_5_Gas_Rx" SG_ 146 VehVertAActl_D_Qf 1;
BA_ "U_C519_MY18_5_Diesel_Rx" SG_ 146 VehVertAActl_D_Qf 1;
BA_ "GenSigStartValue" SG_ 146 VehVertAActl_D_Qf 1;
BA_ "GenSigTimeoutTime_GWM" SG_ 146 VehLongAActl_D_Qf 30;
BA_ "U_CX482_CX483_MY20_Hev_Tx" SG_ 146 VehLongAActl_D_Qf 1;
BA_ "U_CX482_CX483_MY20_Gas_Tx" SG_ 146 VehLongAActl_D_Qf 1;
BA_ "U_CX482_CX483_MY20_Diesel_Tx" SG_ 146 VehLongAActl_D_Qf 1;
BA_ "U_B500_MY18_Diesel_Tx" SG_ 146 VehLongAActl_D_Qf 1;
BA_ "U_B500_MY18_Gas_Tx" SG_ 146 VehLongAActl_D_Qf 1;
BA_ "U_C490_MY18_Tx" SG_ 146 VehLongAActl_D_Qf 1;
BA_ "U_B562_MY18_Gas_Tx" SG_ 146 VehLongAActl_D_Qf 1;
BA_ "U_C519_MY18_5_Gas_Tx" SG_ 146 VehLongAActl_D_Qf 1;
BA_ "U_C519_MY18_5_Diesel_Tx" SG_ 146 VehLongAActl_D_Qf 1;
BA_ "U_B515_MCA_MY17_Gas_Tx" SG_ 146 VehLongAActl_D_Qf 1;
BA_ "U_B515_MCA_MY17_Diesel_Tx" SG_ 146 VehLongAActl_D_Qf 1;
BA_ "U_B479_MY17_Diesel_Tx" SG_ 146 VehLongAActl_D_Qf 1;
BA_ "U_B479_MY17_Gas_Tx" SG_ 146 VehLongAActl_D_Qf 1;
BA_ "U_U611_U625_MY20_Phev_Rx" SG_ 146 VehLongAActl_D_Qf 1;
BA_ "U_CX482_CX483_MY20_Hev_Rx" SG_ 146 VehLongAActl_D_Qf 1;
BA_ "U_CX482_CX483_MY20_Gas_Rx" SG_ 146 VehLongAActl_D_Qf 1;
BA_ "U_CX482_CX483_MY20_Diesel_Rx" SG_ 146 VehLongAActl_D_Qf 1;
BA_ "U_U611_U625_MY20_Hev_Rx" SG_ 146 VehLongAActl_D_Qf 1;
BA_ "U_U611_U625_MY20_Gas_Rx" SG_ 146 VehLongAActl_D_Qf 1;
BA_ "U_U611_U625_MY20_Diesel_Rx" SG_ 146 VehLongAActl_D_Qf 1;
BA_ "U_B500_MY18_Diesel_Rx" SG_ 146 VehLongAActl_D_Qf 1;
BA_ "U_B500_MY18_Gas_Rx" SG_ 146 VehLongAActl_D_Qf 1;
BA_ "U_C490_MY18_Rx" SG_ 146 VehLongAActl_D_Qf 1;
BA_ "U_B562_MY18_Gas_Rx" SG_ 146 VehLongAActl_D_Qf 1;
BA_ "U_C519_MY18_5_Gas_Rx" SG_ 146 VehLongAActl_D_Qf 1;
BA_ "U_C519_MY18_5_Diesel_Rx" SG_ 146 VehLongAActl_D_Qf 1;
BA_ "U_B515_MCA_MY17_Gas_Rx" SG_ 146 VehLongAActl_D_Qf 1;
BA_ "U_B515_MCA_MY17_Diesel_Rx" SG_ 146 VehLongAActl_D_Qf 1;
BA_ "GenSigStartValue" SG_ 146 VehLongAActl_D_Qf 1;
BA_ "GenSigTimeoutTime_GWM" SG_ 146 VehLatAActl_D_Qf 30;
BA_ "U_CX482_CX483_MY20_Hev_Tx" SG_ 146 VehLatAActl_D_Qf 1;
BA_ "U_CX482_CX483_MY20_Gas_Tx" SG_ 146 VehLatAActl_D_Qf 1;
BA_ "U_CX482_CX483_MY20_Diesel_Tx" SG_ 146 VehLatAActl_D_Qf 1;
BA_ "U_B500_MY18_Diesel_Tx" SG_ 146 VehLatAActl_D_Qf 1;
BA_ "U_B500_MY18_Gas_Tx" SG_ 146 VehLatAActl_D_Qf 1;
BA_ "U_C490_MY18_Tx" SG_ 146 VehLatAActl_D_Qf 1;
BA_ "U_B562_MY18_Gas_Tx" SG_ 146 VehLatAActl_D_Qf 1;
BA_ "U_C519_MY18_5_Gas_Tx" SG_ 146 VehLatAActl_D_Qf 1;
BA_ "U_C519_MY18_5_Diesel_Tx" SG_ 146 VehLatAActl_D_Qf 1;
BA_ "U_B515_MCA_MY17_Gas_Tx" SG_ 146 VehLatAActl_D_Qf 1;
BA_ "U_B515_MCA_MY17_Diesel_Tx" SG_ 146 VehLatAActl_D_Qf 1;
BA_ "U_B479_MY17_Diesel_Tx" SG_ 146 VehLatAActl_D_Qf 1;
BA_ "U_B479_MY17_Gas_Tx" SG_ 146 VehLatAActl_D_Qf 1;
BA_ "U_U611_U625_MY20_Phev_Rx" SG_ 146 VehLatAActl_D_Qf 1;
BA_ "U_U611_U625_MY20_Hev_Rx" SG_ 146 VehLatAActl_D_Qf 1;
BA_ "U_U611_U625_MY20_Gas_Rx" SG_ 146 VehLatAActl_D_Qf 1;
BA_ "U_U611_U625_MY20_Diesel_Rx" SG_ 146 VehLatAActl_D_Qf 1;
BA_ "U_CX482_CX483_MY20_Hev_Rx" SG_ 146 VehLatAActl_D_Qf 1;
BA_ "U_CX482_CX483_MY20_Gas_Rx" SG_ 146 VehLatAActl_D_Qf 1;
BA_ "U_CX482_CX483_MY20_Diesel_Rx" SG_ 146 VehLatAActl_D_Qf 1;
BA_ "U_B500_MY18_Diesel_Rx" SG_ 146 VehLatAActl_D_Qf 1;
BA_ "U_B500_MY18_Gas_Rx" SG_ 146 VehLatAActl_D_Qf 1;
BA_ "U_C490_MY18_Rx" SG_ 146 VehLatAActl_D_Qf 1;
BA_ "U_B562_MY18_Gas_Rx" SG_ 146 VehLatAActl_D_Qf 1;
BA_ "U_B515_MCA_MY17_Gas_Rx" SG_ 146 VehLatAActl_D_Qf 1;
BA_ "U_B515_MCA_MY17_Diesel_Rx" SG_ 146 VehLatAActl_D_Qf 1;
BA_ "U_C519_MY18_5_Gas_Rx" SG_ 146 VehLatAActl_D_Qf 1;
BA_ "U_C519_MY18_5_Diesel_Rx" SG_ 146 VehLatAActl_D_Qf 1;
BA_ "U_B479_MY17_Diesel_Rx" SG_ 146 VehLatAActl_D_Qf 1;
BA_ "U_B479_MY17_Gas_Rx" SG_ 146 VehLatAActl_D_Qf 1;
BA_ "GenSigStartValue" SG_ 146 VehLatAActl_D_Qf 1;
BA_ "CrossOver_InfoCAN" SG_ 1152 TerrStat_D_RqDsply 1;
BA_ "CrossOver_InfoCAN" SG_ 1152 TerrMde_D_RqDrv 1;
BA_ "U_U611_U625_MY20_Hev_Rx" SG_ 1938 TesterPhysicalReqATCM 1;
BA_ "U_U611_U625_MY20_Gas_Rx" SG_ 1938 TesterPhysicalReqATCM 1;
BA_ "U_U611_U625_MY20_Diesel_Rx" SG_ 1938 TesterPhysicalReqATCM 1;
BA_ "GenSigSendType" SG_ 1938 TesterPhysicalReqATCM 3;
BA_ "U_CX482_CX483_MY20_Hev_Rx" SG_ 1888 TesterPhysicalReqABS 1;
BA_ "U_CX482_CX483_MY20_Gas_Rx" SG_ 1888 TesterPhysicalReqABS 1;
BA_ "U_CX482_CX483_MY20_Diesel_Rx" SG_ 1888 TesterPhysicalReqABS 1;
BA_ "U_U611_U625_MY20_Hev_Rx" SG_ 1888 TesterPhysicalReqABS 1;
BA_ "U_U611_U625_MY20_Gas_Rx" SG_ 1888 TesterPhysicalReqABS 1;
BA_ "U_U611_U625_MY20_Diesel_Rx" SG_ 1888 TesterPhysicalReqABS 1;
BA_ "U_B500_MY18_Diesel_Rx" SG_ 1888 TesterPhysicalReqABS 1;
BA_ "U_B500_MY18_Gas_Rx" SG_ 1888 TesterPhysicalReqABS 1;
BA_ "U_C490_MY18_Rx" SG_ 1888 TesterPhysicalReqABS 1;
BA_ "U_B562_MY18_Gas_Rx" SG_ 1888 TesterPhysicalReqABS 1;
BA_ "U_C519_MY18_5_Gas_Rx" SG_ 1888 TesterPhysicalReqABS 1;
BA_ "U_C519_MY18_5_Diesel_Rx" SG_ 1888 TesterPhysicalReqABS 1;
BA_ "U_B515_MCA_MY17_Gas_Rx" SG_ 1888 TesterPhysicalReqABS 1;
BA_ "U_B515_MCA_MY17_Diesel_Rx" SG_ 1888 TesterPhysicalReqABS 1;
BA_ "U_B479_MY17_Diesel_Rx" SG_ 1888 TesterPhysicalReqABS 1;
BA_ "U_B479_MY17_Gas_Rx" SG_ 1888 TesterPhysicalReqABS 1;
BA_ "GenSigSendType" SG_ 1888 TesterPhysicalReqABS 3;
BA_ "U_CX482_CX483_MY20_Hev_Tx" SG_ 984 AhbHiBeam_D_Rq 1;
BA_ "U_CX482_CX483_MY20_Gas_Tx" SG_ 984 AhbHiBeam_D_Rq 1;
BA_ "U_CX482_CX483_MY20_Diesel_Tx" SG_ 984 AhbHiBeam_D_Rq 1;
BA_ "U_U611_U625_MY20_Hev_Tx" SG_ 984 AhbHiBeam_D_Rq 1;
BA_ "U_U611_U625_MY20_Gas_Tx" SG_ 984 AhbHiBeam_D_Rq 1;
BA_ "U_U611_U625_MY20_Diesel_Tx" SG_ 984 AhbHiBeam_D_Rq 1;
BA_ "U_C519_MY18_5_Gas_Tx" SG_ 984 AhbHiBeam_D_Rq 1;
BA_ "U_C519_MY18_5_Diesel_Tx" SG_ 984 AhbHiBeam_D_Rq 1;
BA_ "U_B479_MY17_Diesel_Tx" SG_ 984 AhbHiBeam_D_Rq 1;
BA_ "U_B479_MY17_Gas_Tx" SG_ 984 AhbHiBeam_D_Rq 1;
BA_ "U_CX482_CX483_MY20_Hev_Rx" SG_ 984 AhbHiBeam_D_Rq 1;
BA_ "U_CX482_CX483_MY20_Gas_Rx" SG_ 984 AhbHiBeam_D_Rq 1;
BA_ "U_CX482_CX483_MY20_Diesel_Rx" SG_ 984 AhbHiBeam_D_Rq 1;
BA_ "U_U611_U625_MY20_Diesel_Rx" SG_ 984 AhbHiBeam_D_Rq 1;
BA_ "U_B500_MY18_Diesel_Rx" SG_ 984 AhbHiBeam_D_Rq 1;
BA_ "U_B500_MY18_Gas_Rx" SG_ 984 AhbHiBeam_D_Rq 1;
BA_ "U_C519_MY18_5_Gas_Rx" SG_ 984 AhbHiBeam_D_Rq 1;
BA_ "U_C519_MY18_5_Diesel_Rx" SG_ 984 AhbHiBeam_D_Rq 1;
BA_ "U_B479_MY17_Diesel_Rx" SG_ 984 AhbHiBeam_D_Rq 1;
BA_ "U_B479_MY17_Gas_Rx" SG_ 984 AhbHiBeam_D_Rq 1;
BA_ "GenSigSendType" SG_ 984 AhbHiBeam_D_Rq 3;
BA_ "U_C519_MY18_5_Gas_Rx" SG_ 984 CadsCamraStat_D_Qf 1;
BA_ "U_C519_MY18_5_Diesel_Rx" SG_ 984 CadsCamraStat_D_Qf 1;
BA_ "GenSigSendType" SG_ 984 CadsCamraStat_D_Qf 3;
BA_ "GenSigStartValue" SG_ 984 CadsCamraStat_D_Qf 1;
BA_ "U_CX482_CX483_MY20_Hev_Tx" SG_ 984 AhbcStat_B_Dsply 1;
BA_ "U_CX482_CX483_MY20_Gas_Tx" SG_ 984 AhbcStat_B_Dsply 1;
BA_ "U_CX482_CX483_MY20_Diesel_Tx" SG_ 984 AhbcStat_B_Dsply 1;
BA_ "U_U611_U625_MY20_Hev_Tx" SG_ 984 AhbcStat_B_Dsply 1;
BA_ "U_U611_U625_MY20_Gas_Tx" SG_ 984 AhbcStat_B_Dsply 1;
BA_ "U_U611_U625_MY20_Diesel_Tx" SG_ 984 AhbcStat_B_Dsply 1;
BA_ "U_C519_MY18_5_Gas_Tx" SG_ 984 AhbcStat_B_Dsply 1;
BA_ "U_C519_MY18_5_Diesel_Tx" SG_ 984 AhbcStat_B_Dsply 1;
BA_ "U_B479_MY17_Diesel_Tx" SG_ 984 AhbcStat_B_Dsply 1;
BA_ "U_B479_MY17_Gas_Tx" SG_ 984 AhbcStat_B_Dsply 1;
BA_ "GenSigSendType" SG_ 984 AhbcStat_B_Dsply 3;
BA_ "GenSigSendType" SG_ 984 LaSwtch_D_RqDrv 3;
BA_ "CrossOver_InfoCAN" SG_ 984 LaSwtch_D_RqDrv 1;
BA_ "U_CX482_CX483_MY20_Hev_Tx" SG_ 984 AhbcHiBeam_D_Rq 1;
BA_ "U_CX482_CX483_MY20_Gas_Tx" SG_ 984 AhbcHiBeam_D_Rq 1;
BA_ "U_CX482_CX483_MY20_Diesel_Tx" SG_ 984 AhbcHiBeam_D_Rq 1;
BA_ "U_U611_U625_MY20_Hev_Tx" SG_ 984 AhbcHiBeam_D_Rq 1;
BA_ "U_U611_U625_MY20_Gas_Tx" SG_ 984 AhbcHiBeam_D_Rq 1;
BA_ "U_U611_U625_MY20_Diesel_Tx" SG_ 984 AhbcHiBeam_D_Rq 1;
BA_ "U_C519_MY18_5_Gas_Tx" SG_ 984 AhbcHiBeam_D_Rq 1;
BA_ "U_C519_MY18_5_Diesel_Tx" SG_ 984 AhbcHiBeam_D_Rq 1;
BA_ "U_B479_MY17_Diesel_Tx" SG_ 984 AhbcHiBeam_D_Rq 1;
BA_ "U_B479_MY17_Gas_Tx" SG_ 984 AhbcHiBeam_D_Rq 1;
BA_ "GenSigSendType" SG_ 984 AhbcHiBeam_D_Rq 3;
BA_ "CrossOver_InfoCAN" SG_ 984 AhbcHiBeam_D_Rq 1;
BA_ "GenSigSendType" SG_ 984 LaSwtchStat_No_Actl 3;
BA_ "CrossOver_InfoCAN" SG_ 984 LaSwtchStat_No_Actl 1;
BA_ "U_CX482_CX483_MY20_Hev_Tx" SG_ 984 DasWarn_D_Dsply 1;
BA_ "U_CX482_CX483_MY20_Gas_Tx" SG_ 984 DasWarn_D_Dsply 1;
BA_ "U_CX482_CX483_MY20_Diesel_Tx" SG_ 984 DasWarn_D_Dsply 1;
BA_ "U_U611_U625_MY20_Hev_Tx" SG_ 984 DasWarn_D_Dsply 1;
BA_ "U_U611_U625_MY20_Gas_Tx" SG_ 984 DasWarn_D_Dsply 1;
BA_ "U_U611_U625_MY20_Diesel_Tx" SG_ 984 DasWarn_D_Dsply 1;
BA_ "U_C519_MY18_5_Gas_Tx" SG_ 984 DasWarn_D_Dsply 1;
BA_ "U_C519_MY18_5_Diesel_Tx" SG_ 984 DasWarn_D_Dsply 1;
BA_ "U_B479_MY17_Diesel_Tx" SG_ 984 DasWarn_D_Dsply 1;
BA_ "U_B479_MY17_Gas_Tx" SG_ 984 DasWarn_D_Dsply 1;
BA_ "U_C519_MY18_5_Gas_Rx" SG_ 984 DasWarn_D_Dsply 1;
BA_ "U_C519_MY18_5_Diesel_Rx" SG_ 984 DasWarn_D_Dsply 1;
BA_ "GenSigSendType" SG_ 984 DasWarn_D_Dsply 3;
BA_ "CrossOver_InfoCAN" SG_ 984 DasWarn_D_Dsply 1;
BA_ "U_CX482_CX483_MY20_Hev_Tx" SG_ 984 DasStats_D_Dsply 1;
BA_ "U_CX482_CX483_MY20_Gas_Tx" SG_ 984 DasStats_D_Dsply 1;
BA_ "U_CX482_CX483_MY20_Diesel_Tx" SG_ 984 DasStats_D_Dsply 1;
BA_ "U_U611_U625_MY20_Hev_Tx" SG_ 984 DasStats_D_Dsply 1;
BA_ "U_U611_U625_MY20_Gas_Tx" SG_ 984 DasStats_D_Dsply 1;
BA_ "U_U611_U625_MY20_Diesel_Tx" SG_ 984 DasStats_D_Dsply 1;
BA_ "U_C519_MY18_5_Gas_Tx" SG_ 984 DasStats_D_Dsply 1;
BA_ "U_C519_MY18_5_Diesel_Tx" SG_ 984 DasStats_D_Dsply 1;
BA_ "U_B479_MY17_Diesel_Tx" SG_ 984 DasStats_D_Dsply 1;
BA_ "U_B479_MY17_Gas_Tx" SG_ 984 DasStats_D_Dsply 1;
BA_ "GenSigSendType" SG_ 984 DasStats_D_Dsply 3;
BA_ "CrossOver_InfoCAN" SG_ 984 DasStats_D_Dsply 1;
BA_ "U_CX482_CX483_MY20_Hev_Tx" SG_ 984 DasAlrtLvl_D_Dsply 1;
BA_ "U_CX482_CX483_MY20_Gas_Tx" SG_ 984 DasAlrtLvl_D_Dsply 1;
BA_ "U_CX482_CX483_MY20_Diesel_Tx" SG_ 984 DasAlrtLvl_D_Dsply 1;
BA_ "U_U611_U625_MY20_Hev_Tx" SG_ 984 DasAlrtLvl_D_Dsply 1;
BA_ "U_U611_U625_MY20_Gas_Tx" SG_ 984 DasAlrtLvl_D_Dsply 1;
BA_ "U_U611_U625_MY20_Diesel_Tx" SG_ 984 DasAlrtLvl_D_Dsply 1;
BA_ "U_C519_MY18_5_Gas_Tx" SG_ 984 DasAlrtLvl_D_Dsply 1;
BA_ "U_C519_MY18_5_Diesel_Tx" SG_ 984 DasAlrtLvl_D_Dsply 1;
BA_ "U_B479_MY17_Diesel_Tx" SG_ 984 DasAlrtLvl_D_Dsply 1;
BA_ "U_B479_MY17_Gas_Tx" SG_ 984 DasAlrtLvl_D_Dsply 1;
BA_ "GenSigSendType" SG_ 984 DasAlrtLvl_D_Dsply 3;
BA_ "CrossOver_InfoCAN" SG_ 984 DasAlrtLvl_D_Dsply 1;
BA_ "U_CX482_CX483_MY20_Hev_Tx" SG_ 984 CamraStats_D_Dsply 1;
BA_ "U_CX482_CX483_MY20_Gas_Tx" SG_ 984 CamraStats_D_Dsply 1;
BA_ "U_CX482_CX483_MY20_Diesel_Tx" SG_ 984 CamraStats_D_Dsply 1;
BA_ "U_U611_U625_MY20_Hev_Tx" SG_ 984 CamraStats_D_Dsply 1;
BA_ "U_U611_U625_MY20_Gas_Tx" SG_ 984 CamraStats_D_Dsply 1;
BA_ "U_U611_U625_MY20_Diesel_Tx" SG_ 984 CamraStats_D_Dsply 1;
BA_ "U_C519_MY18_5_Gas_Tx" SG_ 984 CamraStats_D_Dsply 1;
BA_ "U_C519_MY18_5_Diesel_Tx" SG_ 984 CamraStats_D_Dsply 1;
BA_ "U_B479_MY17_Diesel_Tx" SG_ 984 CamraStats_D_Dsply 1;
BA_ "U_B479_MY17_Gas_Tx" SG_ 984 CamraStats_D_Dsply 1;
BA_ "U_C519_MY18_5_Gas_Rx" SG_ 984 CamraStats_D_Dsply 1;
BA_ "U_C519_MY18_5_Diesel_Rx" SG_ 984 CamraStats_D_Dsply 1;
BA_ "GenSigSendType" SG_ 984 CamraStats_D_Dsply 3;
BA_ "CrossOver_InfoCAN" SG_ 984 CamraStats_D_Dsply 1;
BA_ "U_CX482_CX483_MY20_Hev_Tx" SG_ 984 CamraDefog_B_Req 1;
BA_ "U_CX482_CX483_MY20_Gas_Tx" SG_ 984 CamraDefog_B_Req 1;
BA_ "U_CX482_CX483_MY20_Diesel_Tx" SG_ 984 CamraDefog_B_Req 1;
BA_ "U_U611_U625_MY20_Hev_Tx" SG_ 984 CamraDefog_B_Req 1;
BA_ "U_U611_U625_MY20_Gas_Tx" SG_ 984 CamraDefog_B_Req 1;
BA_ "U_U611_U625_MY20_Diesel_Tx" SG_ 984 CamraDefog_B_Req 1;
BA_ "U_C519_MY18_5_Gas_Tx" SG_ 984 CamraDefog_B_Req 1;
BA_ "U_C519_MY18_5_Diesel_Tx" SG_ 984 CamraDefog_B_Req 1;
BA_ "U_B479_MY17_Diesel_Tx" SG_ 984 CamraDefog_B_Req 1;
BA_ "U_B479_MY17_Gas_Tx" SG_ 984 CamraDefog_B_Req 1;
BA_ "GenSigSendType" SG_ 984 CamraDefog_B_Req 3;
BA_ "CrossOver_InfoCAN" SG_ 984 CamraDefog_B_Req 1;
BA_ "U_CX482_CX483_MY20_Hev_Tx" SG_ 984 LaHandsOff_D_Dsply 1;
BA_ "U_CX482_CX483_MY20_Gas_Tx" SG_ 984 LaHandsOff_D_Dsply 1;
BA_ "U_CX482_CX483_MY20_Diesel_Tx" SG_ 984 LaHandsOff_D_Dsply 1;
BA_ "U_U611_U625_MY20_Hev_Tx" SG_ 984 LaHandsOff_D_Dsply 1;
BA_ "U_U611_U625_MY20_Gas_Tx" SG_ 984 LaHandsOff_D_Dsply 1;
BA_ "U_U611_U625_MY20_Diesel_Tx" SG_ 984 LaHandsOff_D_Dsply 1;
BA_ "U_C519_MY18_5_Gas_Tx" SG_ 984 LaHandsOff_D_Dsply 1;
BA_ "U_C519_MY18_5_Diesel_Tx" SG_ 984 LaHandsOff_D_Dsply 1;
BA_ "U_B479_MY17_Diesel_Tx" SG_ 984 LaHandsOff_D_Dsply 1;
BA_ "U_B479_MY17_Gas_Tx" SG_ 984 LaHandsOff_D_Dsply 1;
BA_ "GenSigSendType" SG_ 984 LaHandsOff_D_Dsply 3;
BA_ "CrossOver_InfoCAN" SG_ 984 LaHandsOff_D_Dsply 1;
BA_ "U_CX482_CX483_MY20_Hev_Tx" SG_ 984 LaDenyStats_B_Dsply 1;
BA_ "U_CX482_CX483_MY20_Gas_Tx" SG_ 984 LaDenyStats_B_Dsply 1;
BA_ "U_CX482_CX483_MY20_Diesel_Tx" SG_ 984 LaDenyStats_B_Dsply 1;
BA_ "U_U611_U625_MY20_Hev_Tx" SG_ 984 LaDenyStats_B_Dsply 1;
BA_ "U_U611_U625_MY20_Gas_Tx" SG_ 984 LaDenyStats_B_Dsply 1;
BA_ "U_U611_U625_MY20_Diesel_Tx" SG_ 984 LaDenyStats_B_Dsply 1;
BA_ "U_C519_MY18_5_Gas_Tx" SG_ 984 LaDenyStats_B_Dsply 1;
BA_ "U_C519_MY18_5_Diesel_Tx" SG_ 984 LaDenyStats_B_Dsply 1;
BA_ "U_B479_MY17_Diesel_Tx" SG_ 984 LaDenyStats_B_Dsply 1;
BA_ "U_B479_MY17_Gas_Tx" SG_ 984 LaDenyStats_B_Dsply 1;
BA_ "GenSigSendType" SG_ 984 LaDenyStats_B_Dsply 3;
BA_ "CrossOver_InfoCAN" SG_ 984 LaDenyStats_B_Dsply 1;
BA_ "U_CX482_CX483_MY20_Hev_Tx" SG_ 984 LaActvStats_D_Dsply 1;
BA_ "U_CX482_CX483_MY20_Gas_Tx" SG_ 984 LaActvStats_D_Dsply 1;
BA_ "U_CX482_CX483_MY20_Diesel_Tx" SG_ 984 LaActvStats_D_Dsply 1;
BA_ "U_U611_U625_MY20_Hev_Tx" SG_ 984 LaActvStats_D_Dsply 1;
BA_ "U_U611_U625_MY20_Gas_Tx" SG_ 984 LaActvStats_D_Dsply 1;
BA_ "U_U611_U625_MY20_Diesel_Tx" SG_ 984 LaActvStats_D_Dsply 1;
BA_ "U_C519_MY18_5_Gas_Tx" SG_ 984 LaActvStats_D_Dsply 1;
BA_ "U_C519_MY18_5_Diesel_Tx" SG_ 984 LaActvStats_D_Dsply 1;
BA_ "U_B479_MY17_Diesel_Tx" SG_ 984 LaActvStats_D_Dsply 1;
BA_ "U_B479_MY17_Gas_Tx" SG_ 984 LaActvStats_D_Dsply 1;
BA_ "GenSigSendType" SG_ 984 LaActvStats_D_Dsply 3;
BA_ "CrossOver_InfoCAN" SG_ 984 LaActvStats_D_Dsply 1;
BA_ "U_CX482_CX483_MY20_Hev_Tx" SG_ 984 AhbcRampingV_D_Rq 1;
BA_ "U_CX482_CX483_MY20_Gas_Tx" SG_ 984 AhbcRampingV_D_Rq 1;
BA_ "U_CX482_CX483_MY20_Diesel_Tx" SG_ 984 AhbcRampingV_D_Rq 1;
BA_ "U_U611_U625_MY20_Hev_Tx" SG_ 984 AhbcRampingV_D_Rq 1;
BA_ "U_U611_U625_MY20_Gas_Tx" SG_ 984 AhbcRampingV_D_Rq 1;
BA_ "U_U611_U625_MY20_Diesel_Tx" SG_ 984 AhbcRampingV_D_Rq 1;
BA_ "U_C519_MY18_5_Gas_Tx" SG_ 984 AhbcRampingV_D_Rq 1;
BA_ "U_C519_MY18_5_Diesel_Tx" SG_ 984 AhbcRampingV_D_Rq 1;
BA_ "U_B479_MY17_Diesel_Tx" SG_ 984 AhbcRampingV_D_Rq 1;
BA_ "U_B479_MY17_Gas_Tx" SG_ 984 AhbcRampingV_D_Rq 1;
BA_ "U_CX482_CX483_MY20_Hev_Rx" SG_ 984 AhbcRampingV_D_Rq 1;
BA_ "U_CX482_CX483_MY20_Gas_Rx" SG_ 984 AhbcRampingV_D_Rq 1;
BA_ "U_CX482_CX483_MY20_Diesel_Rx" SG_ 984 AhbcRampingV_D_Rq 1;
BA_ "U_U611_U625_MY20_Hev_Rx" SG_ 984 AhbcRampingV_D_Rq 1;
BA_ "U_U611_U625_MY20_Gas_Rx" SG_ 984 AhbcRampingV_D_Rq 1;
BA_ "U_U611_U625_MY20_Diesel_Rx" SG_ 984 AhbcRampingV_D_Rq 1;
BA_ "U_C519_MY18_5_Gas_Rx" SG_ 984 AhbcRampingV_D_Rq 1;
BA_ "U_C519_MY18_5_Diesel_Rx" SG_ 984 AhbcRampingV_D_Rq 1;
BA_ "GenSigSendType" SG_ 984 AhbcRampingV_D_Rq 3;
BA_ "U_CX482_CX483_MY20_Hev_Tx" SG_ 984 PersIndexIpma_D_Actl 1;
BA_ "U_CX482_CX483_MY20_Gas_Tx" SG_ 984 PersIndexIpma_D_Actl 1;
BA_ "U_CX482_CX483_MY20_Diesel_Tx" SG_ 984 PersIndexIpma_D_Actl 1;
BA_ "U_U611_U625_MY20_Hev_Tx" SG_ 984 PersIndexIpma_D_Actl 1;
BA_ "U_U611_U625_MY20_Gas_Tx" SG_ 984 PersIndexIpma_D_Actl 1;
BA_ "U_U611_U625_MY20_Diesel_Tx" SG_ 984 PersIndexIpma_D_Actl 1;
BA_ "U_C519_MY18_5_Gas_Tx" SG_ 984 PersIndexIpma_D_Actl 1;
BA_ "U_C519_MY18_5_Diesel_Tx" SG_ 984 PersIndexIpma_D_Actl 1;
BA_ "U_B479_MY17_Diesel_Tx" SG_ 984 PersIndexIpma_D_Actl 1;
BA_ "U_B479_MY17_Gas_Tx" SG_ 984 PersIndexIpma_D_Actl 1;
BA_ "GenSigSendType" SG_ 984 PersIndexIpma_D_Actl 3;
BA_ "GenSigStartValue" SG_ 984 PersIndexIpma_D_Actl 4;
BA_ "CrossOver_InfoCAN" SG_ 984 PersIndexIpma_D_Actl 1;
BA_ "U_CX482_CX483_MY20_Hev_Tx" SG_ 984 FeatNoIpmaActl 1;
BA_ "U_CX482_CX483_MY20_Gas_Tx" SG_ 984 FeatNoIpmaActl 1;
BA_ "U_CX482_CX483_MY20_Diesel_Tx" SG_ 984 FeatNoIpmaActl 1;
BA_ "U_U611_U625_MY20_Hev_Tx" SG_ 984 FeatNoIpmaActl 1;
BA_ "U_U611_U625_MY20_Gas_Tx" SG_ 984 FeatNoIpmaActl 1;
BA_ "U_U611_U625_MY20_Diesel_Tx" SG_ 984 FeatNoIpmaActl 1;
BA_ "U_C519_MY18_5_Gas_Tx" SG_ 984 FeatNoIpmaActl 1;
BA_ "U_C519_MY18_5_Diesel_Tx" SG_ 984 FeatNoIpmaActl 1;
BA_ "U_B479_MY17_Diesel_Tx" SG_ 984 FeatNoIpmaActl 1;
BA_ "U_B479_MY17_Gas_Tx" SG_ 984 FeatNoIpmaActl 1;
BA_ "GenSigSendType" SG_ 984 FeatNoIpmaActl 3;
BA_ "CrossOver_InfoCAN" SG_ 984 FeatNoIpmaActl 1;
BA_ "U_CX482_CX483_MY20_Hev_Tx" SG_ 984 FeatConfigIpmaActl 1;
BA_ "U_CX482_CX483_MY20_Gas_Tx" SG_ 984 FeatConfigIpmaActl 1;
BA_ "U_CX482_CX483_MY20_Diesel_Tx" SG_ 984 FeatConfigIpmaActl 1;
BA_ "U_U611_U625_MY20_Hev_Tx" SG_ 984 FeatConfigIpmaActl 1;
BA_ "U_U611_U625_MY20_Gas_Tx" SG_ 984 FeatConfigIpmaActl 1;
BA_ "U_U611_U625_MY20_Diesel_Tx" SG_ 984 FeatConfigIpmaActl 1;
BA_ "U_C519_MY18_5_Gas_Tx" SG_ 984 FeatConfigIpmaActl 1;
BA_ "U_C519_MY18_5_Diesel_Tx" SG_ 984 FeatConfigIpmaActl 1;
BA_ "U_B479_MY17_Diesel_Tx" SG_ 984 FeatConfigIpmaActl 1;
BA_ "U_B479_MY17_Gas_Tx" SG_ 984 FeatConfigIpmaActl 1;
BA_ "GenSigSendType" SG_ 984 FeatConfigIpmaActl 3;
BA_ "CrossOver_InfoCAN" SG_ 984 FeatConfigIpmaActl 1;
BA_ "U_U611_U625_MY20_Phev_Tx" SG_ 998 PersIndexSccm_D_Actl 1;
BA_ "U_CX482_CX483_MY20_Hev_Tx" SG_ 998 PersIndexSccm_D_Actl 1;
BA_ "U_CX482_CX483_MY20_Gas_Tx" SG_ 998 PersIndexSccm_D_Actl 1;
BA_ "U_CX482_CX483_MY20_Diesel_Tx" SG_ 998 PersIndexSccm_D_Actl 1;
BA_ "U_U611_U625_MY20_Hev_Tx" SG_ 998 PersIndexSccm_D_Actl 1;
BA_ "U_U611_U625_MY20_Gas_Tx" SG_ 998 PersIndexSccm_D_Actl 1;
BA_ "U_U611_U625_MY20_Diesel_Tx" SG_ 998 PersIndexSccm_D_Actl 1;
BA_ "U_B500_MY18_Diesel_Tx" SG_ 998 PersIndexSccm_D_Actl 1;
BA_ "U_B500_MY18_Gas_Tx" SG_ 998 PersIndexSccm_D_Actl 1;
BA_ "U_C519_MY18_5_Gas_Tx" SG_ 998 PersIndexSccm_D_Actl 1;
BA_ "U_C519_MY18_5_Diesel_Tx" SG_ 998 PersIndexSccm_D_Actl 1;
BA_ "U_B515_MCA_MY17_Gas_Tx" SG_ 998 PersIndexSccm_D_Actl 1;
BA_ "U_B515_MCA_MY17_Diesel_Tx" SG_ 998 PersIndexSccm_D_Actl 1;
BA_ "U_B479_MY17_Diesel_Tx" SG_ 998 PersIndexSccm_D_Actl 1;
BA_ "U_B479_MY17_Gas_Tx" SG_ 998 PersIndexSccm_D_Actl 1;
BA_ "GenSigSendType" SG_ 998 PersIndexSccm_D_Actl 3;
BA_ "GenSigStartValue" SG_ 998 PersIndexSccm_D_Actl 4;
BA_ "CrossOver_InfoCAN" SG_ 998 PersIndexSccm_D_Actl 1;
BA_ "U_U611_U625_MY20_Phev_Tx" SG_ 998 FeatNoSccmActl 1;
BA_ "U_CX482_CX483_MY20_Hev_Tx" SG_ 998 FeatNoSccmActl 1;
BA_ "U_CX482_CX483_MY20_Gas_Tx" SG_ 998 FeatNoSccmActl 1;
BA_ "U_CX482_CX483_MY20_Diesel_Tx" SG_ 998 FeatNoSccmActl 1;
BA_ "U_U611_U625_MY20_Hev_Tx" SG_ 998 FeatNoSccmActl 1;
BA_ "U_U611_U625_MY20_Gas_Tx" SG_ 998 FeatNoSccmActl 1;
BA_ "U_U611_U625_MY20_Diesel_Tx" SG_ 998 FeatNoSccmActl 1;
BA_ "U_B500_MY18_Diesel_Tx" SG_ 998 FeatNoSccmActl 1;
BA_ "U_B500_MY18_Gas_Tx" SG_ 998 FeatNoSccmActl 1;
BA_ "U_C519_MY18_5_Gas_Tx" SG_ 998 FeatNoSccmActl 1;
BA_ "U_C519_MY18_5_Diesel_Tx" SG_ 998 FeatNoSccmActl 1;
BA_ "U_B515_MCA_MY17_Gas_Tx" SG_ 998 FeatNoSccmActl 1;
BA_ "U_B515_MCA_MY17_Diesel_Tx" SG_ 998 FeatNoSccmActl 1;
BA_ "U_B479_MY17_Diesel_Tx" SG_ 998 FeatNoSccmActl 1;
BA_ "U_B479_MY17_Gas_Tx" SG_ 998 FeatNoSccmActl 1;
BA_ "GenSigSendType" SG_ 998 FeatNoSccmActl 3;
BA_ "CrossOver_InfoCAN" SG_ 998 FeatNoSccmActl 1;
BA_ "U_U611_U625_MY20_Phev_Tx" SG_ 998 FeatConfigSccmActl 1;
BA_ "U_CX482_CX483_MY20_Hev_Tx" SG_ 998 FeatConfigSccmActl 1;
BA_ "U_CX482_CX483_MY20_Gas_Tx" SG_ 998 FeatConfigSccmActl 1;
BA_ "U_CX482_CX483_MY20_Diesel_Tx" SG_ 998 FeatConfigSccmActl 1;
BA_ "U_U611_U625_MY20_Hev_Tx" SG_ 998 FeatConfigSccmActl 1;
BA_ "U_U611_U625_MY20_Gas_Tx" SG_ 998 FeatConfigSccmActl 1;
BA_ "U_U611_U625_MY20_Diesel_Tx" SG_ 998 FeatConfigSccmActl 1;
BA_ "U_B500_MY18_Diesel_Tx" SG_ 998 FeatConfigSccmActl 1;
BA_ "U_B500_MY18_Gas_Tx" SG_ 998 FeatConfigSccmActl 1;
BA_ "U_C519_MY18_5_Gas_Tx" SG_ 998 FeatConfigSccmActl 1;
BA_ "U_C519_MY18_5_Diesel_Tx" SG_ 998 FeatConfigSccmActl 1;
BA_ "U_B515_MCA_MY17_Gas_Tx" SG_ 998 FeatConfigSccmActl 1;
BA_ "U_B515_MCA_MY17_Diesel_Tx" SG_ 998 FeatConfigSccmActl 1;
BA_ "U_B479_MY17_Diesel_Tx" SG_ 998 FeatConfigSccmActl 1;
BA_ "U_B479_MY17_Gas_Tx" SG_ 998 FeatConfigSccmActl 1;
BA_ "GenSigSendType" SG_ 998 FeatConfigSccmActl 3;
BA_ "CrossOver_InfoCAN" SG_ 998 FeatConfigSccmActl 1;
BA_ "U_CX482_CX483_MY20_Hev_Tx" SG_ 997 PersIndexCcm_D_Actl 1;
BA_ "U_CX482_CX483_MY20_Gas_Tx" SG_ 997 PersIndexCcm_D_Actl 1;
BA_ "U_CX482_CX483_MY20_Diesel_Tx" SG_ 997 PersIndexCcm_D_Actl 1;
BA_ "U_U611_U625_MY20_Hev_Tx" SG_ 997 PersIndexCcm_D_Actl 1;
BA_ "U_U611_U625_MY20_Gas_Tx" SG_ 997 PersIndexCcm_D_Actl 1;
BA_ "U_U611_U625_MY20_Diesel_Tx" SG_ 997 PersIndexCcm_D_Actl 1;
BA_ "U_C519_MY18_5_Gas_Tx" SG_ 997 PersIndexCcm_D_Actl 1;
BA_ "U_C519_MY18_5_Diesel_Tx" SG_ 997 PersIndexCcm_D_Actl 1;
BA_ "U_B479_MY17_Diesel_Tx" SG_ 997 PersIndexCcm_D_Actl 1;
BA_ "U_B479_MY17_Gas_Tx" SG_ 997 PersIndexCcm_D_Actl 1;
BA_ "GenSigSendType" SG_ 997 PersIndexCcm_D_Actl 3;
BA_ "GenSigStartValue" SG_ 997 PersIndexCcm_D_Actl 4;
BA_ "CrossOver_InfoCAN" SG_ 997 PersIndexCcm_D_Actl 1;
BA_ "U_CX482_CX483_MY20_Hev_Tx" SG_ 997 FeatNoCcmActl 1;
BA_ "U_CX482_CX483_MY20_Gas_Tx" SG_ 997 FeatNoCcmActl 1;
BA_ "U_CX482_CX483_MY20_Diesel_Tx" SG_ 997 FeatNoCcmActl 1;
BA_ "U_U611_U625_MY20_Hev_Tx" SG_ 997 FeatNoCcmActl 1;
BA_ "U_U611_U625_MY20_Gas_Tx" SG_ 997 FeatNoCcmActl 1;
BA_ "U_U611_U625_MY20_Diesel_Tx" SG_ 997 FeatNoCcmActl 1;
BA_ "U_C519_MY18_5_Gas_Tx" SG_ 997 FeatNoCcmActl 1;
BA_ "U_C519_MY18_5_Diesel_Tx" SG_ 997 FeatNoCcmActl 1;
BA_ "U_B479_MY17_Diesel_Tx" SG_ 997 FeatNoCcmActl 1;
BA_ "U_B479_MY17_Gas_Tx" SG_ 997 FeatNoCcmActl 1;
BA_ "GenSigSendType" SG_ 997 FeatNoCcmActl 3;
BA_ "CrossOver_InfoCAN" SG_ 997 FeatNoCcmActl 1;
BA_ "U_CX482_CX483_MY20_Hev_Tx" SG_ 997 FeatConfigCcmActl 1;
BA_ "U_CX482_CX483_MY20_Gas_Tx" SG_ 997 FeatConfigCcmActl 1;
BA_ "U_CX482_CX483_MY20_Diesel_Tx" SG_ 997 FeatConfigCcmActl 1;
BA_ "U_U611_U625_MY20_Hev_Tx" SG_ 997 FeatConfigCcmActl 1;
BA_ "U_U611_U625_MY20_Gas_Tx" SG_ 997 FeatConfigCcmActl 1;
BA_ "U_U611_U625_MY20_Diesel_Tx" SG_ 997 FeatConfigCcmActl 1;
BA_ "U_C519_MY18_5_Gas_Tx" SG_ 997 FeatConfigCcmActl 1;
BA_ "U_C519_MY18_5_Diesel_Tx" SG_ 997 FeatConfigCcmActl 1;
BA_ "U_B479_MY17_Diesel_Tx" SG_ 997 FeatConfigCcmActl 1;
BA_ "U_B479_MY17_Gas_Tx" SG_ 997 FeatConfigCcmActl 1;
BA_ "GenSigSendType" SG_ 997 FeatConfigCcmActl 3;
BA_ "CrossOver_InfoCAN" SG_ 997 FeatConfigCcmActl 1;
BA_ "U_U611_U625_MY20_Phev_Tx" SG_ 613 BeltWarnThres_D_Stat 1;
BA_ "U_CX482_CX483_MY20_Hev_Tx" SG_ 613 BeltWarnThres_D_Stat 1;
BA_ "U_CX482_CX483_MY20_Gas_Tx" SG_ 613 BeltWarnThres_D_Stat 1;
BA_ "U_CX482_CX483_MY20_Diesel_Tx" SG_ 613 BeltWarnThres_D_Stat 1;
BA_ "U_U611_U625_MY20_Hev_Tx" SG_ 613 BeltWarnThres_D_Stat 1;
BA_ "U_U611_U625_MY20_Gas_Tx" SG_ 613 BeltWarnThres_D_Stat 1;
BA_ "U_U611_U625_MY20_Diesel_Tx" SG_ 613 BeltWarnThres_D_Stat 1;
BA_ "U_C519_MY18_5_Gas_Tx" SG_ 613 BeltWarnThres_D_Stat 1;
BA_ "U_C519_MY18_5_Diesel_Tx" SG_ 613 BeltWarnThres_D_Stat 1;
BA_ "U_B515_MCA_MY17_Gas_Tx" SG_ 613 BeltWarnThres_D_Stat 1;
BA_ "U_B515_MCA_MY17_Diesel_Tx" SG_ 613 BeltWarnThres_D_Stat 1;
BA_ "U_B479_MY17_Diesel_Tx" SG_ 613 BeltWarnThres_D_Stat 1;
BA_ "U_B479_MY17_Gas_Tx" SG_ 613 BeltWarnThres_D_Stat 1;
BA_ "U_CX482_CX483_MY20_Hev_Rx" SG_ 613 BeltWarnThres_D_Stat 1;
BA_ "U_CX482_CX483_MY20_Gas_Rx" SG_ 613 BeltWarnThres_D_Stat 1;
BA_ "U_CX482_CX483_MY20_Diesel_Rx" SG_ 613 BeltWarnThres_D_Stat 1;
BA_ "U_U611_U625_MY20_Hev_Rx" SG_ 613 BeltWarnThres_D_Stat 1;
BA_ "U_U611_U625_MY20_Gas_Rx" SG_ 613 BeltWarnThres_D_Stat 1;
BA_ "U_U611_U625_MY20_Diesel_Rx" SG_ 613 BeltWarnThres_D_Stat 1;
BA_ "U_C519_MY18_5_Gas_Rx" SG_ 613 BeltWarnThres_D_Stat 1;
BA_ "U_C519_MY18_5_Diesel_Rx" SG_ 613 BeltWarnThres_D_Stat 1;
BA_ "U_B515_MCA_MY17_Gas_Rx" SG_ 613 BeltWarnThres_D_Stat 1;
BA_ "U_B515_MCA_MY17_Diesel_Rx" SG_ 613 BeltWarnThres_D_Stat 1;
BA_ "U_B479_MY17_Diesel_Rx" SG_ 613 BeltWarnThres_D_Stat 1;
BA_ "U_B479_MY17_Gas_Rx" SG_ 613 BeltWarnThres_D_Stat 1;
BA_ "GenSigSendType" SG_ 613 BeltWarnThres_D_Stat 3;
BA_ "GenSigStartValue" SG_ 613 BeltWarnThres_D_Stat 6;
BA_ "U_U611_U625_MY20_Phev_Tx" SG_ 613 VehicleMYCalibrationId 1;
BA_ "U_CX482_CX483_MY20_Hev_Tx" SG_ 613 VehicleMYCalibrationId 1;
BA_ "U_CX482_CX483_MY20_Gas_Tx" SG_ 613 VehicleMYCalibrationId 1;
BA_ "U_CX482_CX483_MY20_Diesel_Tx" SG_ 613 VehicleMYCalibrationId 1;
BA_ "U_U611_U625_MY20_Hev_Tx" SG_ 613 VehicleMYCalibrationId 1;
BA_ "U_U611_U625_MY20_Gas_Tx" SG_ 613 VehicleMYCalibrationId 1;
BA_ "U_U611_U625_MY20_Diesel_Tx" SG_ 613 VehicleMYCalibrationId 1;
BA_ "U_C519_MY18_5_Gas_Tx" SG_ 613 VehicleMYCalibrationId 1;
BA_ "U_C519_MY18_5_Diesel_Tx" SG_ 613 VehicleMYCalibrationId 1;
BA_ "U_B515_MCA_MY17_Gas_Tx" SG_ 613 VehicleMYCalibrationId 1;
BA_ "U_B515_MCA_MY17_Diesel_Tx" SG_ 613 VehicleMYCalibrationId 1;
BA_ "U_B479_MY17_Diesel_Tx" SG_ 613 VehicleMYCalibrationId 1;
BA_ "U_B479_MY17_Gas_Tx" SG_ 613 VehicleMYCalibrationId 1;
BA_ "U_CX482_CX483_MY20_Hev_Rx" SG_ 613 VehicleMYCalibrationId 1;
BA_ "U_CX482_CX483_MY20_Gas_Rx" SG_ 613 VehicleMYCalibrationId 1;
BA_ "U_CX482_CX483_MY20_Diesel_Rx" SG_ 613 VehicleMYCalibrationId 1;
BA_ "U_U611_U625_MY20_Hev_Rx" SG_ 613 VehicleMYCalibrationId 1;
BA_ "U_U611_U625_MY20_Gas_Rx" SG_ 613 VehicleMYCalibrationId 1;
BA_ "U_U611_U625_MY20_Diesel_Rx" SG_ 613 VehicleMYCalibrationId 1;
BA_ "U_C519_MY18_5_Gas_Rx" SG_ 613 VehicleMYCalibrationId 1;
BA_ "U_C519_MY18_5_Diesel_Rx" SG_ 613 VehicleMYCalibrationId 1;
BA_ "U_B515_MCA_MY17_Gas_Rx" SG_ 613 VehicleMYCalibrationId 1;
BA_ "U_B515_MCA_MY17_Diesel_Rx" SG_ 613 VehicleMYCalibrationId 1;
BA_ "U_B479_MY17_Diesel_Rx" SG_ 613 VehicleMYCalibrationId 1;
BA_ "U_B479_MY17_Gas_Rx" SG_ 613 VehicleMYCalibrationId 1;
BA_ "U_U611_U625_MY20_Phev_Tx" SG_ 613 VehicleCalibrationId 1;
BA_ "U_CX482_CX483_MY20_Hev_Tx" SG_ 613 VehicleCalibrationId 1;
BA_ "U_CX482_CX483_MY20_Gas_Tx" SG_ 613 VehicleCalibrationId 1;
BA_ "U_CX482_CX483_MY20_Diesel_Tx" SG_ 613 VehicleCalibrationId 1;
BA_ "U_U611_U625_MY20_Hev_Tx" SG_ 613 VehicleCalibrationId 1;
BA_ "U_U611_U625_MY20_Gas_Tx" SG_ 613 VehicleCalibrationId 1;
BA_ "U_U611_U625_MY20_Diesel_Tx" SG_ 613 VehicleCalibrationId 1;
BA_ "U_C519_MY18_5_Gas_Tx" SG_ 613 VehicleCalibrationId 1;
BA_ "U_C519_MY18_5_Diesel_Tx" SG_ 613 VehicleCalibrationId 1;
BA_ "U_B515_MCA_MY17_Gas_Tx" SG_ 613 VehicleCalibrationId 1;
BA_ "U_B515_MCA_MY17_Diesel_Tx" SG_ 613 VehicleCalibrationId 1;
BA_ "U_B479_MY17_Diesel_Tx" SG_ 613 VehicleCalibrationId 1;
BA_ "U_B479_MY17_Gas_Tx" SG_ 613 VehicleCalibrationId 1;
BA_ "U_CX482_CX483_MY20_Hev_Rx" SG_ 613 VehicleCalibrationId 1;
BA_ "U_CX482_CX483_MY20_Gas_Rx" SG_ 613 VehicleCalibrationId 1;
BA_ "U_CX482_CX483_MY20_Diesel_Rx" SG_ 613 VehicleCalibrationId 1;
BA_ "U_U611_U625_MY20_Hev_Rx" SG_ 613 VehicleCalibrationId 1;
BA_ "U_U611_U625_MY20_Gas_Rx" SG_ 613 VehicleCalibrationId 1;
BA_ "U_U611_U625_MY20_Diesel_Rx" SG_ 613 VehicleCalibrationId 1;
BA_ "U_C519_MY18_5_Gas_Rx" SG_ 613 VehicleCalibrationId 1;
BA_ "U_C519_MY18_5_Diesel_Rx" SG_ 613 VehicleCalibrationId 1;
BA_ "U_B515_MCA_MY17_Gas_Rx" SG_ 613 VehicleCalibrationId 1;
BA_ "U_B515_MCA_MY17_Diesel_Rx" SG_ 613 VehicleCalibrationId 1;
BA_ "U_B479_MY17_Diesel_Rx" SG_ 613 VehicleCalibrationId 1;
BA_ "U_B479_MY17_Gas_Rx" SG_ 613 VehicleCalibrationId 1;
BA_ "U_U611_U625_MY20_Phev_Tx" SG_ 613 OCSSensrDataUpperLim 1;
BA_ "U_CX482_CX483_MY20_Hev_Tx" SG_ 613 OCSSensrDataUpperLim 1;
BA_ "U_CX482_CX483_MY20_Gas_Tx" SG_ 613 OCSSensrDataUpperLim 1;
BA_ "U_CX482_CX483_MY20_Diesel_Tx" SG_ 613 OCSSensrDataUpperLim 1;
BA_ "U_U611_U625_MY20_Hev_Tx" SG_ 613 OCSSensrDataUpperLim 1;
BA_ "U_U611_U625_MY20_Gas_Tx" SG_ 613 OCSSensrDataUpperLim 1;
BA_ "U_U611_U625_MY20_Diesel_Tx" SG_ 613 OCSSensrDataUpperLim 1;
BA_ "U_C519_MY18_5_Gas_Tx" SG_ 613 OCSSensrDataUpperLim 1;
BA_ "U_C519_MY18_5_Diesel_Tx" SG_ 613 OCSSensrDataUpperLim 1;
BA_ "U_B515_MCA_MY17_Gas_Tx" SG_ 613 OCSSensrDataUpperLim 1;
BA_ "U_B515_MCA_MY17_Diesel_Tx" SG_ 613 OCSSensrDataUpperLim 1;
BA_ "U_B479_MY17_Diesel_Tx" SG_ 613 OCSSensrDataUpperLim 1;
BA_ "U_B479_MY17_Gas_Tx" SG_ 613 OCSSensrDataUpperLim 1;
BA_ "U_CX482_CX483_MY20_Hev_Rx" SG_ 613 OCSSensrDataUpperLim 1;
BA_ "U_CX482_CX483_MY20_Gas_Rx" SG_ 613 OCSSensrDataUpperLim 1;
BA_ "U_CX482_CX483_MY20_Diesel_Rx" SG_ 613 OCSSensrDataUpperLim 1;
BA_ "U_U611_U625_MY20_Hev_Rx" SG_ 613 OCSSensrDataUpperLim 1;
BA_ "U_U611_U625_MY20_Gas_Rx" SG_ 613 OCSSensrDataUpperLim 1;
BA_ "U_U611_U625_MY20_Diesel_Rx" SG_ 613 OCSSensrDataUpperLim 1;
BA_ "U_C519_MY18_5_Gas_Rx" SG_ 613 OCSSensrDataUpperLim 1;
BA_ "U_C519_MY18_5_Diesel_Rx" SG_ 613 OCSSensrDataUpperLim 1;
BA_ "U_B515_MCA_MY17_Gas_Rx" SG_ 613 OCSSensrDataUpperLim 1;
BA_ "U_B515_MCA_MY17_Diesel_Rx" SG_ 613 OCSSensrDataUpperLim 1;
BA_ "U_B479_MY17_Diesel_Rx" SG_ 613 OCSSensrDataUpperLim 1;
BA_ "U_B479_MY17_Gas_Rx" SG_ 613 OCSSensrDataUpperLim 1;
BA_ "GenSigSendType" SG_ 613 OCSSensrDataUpperLim 3;
BA_ "U_U611_U625_MY20_Phev_Tx" SG_ 613 OCSSensrDataLowerLim 1;
BA_ "U_CX482_CX483_MY20_Hev_Tx" SG_ 613 OCSSensrDataLowerLim 1;
BA_ "U_CX482_CX483_MY20_Gas_Tx" SG_ 613 OCSSensrDataLowerLim 1;
BA_ "U_CX482_CX483_MY20_Diesel_Tx" SG_ 613 OCSSensrDataLowerLim 1;
BA_ "U_U611_U625_MY20_Hev_Tx" SG_ 613 OCSSensrDataLowerLim 1;
BA_ "U_U611_U625_MY20_Gas_Tx" SG_ 613 OCSSensrDataLowerLim 1;
BA_ "U_U611_U625_MY20_Diesel_Tx" SG_ 613 OCSSensrDataLowerLim 1;
BA_ "U_C519_MY18_5_Gas_Tx" SG_ 613 OCSSensrDataLowerLim 1;
BA_ "U_C519_MY18_5_Diesel_Tx" SG_ 613 OCSSensrDataLowerLim 1;
BA_ "U_B515_MCA_MY17_Gas_Tx" SG_ 613 OCSSensrDataLowerLim 1;
BA_ "U_B515_MCA_MY17_Diesel_Tx" SG_ 613 OCSSensrDataLowerLim 1;
BA_ "U_B479_MY17_Diesel_Tx" SG_ 613 OCSSensrDataLowerLim 1;
BA_ "U_B479_MY17_Gas_Tx" SG_ 613 OCSSensrDataLowerLim 1;
BA_ "U_CX482_CX483_MY20_Hev_Rx" SG_ 613 OCSSensrDataLowerLim 1;
BA_ "U_CX482_CX483_MY20_Gas_Rx" SG_ 613 OCSSensrDataLowerLim 1;
BA_ "U_CX482_CX483_MY20_Diesel_Rx" SG_ 613 OCSSensrDataLowerLim 1;
BA_ "U_U611_U625_MY20_Hev_Rx" SG_ 613 OCSSensrDataLowerLim 1;
BA_ "U_U611_U625_MY20_Gas_Rx" SG_ 613 OCSSensrDataLowerLim 1;
BA_ "U_U611_U625_MY20_Diesel_Rx" SG_ 613 OCSSensrDataLowerLim 1;
BA_ "U_C519_MY18_5_Gas_Rx" SG_ 613 OCSSensrDataLowerLim 1;
BA_ "U_C519_MY18_5_Diesel_Rx" SG_ 613 OCSSensrDataLowerLim 1;
BA_ "U_B515_MCA_MY17_Gas_Rx" SG_ 613 OCSSensrDataLowerLim 1;
BA_ "U_B515_MCA_MY17_Diesel_Rx" SG_ 613 OCSSensrDataLowerLim 1;
BA_ "U_B479_MY17_Diesel_Rx" SG_ 613 OCSSensrDataLowerLim 1;
BA_ "U_B479_MY17_Gas_Rx" SG_ 613 OCSSensrDataLowerLim 1;
BA_ "GenSigSendType" SG_ 613 OCSSensrDataLowerLim 3;
BA_ "U_U611_U625_MY20_Phev_Tx" SG_ 613 OCSLevel2Error 1;
BA_ "U_CX482_CX483_MY20_Hev_Tx" SG_ 613 OCSLevel2Error 1;
BA_ "U_CX482_CX483_MY20_Gas_Tx" SG_ 613 OCSLevel2Error 1;
BA_ "U_CX482_CX483_MY20_Diesel_Tx" SG_ 613 OCSLevel2Error 1;
BA_ "U_U611_U625_MY20_Hev_Tx" SG_ 613 OCSLevel2Error 1;
BA_ "U_U611_U625_MY20_Gas_Tx" SG_ 613 OCSLevel2Error 1;
BA_ "U_U611_U625_MY20_Diesel_Tx" SG_ 613 OCSLevel2Error 1;
BA_ "U_C519_MY18_5_Gas_Tx" SG_ 613 OCSLevel2Error 1;
BA_ "U_C519_MY18_5_Diesel_Tx" SG_ 613 OCSLevel2Error 1;
BA_ "U_B515_MCA_MY17_Gas_Tx" SG_ 613 OCSLevel2Error 1;
BA_ "U_B515_MCA_MY17_Diesel_Tx" SG_ 613 OCSLevel2Error 1;
BA_ "U_B479_MY17_Diesel_Tx" SG_ 613 OCSLevel2Error 1;
BA_ "U_B479_MY17_Gas_Tx" SG_ 613 OCSLevel2Error 1;
BA_ "U_CX482_CX483_MY20_Hev_Rx" SG_ 613 OCSLevel2Error 1;
BA_ "U_CX482_CX483_MY20_Gas_Rx" SG_ 613 OCSLevel2Error 1;
BA_ "U_CX482_CX483_MY20_Diesel_Rx" SG_ 613 OCSLevel2Error 1;
BA_ "U_U611_U625_MY20_Hev_Rx" SG_ 613 OCSLevel2Error 1;
BA_ "U_U611_U625_MY20_Gas_Rx" SG_ 613 OCSLevel2Error 1;
BA_ "U_U611_U625_MY20_Diesel_Rx" SG_ 613 OCSLevel2Error 1;
BA_ "U_C519_MY18_5_Gas_Rx" SG_ 613 OCSLevel2Error 1;
BA_ "U_C519_MY18_5_Diesel_Rx" SG_ 613 OCSLevel2Error 1;
BA_ "U_B515_MCA_MY17_Gas_Rx" SG_ 613 OCSLevel2Error 1;
BA_ "U_B515_MCA_MY17_Diesel_Rx" SG_ 613 OCSLevel2Error 1;
BA_ "U_B479_MY17_Diesel_Rx" SG_ 613 OCSLevel2Error 1;
BA_ "U_B479_MY17_Gas_Rx" SG_ 613 OCSLevel2Error 1;
BA_ "GenSigSendType" SG_ 613 ObjectEntrapped 3;
BA_ "CrossOver_InfoCAN" SG_ 613 ObjectEntrapped 1;
BA_ "U_U611_U625_MY20_Phev_Tx" SG_ 613 OCSLevel1Error 1;
BA_ "U_CX482_CX483_MY20_Hev_Tx" SG_ 613 OCSLevel1Error 1;
BA_ "U_CX482_CX483_MY20_Gas_Tx" SG_ 613 OCSLevel1Error 1;
BA_ "U_CX482_CX483_MY20_Diesel_Tx" SG_ 613 OCSLevel1Error 1;
BA_ "U_U611_U625_MY20_Hev_Tx" SG_ 613 OCSLevel1Error 1;
BA_ "U_U611_U625_MY20_Gas_Tx" SG_ 613 OCSLevel1Error 1;
BA_ "U_U611_U625_MY20_Diesel_Tx" SG_ 613 OCSLevel1Error 1;
BA_ "U_C519_MY18_5_Gas_Tx" SG_ 613 OCSLevel1Error 1;
BA_ "U_C519_MY18_5_Diesel_Tx" SG_ 613 OCSLevel1Error 1;
BA_ "U_B515_MCA_MY17_Gas_Tx" SG_ 613 OCSLevel1Error 1;
BA_ "U_B515_MCA_MY17_Diesel_Tx" SG_ 613 OCSLevel1Error 1;
BA_ "U_B479_MY17_Diesel_Tx" SG_ 613 OCSLevel1Error 1;
BA_ "U_B479_MY17_Gas_Tx" SG_ 613 OCSLevel1Error 1;
BA_ "U_CX482_CX483_MY20_Hev_Rx" SG_ 613 OCSLevel1Error 1;
BA_ "U_CX482_CX483_MY20_Gas_Rx" SG_ 613 OCSLevel1Error 1;
BA_ "U_CX482_CX483_MY20_Diesel_Rx" SG_ 613 OCSLevel1Error 1;
BA_ "U_U611_U625_MY20_Hev_Rx" SG_ 613 OCSLevel1Error 1;
BA_ "U_U611_U625_MY20_Gas_Rx" SG_ 613 OCSLevel1Error 1;
BA_ "U_U611_U625_MY20_Diesel_Rx" SG_ 613 OCSLevel1Error 1;
BA_ "U_C519_MY18_5_Gas_Rx" SG_ 613 OCSLevel1Error 1;
BA_ "U_C519_MY18_5_Diesel_Rx" SG_ 613 OCSLevel1Error 1;
BA_ "U_B515_MCA_MY17_Gas_Rx" SG_ 613 OCSLevel1Error 1;
BA_ "U_B515_MCA_MY17_Diesel_Rx" SG_ 613 OCSLevel1Error 1;
BA_ "U_B479_MY17_Diesel_Rx" SG_ 613 OCSLevel1Error 1;
BA_ "U_B479_MY17_Gas_Rx" SG_ 613 OCSLevel1Error 1;
BA_ "GenSigSendType" SG_ 613 OCSLevel1Error 3;
BA_ "U_U611_U625_MY20_Phev_Rx" SG_ 1840 TesterPhysicalReqPSCM 1;
BA_ "U_CX482_CX483_MY20_Hev_Rx" SG_ 1840 TesterPhysicalReqPSCM 1;
BA_ "U_CX482_CX483_MY20_Gas_Rx" SG_ 1840 TesterPhysicalReqPSCM 1;
BA_ "U_CX482_CX483_MY20_Diesel_Rx" SG_ 1840 TesterPhysicalReqPSCM 1;
BA_ "U_U611_U625_MY20_Hev_Rx" SG_ 1840 TesterPhysicalReqPSCM 1;
BA_ "U_U611_U625_MY20_Gas_Rx" SG_ 1840 TesterPhysicalReqPSCM 1;
BA_ "U_U611_U625_MY20_Diesel_Rx" SG_ 1840 TesterPhysicalReqPSCM 1;
BA_ "U_B500_MY18_Diesel_Rx" SG_ 1840 TesterPhysicalReqPSCM 1;
BA_ "U_B500_MY18_Gas_Rx" SG_ 1840 TesterPhysicalReqPSCM 1;
BA_ "U_C490_MY18_Rx" SG_ 1840 TesterPhysicalReqPSCM 1;
BA_ "U_B562_MY18_Gas_Rx" SG_ 1840 TesterPhysicalReqPSCM 1;
BA_ "U_C519_MY18_5_Gas_Rx" SG_ 1840 TesterPhysicalReqPSCM 1;
BA_ "U_C519_MY18_5_Diesel_Rx" SG_ 1840 TesterPhysicalReqPSCM 1;
BA_ "U_B515_MCA_MY17_Gas_Rx" SG_ 1840 TesterPhysicalReqPSCM 1;
BA_ "U_B515_MCA_MY17_Diesel_Rx" SG_ 1840 TesterPhysicalReqPSCM 1;
BA_ "U_B479_MY17_Diesel_Rx" SG_ 1840 TesterPhysicalReqPSCM 1;
BA_ "U_B479_MY17_Gas_Rx" SG_ 1840 TesterPhysicalReqPSCM 1;
BA_ "GenSigSendType" SG_ 1840 TesterPhysicalReqPSCM 3;
BA_ "U_CX482_CX483_MY20_Hev_Tx" SG_ 1664 UUDTRCMResponse1 1;
BA_ "U_CX482_CX483_MY20_Gas_Tx" SG_ 1664 UUDTRCMResponse1 1;
BA_ "U_CX482_CX483_MY20_Diesel_Tx" SG_ 1664 UUDTRCMResponse1 1;
BA_ "U_U611_U625_MY20_Hev_Tx" SG_ 1664 UUDTRCMResponse1 1;
BA_ "U_U611_U625_MY20_Gas_Tx" SG_ 1664 UUDTRCMResponse1 1;
BA_ "U_U611_U625_MY20_Diesel_Tx" SG_ 1664 UUDTRCMResponse1 1;
BA_ "U_B500_MY18_Diesel_Tx" SG_ 1664 UUDTRCMResponse1 1;
BA_ "U_B500_MY18_Gas_Tx" SG_ 1664 UUDTRCMResponse1 1;
BA_ "U_C490_MY18_Tx" SG_ 1664 UUDTRCMResponse1 1;
BA_ "U_B562_MY18_Gas_Tx" SG_ 1664 UUDTRCMResponse1 1;
BA_ "U_C519_MY18_5_Gas_Tx" SG_ 1664 UUDTRCMResponse1 1;
BA_ "U_C519_MY18_5_Diesel_Tx" SG_ 1664 UUDTRCMResponse1 1;
BA_ "U_B515_MCA_MY17_Gas_Tx" SG_ 1664 UUDTRCMResponse1 1;
BA_ "U_B515_MCA_MY17_Diesel_Tx" SG_ 1664 UUDTRCMResponse1 1;
BA_ "U_B479_MY17_Diesel_Tx" SG_ 1664 UUDTRCMResponse1 1;
BA_ "U_B479_MY17_Gas_Tx" SG_ 1664 UUDTRCMResponse1 1;
BA_ "GenSigSendType" SG_ 1664 UUDTRCMResponse1 3;
BA_ "GenSigSendType" SG_ 1814 TesterPhysicalReqGWM_H2 3;
BA_ "U_CX482_CX483_MY20_Hev_Rx" SG_ 2033 TesterPhysicalReqPCU 1;
BA_ "U_CX482_CX483_MY20_Gas_Rx" SG_ 2033 TesterPhysicalReqPCU 1;
BA_ "U_CX482_CX483_MY20_Diesel_Rx" SG_ 2033 TesterPhysicalReqPCU 1;
BA_ "U_U611_U625_MY20_Hev_Rx" SG_ 2033 TesterPhysicalReqPCU 1;
BA_ "U_U611_U625_MY20_Gas_Rx" SG_ 2033 TesterPhysicalReqPCU 1;
BA_ "U_U611_U625_MY20_Diesel_Rx" SG_ 2033 TesterPhysicalReqPCU 1;
BA_ "U_B500_MY18_Diesel_Rx" SG_ 2033 TesterPhysicalReqPCU 1;
BA_ "U_B500_MY18_Gas_Rx" SG_ 2033 TesterPhysicalReqPCU 1;
BA_ "U_C490_MY18_Rx" SG_ 2033 TesterPhysicalReqPCU 1;
BA_ "U_B562_MY18_Gas_Rx" SG_ 2033 TesterPhysicalReqPCU 1;
BA_ "U_C519_MY18_5_Gas_Rx" SG_ 2033 TesterPhysicalReqPCU 1;
BA_ "U_C519_MY18_5_Diesel_Rx" SG_ 2033 TesterPhysicalReqPCU 1;
BA_ "U_B515_MCA_MY17_Gas_Rx" SG_ 2033 TesterPhysicalReqPCU 1;
BA_ "U_B515_MCA_MY17_Diesel_Rx" SG_ 2033 TesterPhysicalReqPCU 1;
BA_ "U_B479_MY17_Diesel_Rx" SG_ 2033 TesterPhysicalReqPCU 1;
BA_ "U_B479_MY17_Gas_Rx" SG_ 2033 TesterPhysicalReqPCU 1;
BA_ "GenSigSendType" SG_ 2033 TesterPhysicalReqPCU 3;
BA_ "CrossOver_InfoCAN" SG_ 130 TrlrHitchLamp_D_Rqst 1;
BA_ "CrossOver_InfoCAN" SG_ 130 VehVTrlrAid_B_Rq 1;
BA_ "U_U611_U625_MY20_Phev_Tx" SG_ 130 SteEffort_D_Stat 1;
BA_ "U_CX482_CX483_MY20_Hev_Tx" SG_ 130 SteEffort_D_Stat 1;
BA_ "U_CX482_CX483_MY20_Gas_Tx" SG_ 130 SteEffort_D_Stat 1;
BA_ "U_CX482_CX483_MY20_Diesel_Tx" SG_ 130 SteEffort_D_Stat 1;
BA_ "U_U611_U625_MY20_Hev_Tx" SG_ 130 SteEffort_D_Stat 1;
BA_ "U_U611_U625_MY20_Gas_Tx" SG_ 130 SteEffort_D_Stat 1;
BA_ "U_U611_U625_MY20_Diesel_Tx" SG_ 130 SteEffort_D_Stat 1;
BA_ "U_B500_MY18_Diesel_Tx" SG_ 130 SteEffort_D_Stat 1;
BA_ "U_B500_MY18_Gas_Tx" SG_ 130 SteEffort_D_Stat 1;
BA_ "U_C519_MY18_5_Gas_Tx" SG_ 130 SteEffort_D_Stat 1;
BA_ "U_C519_MY18_5_Diesel_Tx" SG_ 130 SteEffort_D_Stat 1;
BA_ "U_B479_MY17_Diesel_Tx" SG_ 130 SteEffort_D_Stat 1;
BA_ "U_B479_MY17_Gas_Tx" SG_ 130 SteEffort_D_Stat 1;
BA_ "GenSigStartValue" SG_ 130 Veh_V_RqMxTrlrAid 255;
BA_ "U_B479_MY17_Diesel_Rx" SG_ 130 DrvSteActv_B_Stat 1;
BA_ "U_B479_MY17_Gas_Rx" SG_ 130 DrvSteActv_B_Stat 1;
BA_ "U_B479_MY17_Diesel_Rx" SG_ 130 DrvSte_Tq_Actl 1;
BA_ "U_B479_MY17_Gas_Rx" SG_ 130 DrvSte_Tq_Actl 1;
BA_ "GenSigStartValue" SG_ 130 DrvSte_Tq_Actl 128;
BA_ "U_U611_U625_MY20_Phev_Tx" SG_ 130 SteMdule_D_Stat 1;
BA_ "U_CX482_CX483_MY20_Hev_Tx" SG_ 130 SteMdule_D_Stat 1;
BA_ "U_CX482_CX483_MY20_Gas_Tx" SG_ 130 SteMdule_D_Stat 1;
BA_ "U_CX482_CX483_MY20_Diesel_Tx" SG_ 130 SteMdule_D_Stat 1;
BA_ "U_U611_U625_MY20_Hev_Tx" SG_ 130 SteMdule_D_Stat 1;
BA_ "U_U611_U625_MY20_Gas_Tx" SG_ 130 SteMdule_D_Stat 1;
BA_ "U_U611_U625_MY20_Diesel_Tx" SG_ 130 SteMdule_D_Stat 1;
BA_ "U_B500_MY18_Diesel_Tx" SG_ 130 SteMdule_D_Stat 1;
BA_ "U_B500_MY18_Gas_Tx" SG_ 130 SteMdule_D_Stat 1;
BA_ "U_C519_MY18_5_Gas_Tx" SG_ 130 SteMdule_D_Stat 1;
BA_ "U_C519_MY18_5_Diesel_Tx" SG_ 130 SteMdule_D_Stat 1;
BA_ "U_B479_MY17_Diesel_Tx" SG_ 130 SteMdule_D_Stat 1;
BA_ "U_B479_MY17_Gas_Tx" SG_ 130 SteMdule_D_Stat 1;
BA_ "U_U611_U625_MY20_Hev_Rx" SG_ 130 SteMdule_D_Stat 1;
BA_ "U_U611_U625_MY20_Gas_Rx" SG_ 130 SteMdule_D_Stat 1;
BA_ "U_U611_U625_MY20_Diesel_Rx" SG_ 130 SteMdule_D_Stat 1;
BA_ "U_U611_U625_MY20_Phev_Tx" SG_ 130 SteMdule_U_Meas 1;
BA_ "U_CX482_CX483_MY20_Hev_Tx" SG_ 130 SteMdule_U_Meas 1;
BA_ "U_CX482_CX483_MY20_Gas_Tx" SG_ 130 SteMdule_U_Meas 1;
BA_ "U_CX482_CX483_MY20_Diesel_Tx" SG_ 130 SteMdule_U_Meas 1;
BA_ "U_U611_U625_MY20_Hev_Tx" SG_ 130 SteMdule_U_Meas 1;
BA_ "U_U611_U625_MY20_Gas_Tx" SG_ 130 SteMdule_U_Meas 1;
BA_ "U_U611_U625_MY20_Diesel_Tx" SG_ 130 SteMdule_U_Meas 1;
BA_ "U_B500_MY18_Diesel_Tx" SG_ 130 SteMdule_U_Meas 1;
BA_ "U_B500_MY18_Gas_Tx" SG_ 130 SteMdule_U_Meas 1;
BA_ "U_C490_MY18_Tx" SG_ 130 SteMdule_U_Meas 1;
BA_ "U_B562_MY18_Gas_Tx" SG_ 130 SteMdule_U_Meas 1;
BA_ "U_C519_MY18_5_Gas_Tx" SG_ 130 SteMdule_U_Meas 1;
BA_ "U_C519_MY18_5_Diesel_Tx" SG_ 130 SteMdule_U_Meas 1;
BA_ "U_B515_MCA_MY17_Gas_Tx" SG_ 130 SteMdule_U_Meas 1;
BA_ "U_B515_MCA_MY17_Diesel_Tx" SG_ 130 SteMdule_U_Meas 1;
BA_ "U_B479_MY17_Diesel_Tx" SG_ 130 SteMdule_U_Meas 1;
BA_ "U_B479_MY17_Gas_Tx" SG_ 130 SteMdule_U_Meas 1;
BA_ "GenSigStartValue" SG_ 130 SteMdule_U_Meas 255;
BA_ "U_U611_U625_MY20_Phev_Tx" SG_ 130 SteMdule_I_Est 1;
BA_ "U_CX482_CX483_MY20_Hev_Tx" SG_ 130 SteMdule_I_Est 1;
BA_ "U_CX482_CX483_MY20_Gas_Tx" SG_ 130 SteMdule_I_Est 1;
BA_ "U_CX482_CX483_MY20_Diesel_Tx" SG_ 130 SteMdule_I_Est 1;
BA_ "U_U611_U625_MY20_Hev_Tx" SG_ 130 SteMdule_I_Est 1;
BA_ "U_U611_U625_MY20_Gas_Tx" SG_ 130 SteMdule_I_Est 1;
BA_ "U_U611_U625_MY20_Diesel_Tx" SG_ 130 SteMdule_I_Est 1;
BA_ "U_B500_MY18_Diesel_Tx" SG_ 130 SteMdule_I_Est 1;
BA_ "U_B500_MY18_Gas_Tx" SG_ 130 SteMdule_I_Est 1;
BA_ "U_C490_MY18_Tx" SG_ 130 SteMdule_I_Est 1;
BA_ "U_B562_MY18_Gas_Tx" SG_ 130 SteMdule_I_Est 1;
BA_ "U_C519_MY18_5_Gas_Tx" SG_ 130 SteMdule_I_Est 1;
BA_ "U_C519_MY18_5_Diesel_Tx" SG_ 130 SteMdule_I_Est 1;
BA_ "U_B515_MCA_MY17_Gas_Tx" SG_ 130 SteMdule_I_Est 1;
BA_ "U_B515_MCA_MY17_Diesel_Tx" SG_ 130 SteMdule_I_Est 1;
BA_ "U_B479_MY17_Diesel_Tx" SG_ 130 SteMdule_I_Est 1;
BA_ "U_B479_MY17_Gas_Tx" SG_ 130 SteMdule_I_Est 1;
BA_ "GenSigStartValue" SG_ 130 SteMdule_I_Est 4095;
BA_ "U_U611_U625_MY20_Phev_Tx" SG_ 130 EPAS_Failure 1;
BA_ "U_CX482_CX483_MY20_Hev_Tx" SG_ 130 EPAS_Failure 1;
BA_ "U_CX482_CX483_MY20_Gas_Tx" SG_ 130 EPAS_Failure 1;
BA_ "U_CX482_CX483_MY20_Diesel_Tx" SG_ 130 EPAS_Failure 1;
BA_ "U_U611_U625_MY20_Hev_Tx" SG_ 130 EPAS_Failure 1;
BA_ "U_U611_U625_MY20_Gas_Tx" SG_ 130 EPAS_Failure 1;
BA_ "U_U611_U625_MY20_Diesel_Tx" SG_ 130 EPAS_Failure 1;
BA_ "U_B500_MY18_Diesel_Tx" SG_ 130 EPAS_Failure 1;
BA_ "U_B500_MY18_Gas_Tx" SG_ 130 EPAS_Failure 1;
BA_ "U_C490_MY18_Tx" SG_ 130 EPAS_Failure 1;
BA_ "U_B562_MY18_Gas_Tx" SG_ 130 EPAS_Failure 1;
BA_ "U_C519_MY18_5_Gas_Tx" SG_ 130 EPAS_Failure 1;
BA_ "U_C519_MY18_5_Diesel_Tx" SG_ 130 EPAS_Failure 1;
BA_ "U_B515_MCA_MY17_Gas_Tx" SG_ 130 EPAS_Failure 1;
BA_ "U_B515_MCA_MY17_Diesel_Tx" SG_ 130 EPAS_Failure 1;
BA_ "U_B479_MY17_Diesel_Tx" SG_ 130 EPAS_Failure 1;
BA_ "U_B479_MY17_Gas_Tx" SG_ 130 EPAS_Failure 1;
BA_ "CrossOver_InfoCAN" SG_ 130 EPAS_Failure 1;
BA_ "U_U611_U625_MY20_Phev_Tx" SG_ 130 SteeringColumnTorque 1;
BA_ "U_CX482_CX483_MY20_Hev_Tx" SG_ 130 SteeringColumnTorque 1;
BA_ "U_CX482_CX483_MY20_Gas_Tx" SG_ 130 SteeringColumnTorque 1;
BA_ "U_CX482_CX483_MY20_Diesel_Tx" SG_ 130 SteeringColumnTorque 1;
BA_ "U_U611_U625_MY20_Hev_Tx" SG_ 130 SteeringColumnTorque 1;
BA_ "U_U611_U625_MY20_Gas_Tx" SG_ 130 SteeringColumnTorque 1;
BA_ "U_U611_U625_MY20_Diesel_Tx" SG_ 130 SteeringColumnTorque 1;
BA_ "U_B500_MY18_Diesel_Tx" SG_ 130 SteeringColumnTorque 1;
BA_ "U_B500_MY18_Gas_Tx" SG_ 130 SteeringColumnTorque 1;
BA_ "U_C490_MY18_Tx" SG_ 130 SteeringColumnTorque 1;
BA_ "U_B562_MY18_Gas_Tx" SG_ 130 SteeringColumnTorque 1;
BA_ "U_C519_MY18_5_Gas_Tx" SG_ 130 SteeringColumnTorque 1;
BA_ "U_C519_MY18_5_Diesel_Tx" SG_ 130 SteeringColumnTorque 1;
BA_ "U_B515_MCA_MY17_Gas_Tx" SG_ 130 SteeringColumnTorque 1;
BA_ "U_B515_MCA_MY17_Diesel_Tx" SG_ 130 SteeringColumnTorque 1;
BA_ "U_B479_MY17_Diesel_Tx" SG_ 130 SteeringColumnTorque 1;
BA_ "U_B479_MY17_Gas_Tx" SG_ 130 SteeringColumnTorque 1;
BA_ "U_CX482_CX483_MY20_Hev_Rx" SG_ 130 SteeringColumnTorque 1;
BA_ "U_CX482_CX483_MY20_Gas_Rx" SG_ 130 SteeringColumnTorque 1;
BA_ "U_CX482_CX483_MY20_Diesel_Rx" SG_ 130 SteeringColumnTorque 1;
BA_ "U_B500_MY18_Diesel_Rx" SG_ 130 SteeringColumnTorque 1;
BA_ "U_B500_MY18_Gas_Rx" SG_ 130 SteeringColumnTorque 1;
BA_ "U_C490_MY18_Rx" SG_ 130 SteeringColumnTorque 1;
BA_ "U_B562_MY18_Gas_Rx" SG_ 130 SteeringColumnTorque 1;
BA_ "U_C519_MY18_5_Gas_Rx" SG_ 130 SteeringColumnTorque 1;
BA_ "U_C519_MY18_5_Diesel_Rx" SG_ 130 SteeringColumnTorque 1;
BA_ "U_B515_MCA_MY17_Gas_Rx" SG_ 130 SteeringColumnTorque 1;
BA_ "U_B515_MCA_MY17_Diesel_Rx" SG_ 130 SteeringColumnTorque 1;
BA_ "U_B479_MY17_Diesel_Rx" SG_ 130 SteeringColumnTorque 1;
BA_ "U_B479_MY17_Gas_Rx" SG_ 130 SteeringColumnTorque 1;
BA_ "GenSigStartValue" SG_ 130 SteeringColumnTorque 254;
BA_ "U_U611_U625_MY20_Phev_Tx" SG_ 130 SAPPAngleControlStat6 1;
BA_ "U_CX482_CX483_MY20_Hev_Tx" SG_ 130 SAPPAngleControlStat6 1;
BA_ "U_CX482_CX483_MY20_Gas_Tx" SG_ 130 SAPPAngleControlStat6 1;
BA_ "U_CX482_CX483_MY20_Diesel_Tx" SG_ 130 SAPPAngleControlStat6 1;
BA_ "U_U611_U625_MY20_Hev_Tx" SG_ 130 SAPPAngleControlStat6 1;
BA_ "U_U611_U625_MY20_Gas_Tx" SG_ 130 SAPPAngleControlStat6 1;
BA_ "U_U611_U625_MY20_Diesel_Tx" SG_ 130 SAPPAngleControlStat6 1;
BA_ "U_B500_MY18_Diesel_Tx" SG_ 130 SAPPAngleControlStat6 1;
BA_ "U_B500_MY18_Gas_Tx" SG_ 130 SAPPAngleControlStat6 1;
BA_ "U_C519_MY18_5_Gas_Tx" SG_ 130 SAPPAngleControlStat6 1;
BA_ "U_C519_MY18_5_Diesel_Tx" SG_ 130 SAPPAngleControlStat6 1;
BA_ "U_B479_MY17_Diesel_Tx" SG_ 130 SAPPAngleControlStat6 1;
BA_ "U_B479_MY17_Gas_Tx" SG_ 130 SAPPAngleControlStat6 1;
BA_ "U_U611_U625_MY20_Phev_Tx" SG_ 130 SAPPAngleControlStat5 1;
BA_ "U_CX482_CX483_MY20_Hev_Tx" SG_ 130 SAPPAngleControlStat5 1;
BA_ "U_CX482_CX483_MY20_Gas_Tx" SG_ 130 SAPPAngleControlStat5 1;
BA_ "U_CX482_CX483_MY20_Diesel_Tx" SG_ 130 SAPPAngleControlStat5 1;
BA_ "U_U611_U625_MY20_Hev_Tx" SG_ 130 SAPPAngleControlStat5 1;
BA_ "U_U611_U625_MY20_Gas_Tx" SG_ 130 SAPPAngleControlStat5 1;
BA_ "U_U611_U625_MY20_Diesel_Tx" SG_ 130 SAPPAngleControlStat5 1;
BA_ "U_B500_MY18_Diesel_Tx" SG_ 130 SAPPAngleControlStat5 1;
BA_ "U_B500_MY18_Gas_Tx" SG_ 130 SAPPAngleControlStat5 1;
BA_ "U_C519_MY18_5_Gas_Tx" SG_ 130 SAPPAngleControlStat5 1;
BA_ "U_C519_MY18_5_Diesel_Tx" SG_ 130 SAPPAngleControlStat5 1;
BA_ "U_B479_MY17_Diesel_Tx" SG_ 130 SAPPAngleControlStat5 1;
BA_ "U_B479_MY17_Gas_Tx" SG_ 130 SAPPAngleControlStat5 1;
BA_ "U_U611_U625_MY20_Phev_Tx" SG_ 130 SAPPAngleControlStat4 1;
BA_ "U_CX482_CX483_MY20_Hev_Tx" SG_ 130 SAPPAngleControlStat4 1;
BA_ "U_CX482_CX483_MY20_Gas_Tx" SG_ 130 SAPPAngleControlStat4 1;
BA_ "U_CX482_CX483_MY20_Diesel_Tx" SG_ 130 SAPPAngleControlStat4 1;
BA_ "U_U611_U625_MY20_Hev_Tx" SG_ 130 SAPPAngleControlStat4 1;
BA_ "U_U611_U625_MY20_Gas_Tx" SG_ 130 SAPPAngleControlStat4 1;
BA_ "U_U611_U625_MY20_Diesel_Tx" SG_ 130 SAPPAngleControlStat4 1;
BA_ "U_B500_MY18_Diesel_Tx" SG_ 130 SAPPAngleControlStat4 1;
BA_ "U_B500_MY18_Gas_Tx" SG_ 130 SAPPAngleControlStat4 1;
BA_ "U_C519_MY18_5_Gas_Tx" SG_ 130 SAPPAngleControlStat4 1;
BA_ "U_C519_MY18_5_Diesel_Tx" SG_ 130 SAPPAngleControlStat4 1;
BA_ "U_B479_MY17_Diesel_Tx" SG_ 130 SAPPAngleControlStat4 1;
BA_ "U_B479_MY17_Gas_Tx" SG_ 130 SAPPAngleControlStat4 1;
BA_ "U_U611_U625_MY20_Phev_Tx" SG_ 130 SAPPAngleControlStat3 1;
BA_ "U_CX482_CX483_MY20_Hev_Tx" SG_ 130 SAPPAngleControlStat3 1;
BA_ "U_CX482_CX483_MY20_Gas_Tx" SG_ 130 SAPPAngleControlStat3 1;
BA_ "U_CX482_CX483_MY20_Diesel_Tx" SG_ 130 SAPPAngleControlStat3 1;
BA_ "U_U611_U625_MY20_Hev_Tx" SG_ 130 SAPPAngleControlStat3 1;
BA_ "U_U611_U625_MY20_Gas_Tx" SG_ 130 SAPPAngleControlStat3 1;
BA_ "U_U611_U625_MY20_Diesel_Tx" SG_ 130 SAPPAngleControlStat3 1;
BA_ "U_B500_MY18_Diesel_Tx" SG_ 130 SAPPAngleControlStat3 1;
BA_ "U_B500_MY18_Gas_Tx" SG_ 130 SAPPAngleControlStat3 1;
BA_ "U_C519_MY18_5_Gas_Tx" SG_ 130 SAPPAngleControlStat3 1;
BA_ "U_C519_MY18_5_Diesel_Tx" SG_ 130 SAPPAngleControlStat3 1;
BA_ "U_B479_MY17_Diesel_Tx" SG_ 130 SAPPAngleControlStat3 1;
BA_ "U_B479_MY17_Gas_Tx" SG_ 130 SAPPAngleControlStat3 1;
BA_ "U_U611_U625_MY20_Phev_Tx" SG_ 130 SAPPAngleControlStat2 1;
BA_ "U_CX482_CX483_MY20_Hev_Tx" SG_ 130 SAPPAngleControlStat2 1;
BA_ "U_CX482_CX483_MY20_Gas_Tx" SG_ 130 SAPPAngleControlStat2 1;
BA_ "U_CX482_CX483_MY20_Diesel_Tx" SG_ 130 SAPPAngleControlStat2 1;
BA_ "U_U611_U625_MY20_Hev_Tx" SG_ 130 SAPPAngleControlStat2 1;
BA_ "U_U611_U625_MY20_Gas_Tx" SG_ 130 SAPPAngleControlStat2 1;
BA_ "U_U611_U625_MY20_Diesel_Tx" SG_ 130 SAPPAngleControlStat2 1;
BA_ "U_B500_MY18_Diesel_Tx" SG_ 130 SAPPAngleControlStat2 1;
BA_ "U_B500_MY18_Gas_Tx" SG_ 130 SAPPAngleControlStat2 1;
BA_ "U_C519_MY18_5_Gas_Tx" SG_ 130 SAPPAngleControlStat2 1;
BA_ "U_C519_MY18_5_Diesel_Tx" SG_ 130 SAPPAngleControlStat2 1;
BA_ "U_B479_MY17_Diesel_Tx" SG_ 130 SAPPAngleControlStat2 1;
BA_ "U_B479_MY17_Gas_Tx" SG_ 130 SAPPAngleControlStat2 1;
BA_ "U_U611_U625_MY20_Phev_Tx" SG_ 130 SAPPAngleControlStat1 1;
BA_ "U_CX482_CX483_MY20_Hev_Tx" SG_ 130 SAPPAngleControlStat1 1;
BA_ "U_CX482_CX483_MY20_Gas_Tx" SG_ 130 SAPPAngleControlStat1 1;
BA_ "U_CX482_CX483_MY20_Diesel_Tx" SG_ 130 SAPPAngleControlStat1 1;
BA_ "U_U611_U625_MY20_Hev_Tx" SG_ 130 SAPPAngleControlStat1 1;
BA_ "U_U611_U625_MY20_Gas_Tx" SG_ 130 SAPPAngleControlStat1 1;
BA_ "U_U611_U625_MY20_Diesel_Tx" SG_ 130 SAPPAngleControlStat1 1;
BA_ "U_B500_MY18_Diesel_Tx" SG_ 130 SAPPAngleControlStat1 1;
BA_ "U_B500_MY18_Gas_Tx" SG_ 130 SAPPAngleControlStat1 1;
BA_ "U_C519_MY18_5_Gas_Tx" SG_ 130 SAPPAngleControlStat1 1;
BA_ "U_C519_MY18_5_Diesel_Tx" SG_ 130 SAPPAngleControlStat1 1;
BA_ "U_B479_MY17_Diesel_Tx" SG_ 130 SAPPAngleControlStat1 1;
BA_ "U_B479_MY17_Gas_Tx" SG_ 130 SAPPAngleControlStat1 1;
BA_ "U_CX482_CX483_MY20_Hev_Tx" SG_ 1855 TesterPhysicalResRCM 1;
BA_ "U_CX482_CX483_MY20_Gas_Tx" SG_ 1855 TesterPhysicalResRCM 1;
BA_ "U_CX482_CX483_MY20_Diesel_Tx" SG_ 1855 TesterPhysicalResRCM 1;
BA_ "U_U611_U625_MY20_Hev_Tx" SG_ 1855 TesterPhysicalResRCM 1;
BA_ "U_U611_U625_MY20_Gas_Tx" SG_ 1855 TesterPhysicalResRCM 1;
BA_ "U_U611_U625_MY20_Diesel_Tx" SG_ 1855 TesterPhysicalResRCM 1;
BA_ "U_B500_MY18_Diesel_Tx" SG_ 1855 TesterPhysicalResRCM 1;
BA_ "U_B500_MY18_Gas_Tx" SG_ 1855 TesterPhysicalResRCM 1;
BA_ "U_C490_MY18_Tx" SG_ 1855 TesterPhysicalResRCM 1;
BA_ "U_B562_MY18_Gas_Tx" SG_ 1855 TesterPhysicalResRCM 1;
BA_ "U_C519_MY18_5_Gas_Tx" SG_ 1855 TesterPhysicalResRCM 1;
BA_ "U_C519_MY18_5_Diesel_Tx" SG_ 1855 TesterPhysicalResRCM 1;
BA_ "U_B515_MCA_MY17_Gas_Tx" SG_ 1855 TesterPhysicalResRCM 1;
BA_ "U_B515_MCA_MY17_Diesel_Tx" SG_ 1855 TesterPhysicalResRCM 1;
BA_ "U_B479_MY17_Diesel_Tx" SG_ 1855 TesterPhysicalResRCM 1;
BA_ "U_B479_MY17_Gas_Tx" SG_ 1855 TesterPhysicalResRCM 1;
BA_ "GenSigSendType" SG_ 1855 TesterPhysicalResRCM 3;
BA_ "U_CX482_CX483_MY20_Hev_Rx" SG_ 1847 TesterPhysicalReqRCM 1;
BA_ "U_CX482_CX483_MY20_Gas_Rx" SG_ 1847 TesterPhysicalReqRCM 1;
BA_ "U_CX482_CX483_MY20_Diesel_Rx" SG_ 1847 TesterPhysicalReqRCM 1;
BA_ "U_U611_U625_MY20_Hev_Rx" SG_ 1847 TesterPhysicalReqRCM 1;
BA_ "U_U611_U625_MY20_Gas_Rx" SG_ 1847 TesterPhysicalReqRCM 1;
BA_ "U_U611_U625_MY20_Diesel_Rx" SG_ 1847 TesterPhysicalReqRCM 1;
BA_ "U_B500_MY18_Diesel_Rx" SG_ 1847 TesterPhysicalReqRCM 1;
BA_ "U_B500_MY18_Gas_Rx" SG_ 1847 TesterPhysicalReqRCM 1;
BA_ "U_C490_MY18_Rx" SG_ 1847 TesterPhysicalReqRCM 1;
BA_ "U_B562_MY18_Gas_Rx" SG_ 1847 TesterPhysicalReqRCM 1;
BA_ "U_C519_MY18_5_Gas_Rx" SG_ 1847 TesterPhysicalReqRCM 1;
BA_ "U_C519_MY18_5_Diesel_Rx" SG_ 1847 TesterPhysicalReqRCM 1;
BA_ "U_B515_MCA_MY17_Gas_Rx" SG_ 1847 TesterPhysicalReqRCM 1;
BA_ "U_B515_MCA_MY17_Diesel_Rx" SG_ 1847 TesterPhysicalReqRCM 1;
BA_ "U_B479_MY17_Diesel_Rx" SG_ 1847 TesterPhysicalReqRCM 1;
BA_ "U_B479_MY17_Gas_Rx" SG_ 1847 TesterPhysicalReqRCM 1;
BA_ "GenSigSendType" SG_ 1847 TesterPhysicalReqRCM 3;
BA_ "GenSigTimeoutTime_GWM" SG_ 827 SteClmnSwtchTlt_D_Stat 180;
BA_ "U_U611_U625_MY20_Phev_Tx" SG_ 827 SteClmnSwtchTlt_D_Stat 1;
BA_ "U_U611_U625_MY20_Hev_Tx" SG_ 827 SteClmnSwtchTlt_D_Stat 1;
BA_ "U_U611_U625_MY20_Gas_Tx" SG_ 827 SteClmnSwtchTlt_D_Stat 1;
BA_ "U_U611_U625_MY20_Diesel_Tx" SG_ 827 SteClmnSwtchTlt_D_Stat 1;
BA_ "GenSigSendType" SG_ 827 SteClmnSwtchTlt_D_Stat 3;
BA_ "WakeupSignal" SG_ 827 SteClmnSwtchTlt_D_Stat 1;
BA_ "GenSigTimeoutTime_GWM" SG_ 827 SteClmnSwtchTel_D_Stat 180;
BA_ "U_U611_U625_MY20_Phev_Tx" SG_ 827 SteClmnSwtchTel_D_Stat 1;
BA_ "U_U611_U625_MY20_Hev_Tx" SG_ 827 SteClmnSwtchTel_D_Stat 1;
BA_ "U_U611_U625_MY20_Gas_Tx" SG_ 827 SteClmnSwtchTel_D_Stat 1;
BA_ "U_U611_U625_MY20_Diesel_Tx" SG_ 827 SteClmnSwtchTel_D_Stat 1;
BA_ "GenSigSendType" SG_ 827 SteClmnSwtchTel_D_Stat 3;
BA_ "WakeupSignal" SG_ 827 SteClmnSwtchTel_D_Stat 1;
BA_ "GenSigTimeoutTime_GWM" SG_ 827 LghtAmbIntns_D_Sns 180;
BA_ "U_U611_U625_MY20_Phev_Tx" SG_ 827 LghtAmbIntns_D_Sns 1;
BA_ "U_CX482_CX483_MY20_Hev_Tx" SG_ 827 LghtAmbIntns_D_Sns 1;
BA_ "U_CX482_CX483_MY20_Gas_Tx" SG_ 827 LghtAmbIntns_D_Sns 1;
BA_ "U_CX482_CX483_MY20_Diesel_Tx" SG_ 827 LghtAmbIntns_D_Sns 1;
BA_ "U_U611_U625_MY20_Hev_Tx" SG_ 827 LghtAmbIntns_D_Sns 1;
BA_ "U_U611_U625_MY20_Gas_Tx" SG_ 827 LghtAmbIntns_D_Sns 1;
BA_ "U_U611_U625_MY20_Diesel_Tx" SG_ 827 LghtAmbIntns_D_Sns 1;
BA_ "U_C519_MY18_5_Gas_Tx" SG_ 827 LghtAmbIntns_D_Sns 1;
BA_ "U_C519_MY18_5_Diesel_Tx" SG_ 827 LghtAmbIntns_D_Sns 1;
BA_ "U_B515_MCA_MY17_Gas_Tx" SG_ 827 LghtAmbIntns_D_Sns 1;
BA_ "U_B515_MCA_MY17_Diesel_Tx" SG_ 827 LghtAmbIntns_D_Sns 1;
BA_ "GenSigSendType" SG_ 827 LghtAmbIntns_D_Sns 3;
BA_ "GenSigTimeoutTime_GWM" SG_ 827 LghtAmb_Intns_Sns 180;
BA_ "U_U611_U625_MY20_Phev_Tx" SG_ 827 LghtAmb_Intns_Sns 1;
BA_ "U_CX482_CX483_MY20_Hev_Tx" SG_ 827 LghtAmb_Intns_Sns 1;
BA_ "U_CX482_CX483_MY20_Gas_Tx" SG_ 827 LghtAmb_Intns_Sns 1;
BA_ "U_CX482_CX483_MY20_Diesel_Tx" SG_ 827 LghtAmb_Intns_Sns 1;
BA_ "U_U611_U625_MY20_Hev_Tx" SG_ 827 LghtAmb_Intns_Sns 1;
BA_ "U_U611_U625_MY20_Gas_Tx" SG_ 827 LghtAmb_Intns_Sns 1;
BA_ "U_U611_U625_MY20_Diesel_Tx" SG_ 827 LghtAmb_Intns_Sns 1;
BA_ "U_C519_MY18_5_Gas_Tx" SG_ 827 LghtAmb_Intns_Sns 1;
BA_ "U_C519_MY18_5_Diesel_Tx" SG_ 827 LghtAmb_Intns_Sns 1;
BA_ "U_B515_MCA_MY17_Gas_Tx" SG_ 827 LghtAmb_Intns_Sns 1;
BA_ "U_B515_MCA_MY17_Diesel_Tx" SG_ 827 LghtAmb_Intns_Sns 1;
BA_ "U_CX482_CX483_MY20_Hev_Rx" SG_ 848 RILStat 1;
BA_ "U_CX482_CX483_MY20_Gas_Rx" SG_ 848 RILStat 1;
BA_ "U_CX482_CX483_MY20_Diesel_Rx" SG_ 848 RILStat 1;
BA_ "U_U611_U625_MY20_Hev_Rx" SG_ 848 RILStat 1;
BA_ "U_U611_U625_MY20_Gas_Rx" SG_ 848 RILStat 1;
BA_ "U_U611_U625_MY20_Diesel_Rx" SG_ 848 RILStat 1;
BA_ "U_B500_MY18_Diesel_Rx" SG_ 848 RILStat 1;
BA_ "U_B500_MY18_Gas_Rx" SG_ 848 RILStat 1;
BA_ "U_C490_MY18_Rx" SG_ 848 RILStat 1;
BA_ "U_B562_MY18_Gas_Rx" SG_ 848 RILStat 1;
BA_ "U_C519_MY18_5_Gas_Rx" SG_ 848 RILStat 1;
BA_ "U_C519_MY18_5_Diesel_Rx" SG_ 848 RILStat 1;
BA_ "U_B515_MCA_MY17_Gas_Rx" SG_ 848 RILStat 1;
BA_ "U_B515_MCA_MY17_Diesel_Rx" SG_ 848 RILStat 1;
BA_ "U_B479_MY17_Diesel_Rx" SG_ 848 RILStat 1;
BA_ "U_B479_MY17_Gas_Rx" SG_ 848 RILStat 1;
BA_ "CrossOver_InfoCAN" SG_ 848 RILStat 1;
BA_ "GenSigSendType" SG_ 1822 TesterPhysicalResGWM_H2 3;
BA_ "U_CX482_CX483_MY20_Hev_Tx" SG_ 1896 TesterPhysicalResABS 1;
BA_ "U_CX482_CX483_MY20_Gas_Tx" SG_ 1896 TesterPhysicalResABS 1;
BA_ "U_CX482_CX483_MY20_Diesel_Tx" SG_ 1896 TesterPhysicalResABS 1;
BA_ "U_U611_U625_MY20_Hev_Tx" SG_ 1896 TesterPhysicalResABS 1;
BA_ "U_U611_U625_MY20_Gas_Tx" SG_ 1896 TesterPhysicalResABS 1;
BA_ "U_U611_U625_MY20_Diesel_Tx" SG_ 1896 TesterPhysicalResABS 1;
BA_ "U_B500_MY18_Diesel_Tx" SG_ 1896 TesterPhysicalResABS 1;
BA_ "U_B500_MY18_Gas_Tx" SG_ 1896 TesterPhysicalResABS 1;
BA_ "U_C490_MY18_Tx" SG_ 1896 TesterPhysicalResABS 1;
BA_ "U_B562_MY18_Gas_Tx" SG_ 1896 TesterPhysicalResABS 1;
BA_ "U_C519_MY18_5_Gas_Tx" SG_ 1896 TesterPhysicalResABS 1;
BA_ "U_C519_MY18_5_Diesel_Tx" SG_ 1896 TesterPhysicalResABS 1;
BA_ "U_B515_MCA_MY17_Gas_Tx" SG_ 1896 TesterPhysicalResABS 1;
BA_ "U_B515_MCA_MY17_Diesel_Tx" SG_ 1896 TesterPhysicalResABS 1;
BA_ "U_B479_MY17_Diesel_Tx" SG_ 1896 TesterPhysicalResABS 1;
BA_ "U_B479_MY17_Gas_Tx" SG_ 1896 TesterPhysicalResABS 1;
BA_ "U_B562LC_MY15_Gas_Tx" SG_ 1896 TesterPhysicalResABS 1;
BA_ "U_B562LC_MY15_Diesel_Tx" SG_ 1896 TesterPhysicalResABS 1;
BA_ "GenSigSendType" SG_ 1896 TesterPhysicalResABS 3;
BA_ "U_U611_U625_MY20_Phev_Tx" SG_ 1901 TesterPhysicalResOCS 1;
BA_ "U_CX482_CX483_MY20_Hev_Tx" SG_ 1901 TesterPhysicalResOCS 1;
BA_ "U_CX482_CX483_MY20_Gas_Tx" SG_ 1901 TesterPhysicalResOCS 1;
BA_ "U_CX482_CX483_MY20_Diesel_Tx" SG_ 1901 TesterPhysicalResOCS 1;
BA_ "U_U611_U625_MY20_Hev_Tx" SG_ 1901 TesterPhysicalResOCS 1;
BA_ "U_U611_U625_MY20_Gas_Tx" SG_ 1901 TesterPhysicalResOCS 1;
BA_ "U_U611_U625_MY20_Diesel_Tx" SG_ 1901 TesterPhysicalResOCS 1;
BA_ "U_C519_MY18_5_Gas_Tx" SG_ 1901 TesterPhysicalResOCS 1;
BA_ "U_C519_MY18_5_Diesel_Tx" SG_ 1901 TesterPhysicalResOCS 1;
BA_ "U_B515_MCA_MY17_Gas_Tx" SG_ 1901 TesterPhysicalResOCS 1;
BA_ "U_B515_MCA_MY17_Diesel_Tx" SG_ 1901 TesterPhysicalResOCS 1;
BA_ "U_B479_MY17_Diesel_Tx" SG_ 1901 TesterPhysicalResOCS 1;
BA_ "U_B479_MY17_Gas_Tx" SG_ 1901 TesterPhysicalResOCS 1;
BA_ "GenSigSendType" SG_ 1901 TesterPhysicalResOCS 3;
BA_ "U_U611_U625_MY20_Phev_Rx" SG_ 1893 TesterPhysicalReqOCS 1;
BA_ "U_CX482_CX483_MY20_Hev_Rx" SG_ 1893 TesterPhysicalReqOCS 1;
BA_ "U_CX482_CX483_MY20_Gas_Rx" SG_ 1893 TesterPhysicalReqOCS 1;
BA_ "U_CX482_CX483_MY20_Diesel_Rx" SG_ 1893 TesterPhysicalReqOCS 1;
BA_ "U_U611_U625_MY20_Hev_Rx" SG_ 1893 TesterPhysicalReqOCS 1;
BA_ "U_U611_U625_MY20_Gas_Rx" SG_ 1893 TesterPhysicalReqOCS 1;
BA_ "U_U611_U625_MY20_Diesel_Rx" SG_ 1893 TesterPhysicalReqOCS 1;
BA_ "U_C519_MY18_5_Gas_Rx" SG_ 1893 TesterPhysicalReqOCS 1;
BA_ "U_C519_MY18_5_Diesel_Rx" SG_ 1893 TesterPhysicalReqOCS 1;
BA_ "U_B515_MCA_MY17_Gas_Rx" SG_ 1893 TesterPhysicalReqOCS 1;
BA_ "U_B515_MCA_MY17_Diesel_Rx" SG_ 1893 TesterPhysicalReqOCS 1;
BA_ "U_B479_MY17_Diesel_Rx" SG_ 1893 TesterPhysicalReqOCS 1;
BA_ "U_B479_MY17_Gas_Rx" SG_ 1893 TesterPhysicalReqOCS 1;
BA_ "GenSigSendType" SG_ 1893 TesterPhysicalReqOCS 3;
BA_ "U_U611_U625_MY20_Hev_Tx" SG_ 1946 TesterPhysicalResATCM 1;
BA_ "U_U611_U625_MY20_Gas_Tx" SG_ 1946 TesterPhysicalResATCM 1;
BA_ "U_U611_U625_MY20_Diesel_Tx" SG_ 1946 TesterPhysicalResATCM 1;
BA_ "GenSigSendType" SG_ 1946 TesterPhysicalResATCM 3;
BA_ "GenSigSendType" SG_ 1887 TesterPhysicalResTBM 3;
BA_ "GenSigStartValue" SG_ 392 HudShifPoint_N_Actl 30;
BA_ "GenSigSendType" SG_ 392 HudMde_D_Stat 3;
BA_ "GenSigSendType" SG_ 392 HudLedMde_D_Stat 3;
BA_ "CrossOver_InfoCAN" SG_ 392 HudLedMde_D_Stat 1;
BA_ "GenSigSendType" SG_ 392 HudLed9On_B_Stat 3;
BA_ "GenSigSendType" SG_ 392 HudLed8On_B_Stat 3;
BA_ "GenSigSendType" SG_ 392 HudLed7On_B_Stat 3;
BA_ "U_U611_U625_MY20_Phev_Tx" SG_ 392 Hud_B_Falt 1;
BA_ "U_U611_U625_MY20_Hev_Tx" SG_ 392 Hud_B_Falt 1;
BA_ "U_U611_U625_MY20_Gas_Tx" SG_ 392 Hud_B_Falt 1;
BA_ "U_U611_U625_MY20_Diesel_Tx" SG_ 392 Hud_B_Falt 1;
BA_ "U_CX482_CX483_MY20_Hev_Rx" SG_ 392 Hud_B_Falt 1;
BA_ "U_CX482_CX483_MY20_Gas_Rx" SG_ 392 Hud_B_Falt 1;
BA_ "U_CX482_CX483_MY20_Diesel_Rx" SG_ 392 Hud_B_Falt 1;
BA_ "U_U611_U625_MY20_Hev_Rx" SG_ 392 Hud_B_Falt 1;
BA_ "U_U611_U625_MY20_Gas_Rx" SG_ 392 Hud_B_Falt 1;
BA_ "U_U611_U625_MY20_Diesel_Rx" SG_ 392 Hud_B_Falt 1;
BA_ "U_C519_MY18_5_Gas_Rx" SG_ 392 Hud_B_Falt 1;
BA_ "U_C519_MY18_5_Diesel_Rx" SG_ 392 Hud_B_Falt 1;
BA_ "GenSigSendType" SG_ 392 Hud_B_Falt 3;
BA_ "U_U611_U625_MY20_Phev_Tx" SG_ 392 HudActv_B_Actl 1;
BA_ "U_U611_U625_MY20_Hev_Tx" SG_ 392 HudActv_B_Actl 1;
BA_ "U_U611_U625_MY20_Gas_Tx" SG_ 392 HudActv_B_Actl 1;
BA_ "U_U611_U625_MY20_Diesel_Tx" SG_ 392 HudActv_B_Actl 1;
BA_ "U_CX482_CX483_MY20_Hev_Rx" SG_ 392 HudActv_B_Actl 1;
BA_ "U_CX482_CX483_MY20_Gas_Rx" SG_ 392 HudActv_B_Actl 1;
BA_ "U_CX482_CX483_MY20_Diesel_Rx" SG_ 392 HudActv_B_Actl 1;
BA_ "U_U611_U625_MY20_Hev_Rx" SG_ 392 HudActv_B_Actl 1;
BA_ "U_U611_U625_MY20_Gas_Rx" SG_ 392 HudActv_B_Actl 1;
BA_ "U_U611_U625_MY20_Diesel_Rx" SG_ 392 HudActv_B_Actl 1;
BA_ "U_C519_MY18_5_Gas_Rx" SG_ 392 HudActv_B_Actl 1;
BA_ "U_C519_MY18_5_Diesel_Rx" SG_ 392 HudActv_B_Actl 1;
BA_ "GenSigSendType" SG_ 392 HudActv_B_Actl 3;
BA_ "U_U611_U625_MY20_Phev_Tx" SG_ 392 Hud_B_Avail 1;
BA_ "U_U611_U625_MY20_Hev_Tx" SG_ 392 Hud_B_Avail 1;
BA_ "U_U611_U625_MY20_Gas_Tx" SG_ 392 Hud_B_Avail 1;
BA_ "U_U611_U625_MY20_Diesel_Tx" SG_ 392 Hud_B_Avail 1;
BA_ "U_CX482_CX483_MY20_Hev_Rx" SG_ 392 Hud_B_Avail 1;
BA_ "U_CX482_CX483_MY20_Gas_Rx" SG_ 392 Hud_B_Avail 1;
BA_ "U_CX482_CX483_MY20_Diesel_Rx" SG_ 392 Hud_B_Avail 1;
BA_ "U_U611_U625_MY20_Hev_Rx" SG_ 392 Hud_B_Avail 1;
BA_ "U_U611_U625_MY20_Gas_Rx" SG_ 392 Hud_B_Avail 1;
BA_ "U_U611_U625_MY20_Diesel_Rx" SG_ 392 Hud_B_Avail 1;
BA_ "U_C519_MY18_5_Gas_Rx" SG_ 392 Hud_B_Avail 1;
BA_ "U_C519_MY18_5_Diesel_Rx" SG_ 392 Hud_B_Avail 1;
BA_ "GenSigSendType" SG_ 392 Hud_B_Avail 3;
BA_ "GenSigStartValue" SG_ 392 Hud_B_Avail 1;
BA_ "GenSigSendType" SG_ 392 HudLed6On_B_Stat 3;
BA_ "GenSigSendType" SG_ 392 HudLed5On_B_Stat 3;
BA_ "GenSigSendType" SG_ 392 HudLed4On_B_Stat 3;
BA_ "GenSigSendType" SG_ 392 HudLed3On_B_Stat 3;
BA_ "GenSigSendType" SG_ 392 HudLed2On_B_Stat 3;
BA_ "GenSigSendType" SG_ 392 HudLed1On_B_Stat 3;
BA_ "GenSigSendType" SG_ 392 HudLed18On_B_Stat 3;
BA_ "GenSigSendType" SG_ 392 HudLed17On_B_Stat 3;
BA_ "GenSigSendType" SG_ 392 HudLed16On_B_Stat 3;
BA_ "GenSigSendType" SG_ 392 HudLed15On_B_Stat 3;
BA_ "GenSigSendType" SG_ 392 HudLed14On_B_Stat 3;
BA_ "GenSigSendType" SG_ 392 HudLed13On_B_Stat 3;
BA_ "GenSigSendType" SG_ 392 HudLed12On_B_Stat 3;
BA_ "GenSigSendType" SG_ 392 HudLed11On_B_Stat 3;
BA_ "GenSigSendType" SG_ 392 HudLed10On_B_Stat 3;
VAL_ 1093 TrlBrkInitOut_D_Stat 3 "Heavy" 2 "Medium" 1 "Light" 0 "Null" ;
VAL_ 1093 TrlrBrkMde_D_Actl 1 "Electric_Over_Hydraulic" 0 "Electric" ;
VAL_ 1093 TrlrBrkDsply_B_Rq 1 "Yes" 0 "No" ;
VAL_ 1093 TrlrBrkDcnnt_B_Actl 1 "Yes" 0 "No" ;
VAL_ 1093 TrlrBrkActCnnct_B_Actl 1 "Yes" 0 "No" ;
VAL_ 1093 StopLamp_B_RqTrlrBrk 1 "Yes" 0 "No" ;
VAL_ 1093 TrlrBrkCtl_B_Falt 1 "Yes" 0 "No" ;
VAL_ 1093 TrlrBrkActCirct_B_Falt 1 "Yes" 0 "No" ;
VAL_ 994 PersStore_D_Rq 7 "Unused_2" 6 "Unused_1" 5 "Vehicle" 4 "PERS_4" 3 "PERS_3" 2 "PERS_2" 1 "PERS_1" 0 "Null" ;
VAL_ 994 Pers4OptIn_B_Stats 1 "OPTED_IN" 0 "NOT_OPTED_IN" ;
VAL_ 994 CtrStkPersIndex_D_Actl 7 "Unused_3" 6 "Unused_2" 5 "Unused_1" 4 "Vehicle" 3 "PERS_4" 2 "PERS_3" 1 "PERS_2" 0 "PERS_1" ;
VAL_ 994 CtrStkDsplyOp_D_Rq 7 "Unused_2" 6 "Unused_1" 5 "Copy" 4 "Restore" 3 "Upload" 2 "Set" 1 "Query" 0 "Null" ;
VAL_ 994 Pers3OptIn_B_Stats 1 "OPTED_IN" 0 "NOT_OPTED_IN" ;
VAL_ 994 Pers2OptIn_B_Stats 1 "OPTED_IN" 0 "NOT_OPTED_IN" ;
VAL_ 994 Pers1OptIn_B_Stats 1 "OPTED_IN" 0 "NOT_OPTED_IN" ;
VAL_ 1108 RCMSerialNoByte8 255 "Invalid" 254 "Unknown" ;
VAL_ 1108 RCMSerialNoByte7 255 "Invalid" 254 "Unknown" ;
VAL_ 1108 RCMSerialNoByte6 255 "Invalid" 254 "Unknown" ;
VAL_ 1108 RCMSerialNoByte5 255 "Invalid" 254 "Unknown" ;
VAL_ 1108 RCMSerialNoByte4 255 "Invalid" 254 "Unknown" ;
VAL_ 1108 RCMSerialNoByte3 255 "Invalid" 254 "Unknown" ;
VAL_ 1108 RCMSerialNoByte2 255 "Invalid" 254 "Unknown" ;
VAL_ 1108 RCMSerialNoByte1 255 "Invalid" 254 "Unknown" ;
VAL_ 1107 OCSSerialNoByte8 255 "Invalid" 254 "Unknown" ;
VAL_ 1107 OCSSerialNoByte7 255 "Invalid" 254 "Unknown" ;
VAL_ 1107 OCSSerialNoByte6 255 "Invalid" 254 "Unknown" ;
VAL_ 1107 OCSSerialNoByte5 255 "Invalid" 254 "Unknown" ;
VAL_ 1107 OCSSerialNoByte4 255 "Invalid" 254 "Unknown" ;
VAL_ 1107 OCSSerialNoByte3 255 "Invalid" 254 "Unknown" ;
VAL_ 1107 OCSSerialNoByte2 255 "Invalid" 254 "Unknown" ;
VAL_ 1107 OCSSerialNoByte1 255 "Invalid" 254 "Unknown" ;
VAL_ 145 VehYawWActl_D_Qf 3 "OK" 2 "Not_Within_Specifications" 1 "No_Data_Exists" 0 "Faulty" ;
VAL_ 145 VehRolWActl_D_Qf 3 "OK" 2 "Not_Within_Specifications" 1 "No_Data_Exists" 0 "Faulty" ;
VAL_ 145 VehYaw_W_Actl 65535 "Faulty" 65534 "NoDataExists" ;
VAL_ 145 VehRol_W_Actl 65535 "Faulty" 65534 "NoDataExists" ;
VAL_ 1045 VehStab_D_Stat 15 "Faulty" 14 "No_Data_Exists" 13 "NotUsed6" 12 "NotUsed5" 11 "NotUsed4" 10 "NotUsed3" 9 "NotUsed2" 8 "NotUsed1" 7 "High_SSRA_no_OS" 6 "Straight" 5 "Post_Oversteer" 4 "Post_Transition" 3 "Countersteer" 2 "Understeer" 1 "Oversteer" 0 "Linear" ;
VAL_ 1045 BrkFluidLvl_D_Stat 3 "Invalid" 2 "Unknown" 1 "Low" 0 "OK" ;
VAL_ 1045 LsmcBrkDecel_D_Stat 7 "NotUsed_3" 6 "NotUsed_2" 5 "NotUsed_1" 4 "Denied" 3 "FaultDegraded" 2 "FaultExt" 1 "On" 0 "Off" ;
VAL_ 1045 VehYawNonLin_W_Rq 4095 "Fault" 4094 "Unknown" ;
VAL_ 1045 VehYawLin_W_Rq 4095 "Fault" 4094 "Unknown" ;
VAL_ 1045 VehVActlBrk_D_Qf 3 "OK" 2 "Not_Within_Specifications" 1 "No_Data_Exists" 0 "Faulty" ;
VAL_ 146 VehVert2_A_Actl 8191 "Faulty" 8190 "NoDataExists" ;
VAL_ 146 VehLong2_A_Actl 8191 "Faulty" 8190 "NoDataExists" ;
VAL_ 146 VehLat2_A_Actl 8191 "Faulty" 8190 "NoDataExists" ;
VAL_ 146 VehVertAActl_D_Qf 3 "OK" 2 "Not_Within_Specifications" 1 "No_Data_Exists" 0 "Faulty" ;
VAL_ 146 VehLongAActl_D_Qf 3 "OK" 2 "Not_Within_Specifications" 1 "No_Data_Exists" 0 "Faulty" ;
VAL_ 146 VehLatAActl_D_Qf 3 "OK" 2 "Not_Within_Specifications" 1 "No_Data_Exists" 0 "Faulty" ;
VAL_ 1152 HdcSwtchPos_B_Actl 1 "Pressed" 0 "Not_Pressed" ;
VAL_ 1152 TerrStat_D_RqDsply 15 "Reserved4" 14 "Reserved3" 13 "Reserved2" 12 "Crawl_Mode_4LOW_Reqd" 11 "Economy_Mode_Select" 10 "ModeChangeNotAvailable" 9 "Terrain_Sys_Not_Avail" 8 "Terrain_System_Fault" 7 "Mode_Change_InProgress" 6 "Dynamics_Mode_Select" 5 "Rock_Crawl_Mode_Select" 4 "Sand_Mode_Select" 3 "Mud_Ruts_Mode_Select" 2 "Low_Mu_Mode_Select" 1 "Special_Modes_Off" 0 "No_Message" ;
VAL_ 1152 TerrMde_D_RqDrv 7 "Fail_Safe_Default" 6 "Dynamic_Mode" 5 "Rock_Crawl_Mode" 4 "Mud_Ruts_Mode" 3 "Sand_Mode" 2 "Undefined" 1 "Low_Mu_Mode" 0 "Special_Operating_Mode_Off" ;
VAL_ 984 AhbHiBeam_D_Rq 3 "NotUsed" 2 "HighBeamRecommended" 1 "LowBeamRecommended" 0 "DeactivatedUnavailable" ;
VAL_ 984 CadsCamraStat_D_Qf 3 "OK" 2 "Not_Within_Specifications" 1 "No_Data_Exists" 0 "Faulty" ;
VAL_ 984 AhbcStat_B_Dsply 1 "On" 0 "Off" ;
VAL_ 984 LaSwtch_D_RqDrv 1 "Pressed" 0 "Not_Pressed" ;
VAL_ 984 AhbcHiBeam_D_Rq 3 "Deactivated_Unavailabl" 2 "Unused" 1 "Main_HighBeamRecommend" 0 "Dipped_LowBeamRecommend" ;
VAL_ 984 DasWarn_D_Dsply 3 "Undefined" 2 "Warning_Level_2" 1 "Warning_Level_1" 0 "No_Warning" ;
VAL_ 984 DasStats_D_Dsply 3 "Available" 2 "Unavailable_Other" 1 "Feedback_due_to_Speed" 0 "Off" ;
VAL_ 984 DasAlrtLvl_D_Dsply 5 "Alertness_Level_5" 4 "Alertness_Level_4" 3 "Alertness_Level_3" 2 "Alertness_Level_2" 1 "Alertness_Level_1" 0 "Undefined" ;
VAL_ 984 CamraStats_D_Dsply 3 "FrtCam_TempUnavailOther" 2 "FrtCam_TempUnavailVisibile" 1 "Front_Camera_Service_Reqd" 0 "Front_Camera_OK" ;
VAL_ 984 CamraDefog_B_Req 1 "On" 0 "Off" ;
VAL_ 984 LaHandsOff_D_Dsply 3 "Suppressed" 2 "Level2" 1 "Level1" 0 "HandsOn" ;
VAL_ 984 LaDenyStats_B_Dsply 1 "Unavailable" 0 "Available" ;
VAL_ 984 LaActvStats_D_Dsply 31 "Unused7" 30 "LA_Off" 29 "Unused5" 28 "Unused4" 27 "Unused3" 26 "Unused2" 25 "Unused1" 24 "InerveneLeft_InterveneRght" 23 "WarnLeft_InterveneRight" 22 "SuppressLeft_InterveneRght" 21 "AvailLeft_InterveneRhtt" 20 "NoLeft_InterveneRight" 19 "InterveneLeft_WarnRight" 18 "WarnLeft_WarnRight" 17 "SuppressLeft_WarnRight" 16 "AvailableLeft_WarnRight" 15 "NoLeft_WarnRight" 14 "InterveneLeft_SuppressRght" 13 "WarnLeft_SuppressRight" 12 "SuppressLeft_SuppressRight" 11 "AvailLeft_SuppressRight" 10 "NoLeft_SuppressRight" 9 "InterveneLeft_AvailRight" 8 "WarnLeft_AvailRight" 7 "SuppressLeft_AvailRight" 6 "AvailableLeft_AvailRight" 5 "NoLeft_AvailableRight" 4 "InterveneLeft_NoRight" 3 "WarnLeft_NoRight" 2 "SuppressLeft_NoRight" 1 "AvailableLeft_NoRight" 0 "NoLeft_NoRight" ;
VAL_ 984 AhbcRampingV_D_Rq 3 "Slow" 2 "Medium" 1 "Fast" 0 "Immediately" ;
VAL_ 984 PersIndexIpma_D_Actl 7 "Unused_3" 6 "Unused_2" 5 "Unused_1" 4 "Vehicle" 3 "PERS_4" 2 "PERS_3" 1 "PERS_2" 0 "PERS_1" ;
VAL_ 998 PersIndexSccm_D_Actl 7 "Unused_3" 6 "Unused_2" 5 "Unused_1" 4 "Vehicle" 3 "PERS_4" 2 "PERS_3" 1 "PERS_2" 0 "PERS_1" ;
VAL_ 997 PersIndexCcm_D_Actl 7 "Unused_3" 6 "Unused_2" 5 "Unused_1" 4 "Vehicle" 3 "PERS_4" 2 "PERS_3" 1 "PERS_2" 0 "PERS_1" ;
VAL_ 613 BeltWarnThres_D_Stat 7 "Faulty" 6 "No_Data_Exists" 5 "NotUsed3" 4 "NotUsed2" 3 "NotUsed1" 2 "Over_Threshold" 1 "Under_Threshold" 0 "NotSupported" ;
VAL_ 613 VehicleMYCalibrationId 255 "Invalid" ;
VAL_ 613 VehicleCalibrationId 255 "Invalid" ;
VAL_ 613 OCSSensrDataUpperLim 255 "Invalid" ;
VAL_ 613 OCSSensrDataLowerLim 255 "Invalid" ;
VAL_ 613 OCSLevel2Error 1 "Yes" 0 "No" ;
VAL_ 613 ObjectEntrapped 1 "Yes" 0 "No" ;
VAL_ 613 OCSLevel1Error 1 "Yes" 0 "No" ;
VAL_ 130 TrlrHitchLamp_D_Rqst 1 "On" 0 "Off" ;
VAL_ 130 VehVTrlrAid_B_Rq 1 "Request" 0 "NoRequest" ;
VAL_ 130 SteEffort_D_Stat 7 "NotUsed_3" 6 "NotUsed_2" 5 "NotUsed_1" 4 "SpecialMode_2" 3 "SpecialMode_1" 2 "Comfort" 1 "Sport" 0 "Normal" ;
VAL_ 130 DrvSteActv_B_Stat 1 "Active" 0 "Inactive" ;
VAL_ 130 DrvSte_Tq_Actl 255 "Invalid" 254 "Unknown" ;
VAL_ 130 SteMdule_D_Stat 7 "NotUsed" 6 "EPAS_Failure3" 5 "EPAS_Failure2" 4 "System_Failure" 3 "EPAS_Shutdown" 2 "Normal_Op_Full_Assist" 1 "Normal_Op_Limited_Assist" 0 "EPAS_Initialization" ;
VAL_ 130 SteMdule_U_Meas 255 "Invalid" ;
VAL_ 130 SteMdule_I_Est 4095 "Invalid" ;
VAL_ 130 EPAS_Failure 3 "SERVICE_POWER_STEERING_NOW" 2 "SERVICE_POWER_STEERING" 1 "POWER_STRG_ASSIST_FAULT" 0 "EPAS_OK_NO_MESSAGE" ;
VAL_ 130 SteeringColumnTorque 255 "Invalid" 254 "Unknown" ;
VAL_ 130 SAPPAngleControlStat6 1 "RequestedAngleNotReached" 0 "RequestedAngleCanBeReached" ;
VAL_ 130 SAPPAngleControlStat5 1 "StrgColTorqueExceed_EAROn" 0 "ExternalSigContentOKforEAC" ;
VAL_ 130 SAPPAngleControlStat4 1 "SpeedLimitExceededEAROn" 0 "ExternalSigContentOKforEAC" ;
VAL_ 130 SAPPAngleControlStat3 1 "EARactiveNoReverseEngage" 0 "ExternalSigContentOKforEAC" ;
VAL_ 130 SAPPAngleControlStat2 1 "Rel_ExtSteeringAngleReqx" 0 "NoRel_ExtSteeringAngleReqx" ;
VAL_ 130 SAPPAngleControlStat1 3 "Fault" 2 "Active" 1 "Open" 0 "Closed" ;
VAL_ 827 SteClmnSwtchTlt_D_Stat 3 "Unused" 2 "Down" 1 "Up" 0 "Null" ;
VAL_ 827 SteClmnSwtchTel_D_Stat 3 "Unused" 2 "Rearward" 1 "Forward" 0 "Null" ;
VAL_ 827 LghtAmbIntns_D_Sns 3 "Faulty" 2 "High" 1 "Low" 0 "Null" ;
VAL_ 848 RILStat 3 "Fault" 2 "Plant_Mode" 1 "On" 0 "Off" ;
VAL_ 392 HudMde_D_Stat 7 "NotUsed3" 6 "NotUsed2" 5 "NotUsed1" 4 "Manual" 3 "Drag" 2 "RoadCourse" 1 "Tach" 0 "Off" ;
VAL_ 392 HudLedMde_D_Stat 3 "Not_Used" 2 "Flash" 1 "On" 0 "Off" ;
VAL_ 392 HudLed9On_B_Stat 1 "On" 0 "Off" ;
VAL_ 392 HudLed8On_B_Stat 1 "On" 0 "Off" ;
VAL_ 392 HudLed7On_B_Stat 1 "On" 0 "Off" ;
VAL_ 392 Hud_B_Falt 1 "Yes" 0 "No" ;
VAL_ 392 HudActv_B_Actl 1 "Yes" 0 "No" ;
VAL_ 392 Hud_B_Avail 1 "Yes" 0 "No" ;
VAL_ 392 HudLed6On_B_Stat 1 "On" 0 "Off" ;
VAL_ 392 HudLed5On_B_Stat 1 "On" 0 "Off" ;
VAL_ 392 HudLed4On_B_Stat 1 "On" 0 "Off" ;
VAL_ 392 HudLed3On_B_Stat 1 "On" 0 "Off" ;
VAL_ 392 HudLed2On_B_Stat 1 "On" 0 "Off" ;
VAL_ 392 HudLed1On_B_Stat 1 "On" 0 "Off" ;
VAL_ 392 HudLed18On_B_Stat 1 "On" 0 "Off" ;
VAL_ 392 HudLed17On_B_Stat 1 "On" 0 "Off" ;
VAL_ 392 HudLed16On_B_Stat 1 "On" 0 "Off" ;
VAL_ 392 HudLed15On_B_Stat 1 "On" 0 "Off" ;
VAL_ 392 HudLed14On_B_Stat 1 "On" 0 "Off" ;
VAL_ 392 HudLed13On_B_Stat 1 "On" 0 "Off" ;
VAL_ 392 HudLed12On_B_Stat 1 "On" 0 "Off" ;
VAL_ 392 HudLed11On_B_Stat 1 "On" 0 "Off" ;
VAL_ 392 HudLed10On_B_Stat 1 "On" 0 "Off" ;
